VERSION "HNNBNNNYNNNNNNNNNNNNNNNNNNNNNNNNNNNNNNNNNN/4/%%%/4/'%**4NNN///"

NS_ :

BS_:

BU_: Radar MPC2

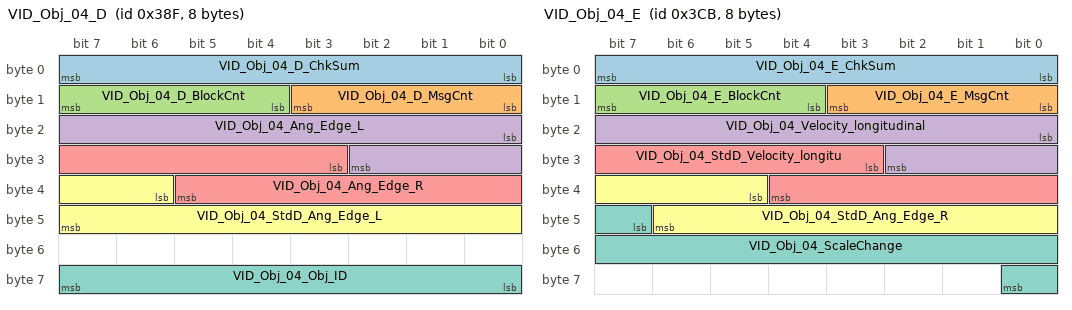
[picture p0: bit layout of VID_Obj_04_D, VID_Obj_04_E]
BO_ 911 VID_Obj_04_D: 8 MPC2
 SG_ VID_Obj_04_D_ChkSum : 0|8@1+ (1,0) [0|255] ""  Radar
 SG_ VID_Obj_04_D_MsgCnt : 8|4@1+ (1,0) [0|15] ""  Radar
 SG_ VID_Obj_04_D_BlockCnt : 12|4@1+ (1,0) [0|15] ""  Radar
 SG_ VID_Obj_04_Ang_Edge_L : 16|11@1+ (0.00048828125,-0.5) [-0.5|0.49951171875] "Unit_Radia"  Radar
 SG_ VID_Obj_04_Ang_Edge_R : 27|11@1+ (0.00048828125,-0.5) [-0.5|0.49951171875] "Unit_Radia"  Radar
 SG_ VID_Obj_04_StdD_Ang_Edge_L : 38|10@1+ (0.00048828125,-0.25) [-0.25|0.24951171875] "Unit_Radia"  Radar
 SG_ VID_Obj_04_Obj_ID : 56|8@1+ (1,0) [1|254] ""  Radar

BO_ 971 VID_Obj_04_E: 8 MPC2
 SG_ VID_Obj_04_E_ChkSum : 0|8@1+ (1,0) [0|255] ""  Radar
 SG_ VID_Obj_04_E_MsgCnt : 8|4@1+ (1,0) [0|15] ""  Radar
 SG_ VID_Obj_04_E_BlockCnt : 12|4@1+ (1,0) [0|15] ""  Radar
 SG_ VID_Obj_04_Velocity_longitudinal : 16|11@1+ (0.01388889,-12) [-12|12.00000192] "Unit_MeterPerSecon"  Radar
 SG_ VID_Obj_04_StdD_Velocity_longitu : 27|10@1+ (0.00694444,0) [0|6.0069406] "Unit_MeterPerSecon"  Radar
 SG_ VID_Obj_04_StdD_Ang_Edge_R : 37|10@1+ (0.00048828125,-0.25) [-0.25|0.24951171875] "Unit_Radia"  Radar
 SG_ VID_Obj_04_ScaleChange : 47|10@1+ (0.001,0.5) [0.5|1.5] ""  Radar

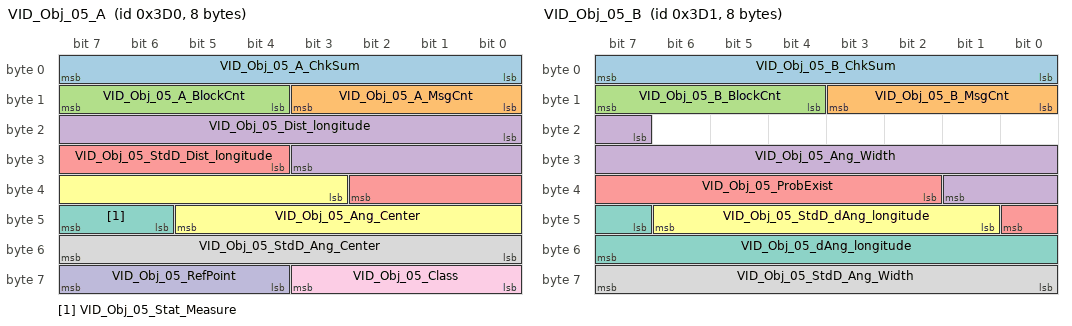
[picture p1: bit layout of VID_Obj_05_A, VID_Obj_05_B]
BO_ 976 VID_Obj_05_A: 8 MPC2
 SG_ VID_Obj_05_A_ChkSum : 0|8@1+ (1,0) [0|255] ""  Radar
 SG_ VID_Obj_05_A_MsgCnt : 8|4@1+ (1,0) [0|15] ""  Radar
 SG_ VID_Obj_05_A_BlockCnt : 12|4@1+ (1,0) [0|15] ""  Radar
 SG_ VID_Obj_05_Dist_longitude : 16|12@1+ (0.0625,0) [0|255.875] "Unit_Meter"  Radar
 SG_ VID_Obj_05_StdD_Dist_longitude : 28|7@1+ (0.25,0) [0|31.5] "Unit_Meter"  Radar
 SG_ VID_Obj_05_Ang_Center : 35|11@1+ (0.00048828125,-0.5) [-0.5|0.4990234375] "Unit_Radia"  Radar
 SG_ VID_Obj_05_Stat_Measure : 46|2@1+ (1,0) [0|3] ""  Radar
 SG_ VID_Obj_05_StdD_Ang_Center : 48|8@1+ (0.0009765625,0) [0|0.248046875] "Unit_Radia"  Radar
 SG_ VID_Obj_05_Class : 56|4@1+ (1,0) [0|15] ""  Radar
 SG_ VID_Obj_05_RefPoint : 60|4@1+ (1,0) [0|15] ""  Radar

BO_ 977 VID_Obj_05_B: 8 MPC2
 SG_ VID_Obj_05_B_ChkSum : 0|8@1+ (1,0) [0|255] ""  Radar
 SG_ VID_Obj_05_B_MsgCnt : 8|4@1+ (1,0) [0|15] ""  Radar
 SG_ VID_Obj_05_B_BlockCnt : 12|4@1+ (1,0) [0|15] ""  Radar
 SG_ VID_Obj_05_Ang_Width : 23|11@1+ (0.00048828125,0) [0|0.9990234375] "Unit_Radia"  Radar
 SG_ VID_Obj_05_ProbExist : 34|7@1+ (0.0078125,0.015625) [0.015625|1] ""  Radar
 SG_ VID_Obj_05_StdD_dAng_longitude : 41|6@1+ (0.01,0) [0|0.62] "Unit_RadiaPerSecon"  Radar
 SG_ VID_Obj_05_dAng_longitude : 47|9@1+ (0.005,-1.25) [-1.25|1.3] "Unit_RadiaPerSecon"  Radar
 SG_ VID_Obj_05_StdD_Ang_Width : 56|8@1+ (0.0009765625,0) [0|0.248046875] "Unit_Radia"  Radar

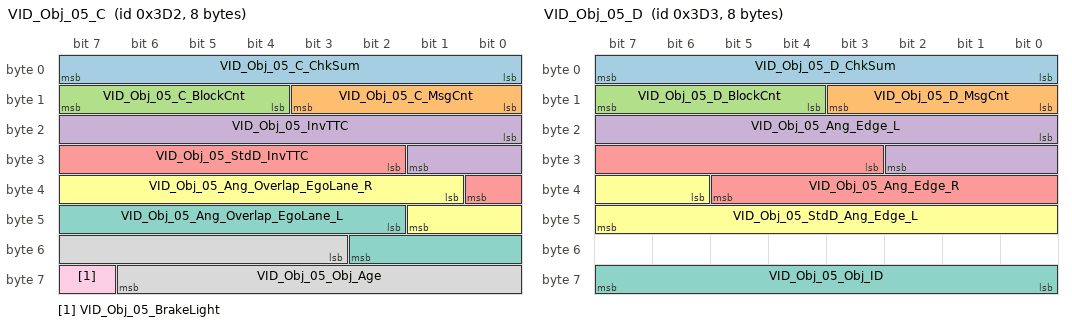
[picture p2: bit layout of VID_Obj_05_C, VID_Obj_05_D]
BO_ 978 VID_Obj_05_C: 8 MPC2
 SG_ VID_Obj_05_C_ChkSum : 0|8@1+ (1,0) [0|255] ""  Radar
 SG_ VID_Obj_05_C_MsgCnt : 8|4@1+ (1,0) [0|15] ""  Radar
 SG_ VID_Obj_05_C_BlockCnt : 12|4@1+ (1,0) [0|15] ""  Radar
 SG_ VID_Obj_05_InvTTC : 16|10@1+ (0.015625,-8) [-8|7.96875] "Unit_Hertz"  Radar
 SG_ VID_Obj_05_StdD_InvTTC : 26|7@1+ (0.0625,0) [0|7.875] "Unit_Hertz"  Radar
 SG_ VID_Obj_05_Ang_Overlap_EgoLane_R : 33|9@1+ (0.0009765625,-0.25) [-0.25|0.248046875] "Unit_Radia"  Radar
 SG_ VID_Obj_05_Ang_Overlap_EgoLane_L : 42|9@1+ (0.0009765625,-0.25) [-0.25|0.248046875] "Unit_Radia"  Radar
 SG_ VID_Obj_05_Obj_Age : 51|12@1+ (1,0) [0|4094] ""  Radar
 SG_ VID_Obj_05_BrakeLight : 63|1@1+ (1,0) [0|1] ""  Radar

BO_ 979 VID_Obj_05_D: 8 MPC2
 SG_ VID_Obj_05_D_ChkSum : 0|8@1+ (1,0) [0|255] ""  Radar
 SG_ VID_Obj_05_D_MsgCnt : 8|4@1+ (1,0) [0|15] ""  Radar
 SG_ VID_Obj_05_D_BlockCnt : 12|4@1+ (1,0) [0|15] ""  Radar
 SG_ VID_Obj_05_Ang_Edge_L : 16|11@1+ (0.00048828125,-0.5) [-0.5|0.49951171875] "Unit_Radia"  Radar
 SG_ VID_Obj_05_Ang_Edge_R : 27|11@1+ (0.00048828125,-0.5) [-0.5|0.49951171875] "Unit_Radia"  Radar
 SG_ VID_Obj_05_StdD_Ang_Edge_L : 38|10@1+ (0.00048828125,-0.25) [-0.25|0.24951171875] "Unit_Radia"  Radar
 SG_ VID_Obj_05_Obj_ID : 56|8@1+ (1,0) [1|254] ""  Radar

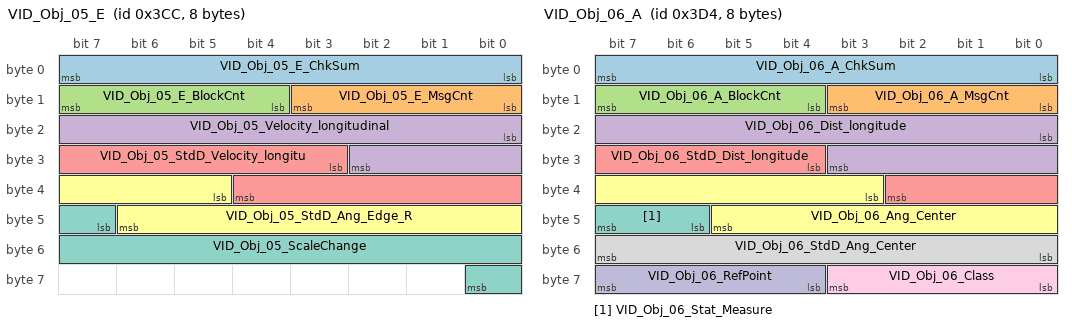
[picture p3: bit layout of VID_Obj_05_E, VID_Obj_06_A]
BO_ 972 VID_Obj_05_E: 8 MPC2
 SG_ VID_Obj_05_E_ChkSum : 0|8@1+ (1,0) [0|255] ""  Radar
 SG_ VID_Obj_05_E_MsgCnt : 8|4@1+ (1,0) [0|15] ""  Radar
 SG_ VID_Obj_05_E_BlockCnt : 12|4@1+ (1,0) [0|15] ""  Radar
 SG_ VID_Obj_05_Velocity_longitudinal : 16|11@1+ (0.01388889,-12) [-12|12.00000192] "Unit_MeterPerSecon"  Radar
 SG_ VID_Obj_05_StdD_Velocity_longitu : 27|10@1+ (0.00694444,0) [0|6.0069406] "Unit_MeterPerSecon"  Radar
 SG_ VID_Obj_05_StdD_Ang_Edge_R : 37|10@1+ (0.00048828125,-0.25) [-0.25|0.24951171875] "Unit_Radia"  Radar
 SG_ VID_Obj_05_ScaleChange : 47|10@1+ (0.001,0.5) [0.5|1.5] ""  Radar

BO_ 980 VID_Obj_06_A: 8 MPC2
 SG_ VID_Obj_06_A_ChkSum : 0|8@1+ (1,0) [0|255] ""  Radar
 SG_ VID_Obj_06_A_MsgCnt : 8|4@1+ (1,0) [0|15] ""  Radar
 SG_ VID_Obj_06_A_BlockCnt : 12|4@1+ (1,0) [0|15] ""  Radar
 SG_ VID_Obj_06_Dist_longitude : 16|12@1+ (0.0625,0) [0|255.875] "Unit_Meter"  Radar
 SG_ VID_Obj_06_StdD_Dist_longitude : 28|7@1+ (0.25,0) [0|31.5] "Unit_Meter"  Radar
 SG_ VID_Obj_06_Ang_Center : 35|11@1+ (0.00048828125,-0.5) [-0.5|0.4990234375] "Unit_Radia"  Radar
 SG_ VID_Obj_06_Stat_Measure : 46|2@1+ (1,0) [0|3] ""  Radar
 SG_ VID_Obj_06_StdD_Ang_Center : 48|8@1+ (0.0009765625,0) [0|0.248046875] "Unit_Radia"  Radar
 SG_ VID_Obj_06_Class : 56|4@1+ (1,0) [0|15] ""  Radar
 SG_ VID_Obj_06_RefPoint : 60|4@1+ (1,0) [0|15] ""  Radar

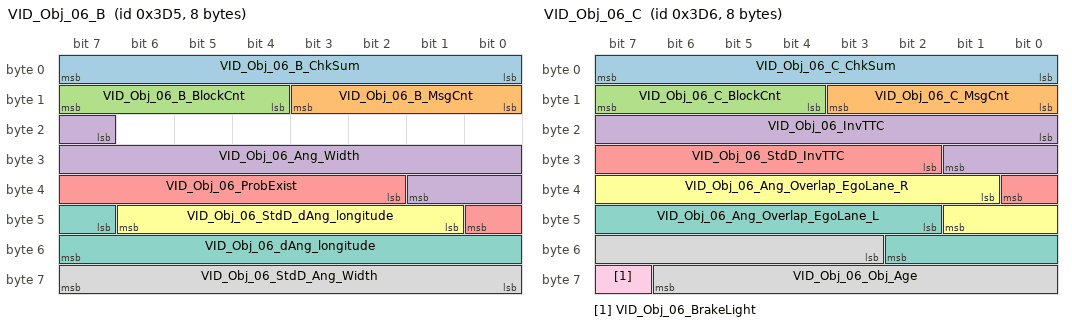
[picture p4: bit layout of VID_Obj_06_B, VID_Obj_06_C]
BO_ 981 VID_Obj_06_B: 8 MPC2
 SG_ VID_Obj_06_B_ChkSum : 0|8@1+ (1,0) [0|255] ""  Radar
 SG_ VID_Obj_06_B_MsgCnt : 8|4@1+ (1,0) [0|15] ""  Radar
 SG_ VID_Obj_06_B_BlockCnt : 12|4@1+ (1,0) [0|15] ""  Radar
 SG_ VID_Obj_06_Ang_Width : 23|11@1+ (0.00048828125,0) [0|0.9990234375] "Unit_Radia"  Radar
 SG_ VID_Obj_06_ProbExist : 34|7@1+ (0.0078125,0.015625) [0.015625|1] ""  Radar
 SG_ VID_Obj_06_StdD_dAng_longitude : 41|6@1+ (0.01,0) [0|0.62] "Unit_RadiaPerSecon"  Radar
 SG_ VID_Obj_06_dAng_longitude : 47|9@1+ (0.005,-1.25) [-1.25|1.3] "Unit_RadiaPerSecon"  Radar
 SG_ VID_Obj_06_StdD_Ang_Width : 56|8@1+ (0.0009765625,0) [0|0.248046875] "Unit_Radia"  Radar

BO_ 982 VID_Obj_06_C: 8 MPC2
 SG_ VID_Obj_06_C_ChkSum : 0|8@1+ (1,0) [0|255] ""  Radar
 SG_ VID_Obj_06_C_MsgCnt : 8|4@1+ (1,0) [0|15] ""  Radar
 SG_ VID_Obj_06_C_BlockCnt : 12|4@1+ (1,0) [0|15] ""  Radar
 SG_ VID_Obj_06_InvTTC : 16|10@1+ (0.015625,-8) [-8|7.96875] "Unit_Hertz"  Radar
 SG_ VID_Obj_06_StdD_InvTTC : 26|7@1+ (0.0625,0) [0|7.875] "Unit_Hertz"  Radar
 SG_ VID_Obj_06_Ang_Overlap_EgoLane_R : 33|9@1+ (0.0009765625,-0.25) [-0.25|0.248046875] "Unit_Radia"  Radar
 SG_ VID_Obj_06_Ang_Overlap_EgoLane_L : 42|9@1+ (0.0009765625,-0.25) [-0.25|0.248046875] "Unit_Radia"  Radar
 SG_ VID_Obj_06_Obj_Age : 51|12@1+ (1,0) [0|4094] ""  Radar
 SG_ VID_Obj_06_BrakeLight : 63|1@1+ (1,0) [0|1] ""  Radar

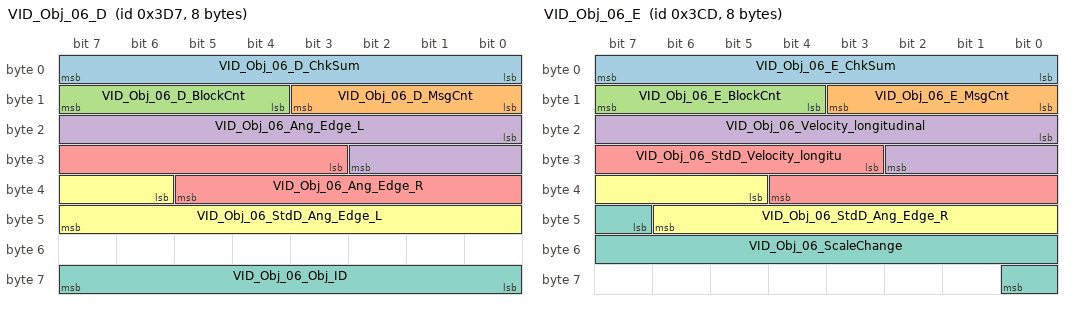
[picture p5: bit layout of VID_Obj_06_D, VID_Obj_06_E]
BO_ 983 VID_Obj_06_D: 8 MPC2
 SG_ VID_Obj_06_D_ChkSum : 0|8@1+ (1,0) [0|255] ""  Radar
 SG_ VID_Obj_06_D_MsgCnt : 8|4@1+ (1,0) [0|15] ""  Radar
 SG_ VID_Obj_06_D_BlockCnt : 12|4@1+ (1,0) [0|15] ""  Radar
 SG_ VID_Obj_06_Ang_Edge_L : 16|11@1+ (0.00048828125,-0.5) [-0.5|0.49951171875] "Unit_Radia"  Radar
 SG_ VID_Obj_06_Ang_Edge_R : 27|11@1+ (0.00048828125,-0.5) [-0.5|0.49951171875] "Unit_Radia"  Radar
 SG_ VID_Obj_06_StdD_Ang_Edge_L : 38|10@1+ (0.00048828125,-0.25) [-0.25|0.24951171875] "Unit_Radia"  Radar
 SG_ VID_Obj_06_Obj_ID : 56|8@1+ (1,0) [1|254] ""  Radar

BO_ 973 VID_Obj_06_E: 8 MPC2
 SG_ VID_Obj_06_E_ChkSum : 0|8@1+ (1,0) [0|255] ""  Radar
 SG_ VID_Obj_06_E_MsgCnt : 8|4@1+ (1,0) [0|15] ""  Radar
 SG_ VID_Obj_06_E_BlockCnt : 12|4@1+ (1,0) [0|15] ""  Radar
 SG_ VID_Obj_06_Velocity_longitudinal : 16|11@1+ (0.01388889,-12) [-12|12.00000192] "Unit_MeterPerSecon"  Radar
 SG_ VID_Obj_06_StdD_Velocity_longitu : 27|10@1+ (0.00694444,0) [0|6.0069406] "Unit_MeterPerSecon"  Radar
 SG_ VID_Obj_06_StdD_Ang_Edge_R : 37|10@1+ (0.00048828125,-0.25) [-0.25|0.24951171875] "Unit_Radia"  Radar
 SG_ VID_Obj_06_ScaleChange : 47|10@1+ (0.001,0.5) [0.5|1.5] ""  Radar

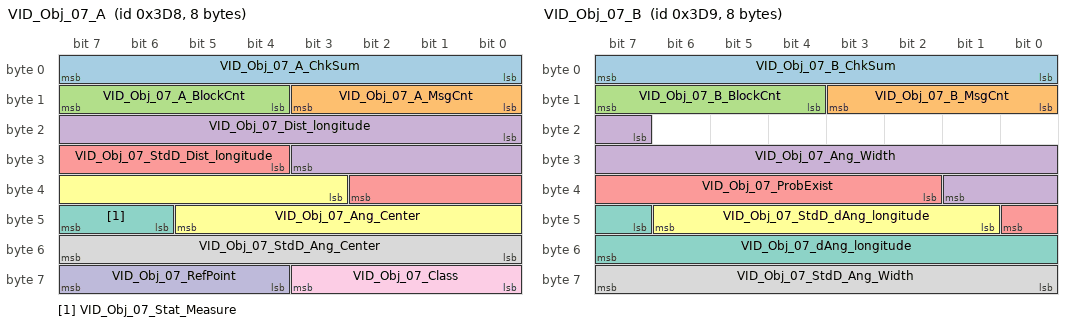
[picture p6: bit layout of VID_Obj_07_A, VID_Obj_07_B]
BO_ 984 VID_Obj_07_A: 8 MPC2
 SG_ VID_Obj_07_A_ChkSum : 0|8@1+ (1,0) [0|255] ""  Radar
 SG_ VID_Obj_07_A_MsgCnt : 8|4@1+ (1,0) [0|15] ""  Radar
 SG_ VID_Obj_07_A_BlockCnt : 12|4@1+ (1,0) [0|15] ""  Radar
 SG_ VID_Obj_07_Dist_longitude : 16|12@1+ (0.0625,0) [0|255.875] "Unit_Meter"  Radar
 SG_ VID_Obj_07_StdD_Dist_longitude : 28|7@1+ (0.25,0) [0|31.5] "Unit_Meter"  Radar
 SG_ VID_Obj_07_Ang_Center : 35|11@1+ (0.00048828125,-0.5) [-0.5|0.4990234375] "Unit_Radia"  Radar
 SG_ VID_Obj_07_Stat_Measure : 46|2@1+ (1,0) [0|3] ""  Radar
 SG_ VID_Obj_07_StdD_Ang_Center : 48|8@1+ (0.0009765625,0) [0|0.248046875] "Unit_Radia"  Radar
 SG_ VID_Obj_07_Class : 56|4@1+ (1,0) [0|15] ""  Radar
 SG_ VID_Obj_07_RefPoint : 60|4@1+ (1,0) [0|15] ""  Radar

BO_ 985 VID_Obj_07_B: 8 MPC2
 SG_ VID_Obj_07_B_ChkSum : 0|8@1+ (1,0) [0|255] ""  Radar
 SG_ VID_Obj_07_B_MsgCnt : 8|4@1+ (1,0) [0|15] ""  Radar
 SG_ VID_Obj_07_B_BlockCnt : 12|4@1+ (1,0) [0|15] ""  Radar
 SG_ VID_Obj_07_Ang_Width : 23|11@1+ (0.00048828125,0) [0|0.9990234375] "Unit_Radia"  Radar
 SG_ VID_Obj_07_ProbExist : 34|7@1+ (0.0078125,0.015625) [0.015625|1] ""  Radar
 SG_ VID_Obj_07_StdD_dAng_longitude : 41|6@1+ (0.01,0) [0|0.62] "Unit_RadiaPerSecon"  Radar
 SG_ VID_Obj_07_dAng_longitude : 47|9@1+ (0.005,-1.25) [-1.25|1.3] "Unit_RadiaPerSecon"  Radar
 SG_ VID_Obj_07_StdD_Ang_Width : 56|8@1+ (0.0009765625,0) [0|0.248046875] "Unit_Radia"  Radar

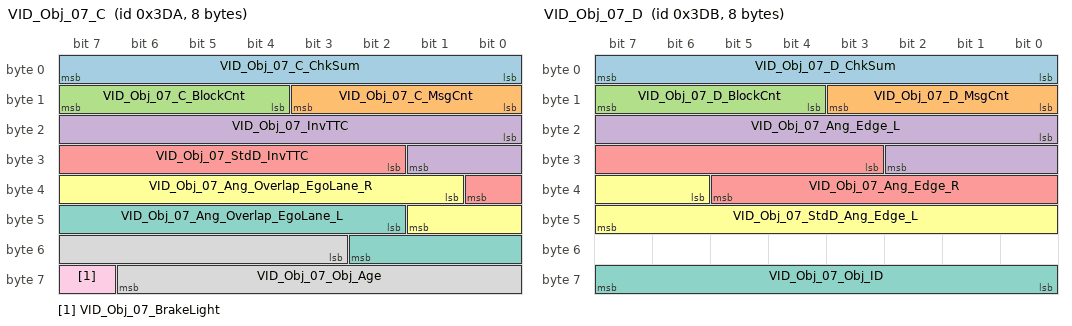
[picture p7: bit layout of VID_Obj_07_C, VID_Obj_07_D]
BO_ 986 VID_Obj_07_C: 8 MPC2
 SG_ VID_Obj_07_C_ChkSum : 0|8@1+ (1,0) [0|255] ""  Radar
 SG_ VID_Obj_07_C_MsgCnt : 8|4@1+ (1,0) [0|15] ""  Radar
 SG_ VID_Obj_07_C_BlockCnt : 12|4@1+ (1,0) [0|15] ""  Radar
 SG_ VID_Obj_07_InvTTC : 16|10@1+ (0.015625,-8) [-8|7.96875] "Unit_Hertz"  Radar
 SG_ VID_Obj_07_StdD_InvTTC : 26|7@1+ (0.0625,0) [0|7.875] "Unit_Hertz"  Radar
 SG_ VID_Obj_07_Ang_Overlap_EgoLane_R : 33|9@1+ (0.0009765625,-0.25) [-0.25|0.248046875] "Unit_Radia"  Radar
 SG_ VID_Obj_07_Ang_Overlap_EgoLane_L : 42|9@1+ (0.0009765625,-0.25) [-0.25|0.248046875] "Unit_Radia"  Radar
 SG_ VID_Obj_07_Obj_Age : 51|12@1+ (1,0) [0|4094] ""  Radar
 SG_ VID_Obj_07_BrakeLight : 63|1@1+ (1,0) [0|1] ""  Radar

BO_ 987 VID_Obj_07_D: 8 MPC2
 SG_ VID_Obj_07_D_ChkSum : 0|8@1+ (1,0) [0|255] ""  Radar
 SG_ VID_Obj_07_D_MsgCnt : 8|4@1+ (1,0) [0|15] ""  Radar
 SG_ VID_Obj_07_D_BlockCnt : 12|4@1+ (1,0) [0|15] ""  Radar
 SG_ VID_Obj_07_Ang_Edge_L : 16|11@1+ (0.00048828125,-0.5) [-0.5|0.49951171875] "Unit_Radia"  Radar
 SG_ VID_Obj_07_Ang_Edge_R : 27|11@1+ (0.00048828125,-0.5) [-0.5|0.49951171875] "Unit_Radia"  Radar
 SG_ VID_Obj_07_StdD_Ang_Edge_L : 38|10@1+ (0.00048828125,-0.25) [-0.25|0.24951171875] "Unit_Radia"  Radar
 SG_ VID_Obj_07_Obj_ID : 56|8@1+ (1,0) [1|254] ""  Radar

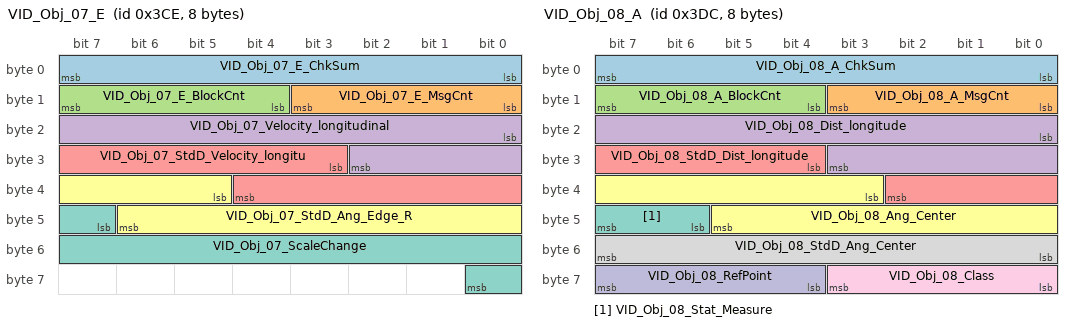
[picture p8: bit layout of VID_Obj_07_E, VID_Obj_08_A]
BO_ 974 VID_Obj_07_E: 8 MPC2
 SG_ VID_Obj_07_E_ChkSum : 0|8@1+ (1,0) [0|255] ""  Radar
 SG_ VID_Obj_07_E_MsgCnt : 8|4@1+ (1,0) [0|15] ""  Radar
 SG_ VID_Obj_07_E_BlockCnt : 12|4@1+ (1,0) [0|15] ""  Radar
 SG_ VID_Obj_07_Velocity_longitudinal : 16|11@1+ (0.01388889,-12) [-12|12.00000192] "Unit_MeterPerSecon"  Radar
 SG_ VID_Obj_07_StdD_Velocity_longitu : 27|10@1+ (0.00694444,0) [0|6.0069406] "Unit_MeterPerSecon"  Radar
 SG_ VID_Obj_07_StdD_Ang_Edge_R : 37|10@1+ (0.00048828125,-0.25) [-0.25|0.24951171875] "Unit_Radia"  Radar
 SG_ VID_Obj_07_ScaleChange : 47|10@1+ (0.001,0.5) [0.5|1.5] ""  Radar

BO_ 988 VID_Obj_08_A: 8 MPC2
 SG_ VID_Obj_08_A_ChkSum : 0|8@1+ (1,0) [0|255] ""  Radar
 SG_ VID_Obj_08_A_MsgCnt : 8|4@1+ (1,0) [0|15] ""  Radar
 SG_ VID_Obj_08_A_BlockCnt : 12|4@1+ (1,0) [0|15] ""  Radar
 SG_ VID_Obj_08_Dist_longitude : 16|12@1+ (0.0625,0) [0|255.875] "Unit_Meter"  Radar
 SG_ VID_Obj_08_StdD_Dist_longitude : 28|7@1+ (0.25,0) [0|31.5] "Unit_Meter"  Radar
 SG_ VID_Obj_08_Ang_Center : 35|11@1+ (0.00048828125,-0.5) [-0.5|0.4990234375] "Unit_Radia"  Radar
 SG_ VID_Obj_08_Stat_Measure : 46|2@1+ (1,0) [0|3] ""  Radar
 SG_ VID_Obj_08_StdD_Ang_Center : 48|8@1+ (0.0009765625,0) [0|0.248046875] "Unit_Radia"  Radar
 SG_ VID_Obj_08_Class : 56|4@1+ (1,0) [0|15] ""  Radar
 SG_ VID_Obj_08_RefPoint : 60|4@1+ (1,0) [0|15] ""  Radar

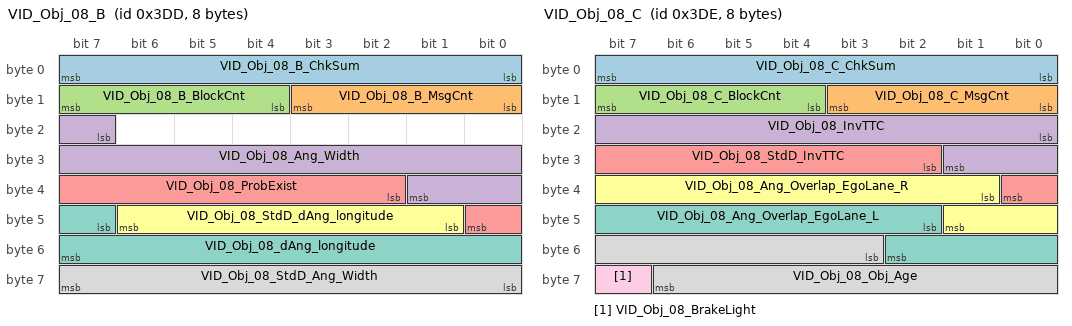
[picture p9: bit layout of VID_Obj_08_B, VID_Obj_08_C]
BO_ 989 VID_Obj_08_B: 8 MPC2
 SG_ VID_Obj_08_B_ChkSum : 0|8@1+ (1,0) [0|255] ""  Radar
 SG_ VID_Obj_08_B_MsgCnt : 8|4@1+ (1,0) [0|15] ""  Radar
 SG_ VID_Obj_08_B_BlockCnt : 12|4@1+ (1,0) [0|15] ""  Radar
 SG_ VID_Obj_08_Ang_Width : 23|11@1+ (0.00048828125,0) [0|0.9990234375] "Unit_Radia"  Radar
 SG_ VID_Obj_08_ProbExist : 34|7@1+ (0.0078125,0.015625) [0.015625|1] ""  Radar
 SG_ VID_Obj_08_StdD_dAng_longitude : 41|6@1+ (0.01,0) [0|0.62] "Unit_RadiaPerSecon"  Radar
 SG_ VID_Obj_08_dAng_longitude : 47|9@1+ (0.005,-1.25) [-1.25|1.3] "Unit_RadiaPerSecon"  Radar
 SG_ VID_Obj_08_StdD_Ang_Width : 56|8@1+ (0.0009765625,0) [0|0.248046875] "Unit_Radia"  Radar

BO_ 990 VID_Obj_08_C: 8 MPC2
 SG_ VID_Obj_08_C_ChkSum : 0|8@1+ (1,0) [0|255] ""  Radar
 SG_ VID_Obj_08_C_MsgCnt : 8|4@1+ (1,0) [0|15] ""  Radar
 SG_ VID_Obj_08_C_BlockCnt : 12|4@1+ (1,0) [0|15] ""  Radar
 SG_ VID_Obj_08_InvTTC : 16|10@1+ (0.015625,-8) [-8|7.96875] "Unit_Hertz"  Radar
 SG_ VID_Obj_08_StdD_InvTTC : 26|7@1+ (0.0625,0) [0|7.875] "Unit_Hertz"  Radar
 SG_ VID_Obj_08_Ang_Overlap_EgoLane_R : 33|9@1+ (0.0009765625,-0.25) [-0.25|0.248046875] "Unit_Radia"  Radar
 SG_ VID_Obj_08_Ang_Overlap_EgoLane_L : 42|9@1+ (0.0009765625,-0.25) [-0.25|0.248046875] "Unit_Radia"  Radar
 SG_ VID_Obj_08_Obj_Age : 51|12@1+ (1,0) [0|4094] ""  Radar
 SG_ VID_Obj_08_BrakeLight : 63|1@1+ (1,0) [0|1] ""  Radar

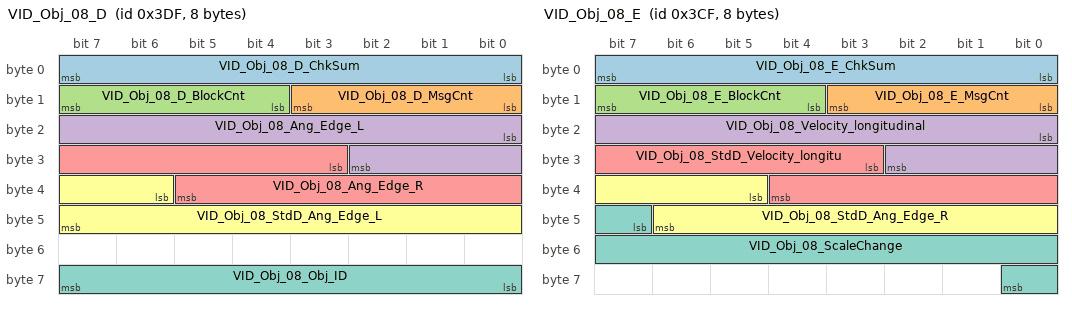
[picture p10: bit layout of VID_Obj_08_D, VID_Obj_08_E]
BO_ 991 VID_Obj_08_D: 8 MPC2
 SG_ VID_Obj_08_D_ChkSum : 0|8@1+ (1,0) [0|255] ""  Radar
 SG_ VID_Obj_08_D_MsgCnt : 8|4@1+ (1,0) [0|15] ""  Radar
 SG_ VID_Obj_08_D_BlockCnt : 12|4@1+ (1,0) [0|15] ""  Radar
 SG_ VID_Obj_08_Ang_Edge_L : 16|11@1+ (0.00048828125,-0.5) [-0.5|0.49951171875] "Unit_Radia"  Radar
 SG_ VID_Obj_08_Ang_Edge_R : 27|11@1+ (0.00048828125,-0.5) [-0.5|0.49951171875] "Unit_Radia"  Radar
 SG_ VID_Obj_08_StdD_Ang_Edge_L : 38|10@1+ (0.00048828125,-0.25) [-0.25|0.24951171875] "Unit_Radia"  Radar
 SG_ VID_Obj_08_Obj_ID : 56|8@1+ (1,0) [1|254] ""  Radar

BO_ 975 VID_Obj_08_E: 8 MPC2
 SG_ VID_Obj_08_E_ChkSum : 0|8@1+ (1,0) [0|255] ""  Radar
 SG_ VID_Obj_08_E_MsgCnt : 8|4@1+ (1,0) [0|15] ""  Radar
 SG_ VID_Obj_08_E_BlockCnt : 12|4@1+ (1,0) [0|15] ""  Radar
 SG_ VID_Obj_08_Velocity_longitudinal : 16|11@1+ (0.01388889,-12) [-12|12.00000192] "Unit_MeterPerSecon"  Radar
 SG_ VID_Obj_08_StdD_Velocity_longitu : 27|10@1+ (0.00694444,0) [0|6.0069406] "Unit_MeterPerSecon"  Radar
 SG_ VID_Obj_08_StdD_Ang_Edge_R : 37|10@1+ (0.00048828125,-0.25) [-0.25|0.24951171875] "Unit_Radia"  Radar
 SG_ VID_Obj_08_ScaleChange : 47|10@1+ (0.001,0.5) [0.5|1.5] ""  Radar

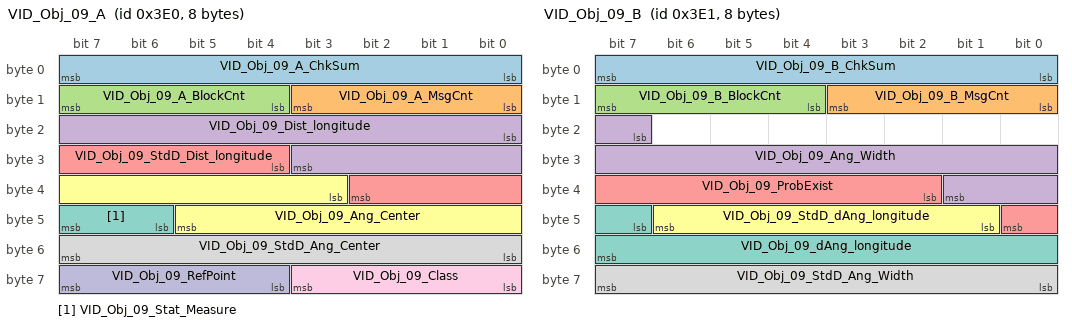
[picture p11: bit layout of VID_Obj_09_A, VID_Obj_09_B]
BO_ 992 VID_Obj_09_A: 8 MPC2
 SG_ VID_Obj_09_A_ChkSum : 0|8@1+ (1,0) [0|255] ""  Radar
 SG_ VID_Obj_09_A_MsgCnt : 8|4@1+ (1,0) [0|15] ""  Radar
 SG_ VID_Obj_09_A_BlockCnt : 12|4@1+ (1,0) [0|15] ""  Radar
 SG_ VID_Obj_09_Dist_longitude : 16|12@1+ (0.0625,0) [0|255.875] "Unit_Meter"  Radar
 SG_ VID_Obj_09_StdD_Dist_longitude : 28|7@1+ (0.25,0) [0|31.5] "Unit_Meter"  Radar
 SG_ VID_Obj_09_Ang_Center : 35|11@1+ (0.00048828125,-0.5) [-0.5|0.4990234375] "Unit_Radia"  Radar
 SG_ VID_Obj_09_Stat_Measure : 46|2@1+ (1,0) [0|3] ""  Radar
 SG_ VID_Obj_09_StdD_Ang_Center : 48|8@1+ (0.0009765625,0) [0|0.248046875] "Unit_Radia"  Radar
 SG_ VID_Obj_09_Class : 56|4@1+ (1,0) [0|15] ""  Radar
 SG_ VID_Obj_09_RefPoint : 60|4@1+ (1,0) [0|15] ""  Radar

BO_ 993 VID_Obj_09_B: 8 MPC2
 SG_ VID_Obj_09_B_ChkSum : 0|8@1+ (1,0) [0|255] ""  Radar
 SG_ VID_Obj_09_B_MsgCnt : 8|4@1+ (1,0) [0|15] ""  Radar
 SG_ VID_Obj_09_B_BlockCnt : 12|4@1+ (1,0) [0|15] ""  Radar
 SG_ VID_Obj_09_Ang_Width : 23|11@1+ (0.00048828125,0) [0|0.9990234375] "Unit_Radia"  Radar
 SG_ VID_Obj_09_ProbExist : 34|7@1+ (0.0078125,0.015625) [0.015625|1] ""  Radar
 SG_ VID_Obj_09_StdD_dAng_longitude : 41|6@1+ (0.01,0) [0|0.62] "Unit_RadiaPerSecon"  Radar
 SG_ VID_Obj_09_dAng_longitude : 47|9@1+ (0.005,-1.25) [-1.25|1.3] "Unit_RadiaPerSecon"  Radar
 SG_ VID_Obj_09_StdD_Ang_Width : 56|8@1+ (0.0009765625,0) [0|0.248046875] "Unit_Radia"  Radar

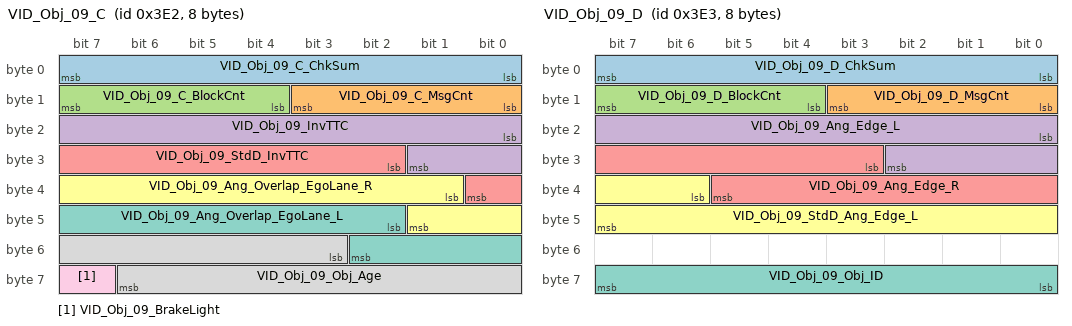
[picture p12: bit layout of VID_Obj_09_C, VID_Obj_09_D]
BO_ 994 VID_Obj_09_C: 8 MPC2
 SG_ VID_Obj_09_C_ChkSum : 0|8@1+ (1,0) [0|255] ""  Radar
 SG_ VID_Obj_09_C_MsgCnt : 8|4@1+ (1,0) [0|15] ""  Radar
 SG_ VID_Obj_09_C_BlockCnt : 12|4@1+ (1,0) [0|15] ""  Radar
 SG_ VID_Obj_09_InvTTC : 16|10@1+ (0.015625,-8) [-8|7.96875] "Unit_Hertz"  Radar
 SG_ VID_Obj_09_StdD_InvTTC : 26|7@1+ (0.0625,0) [0|7.875] "Unit_Hertz"  Radar
 SG_ VID_Obj_09_Ang_Overlap_EgoLane_R : 33|9@1+ (0.0009765625,-0.25) [-0.25|0.248046875] "Unit_Radia"  Radar
 SG_ VID_Obj_09_Ang_Overlap_EgoLane_L : 42|9@1+ (0.0009765625,-0.25) [-0.25|0.248046875] "Unit_Radia"  Radar
 SG_ VID_Obj_09_Obj_Age : 51|12@1+ (1,0) [0|4094] ""  Radar
 SG_ VID_Obj_09_BrakeLight : 63|1@1+ (1,0) [0|1] ""  Radar

BO_ 995 VID_Obj_09_D: 8 MPC2
 SG_ VID_Obj_09_D_ChkSum : 0|8@1+ (1,0) [0|255] ""  Radar
 SG_ VID_Obj_09_D_MsgCnt : 8|4@1+ (1,0) [0|15] ""  Radar
 SG_ VID_Obj_09_D_BlockCnt : 12|4@1+ (1,0) [0|15] ""  Radar
 SG_ VID_Obj_09_Ang_Edge_L : 16|11@1+ (0.00048828125,-0.5) [-0.5|0.49951171875] "Unit_Radia"  Radar
 SG_ VID_Obj_09_Ang_Edge_R : 27|11@1+ (0.00048828125,-0.5) [-0.5|0.49951171875] "Unit_Radia"  Radar
 SG_ VID_Obj_09_StdD_Ang_Edge_L : 38|10@1+ (0.00048828125,-0.25) [-0.25|0.24951171875] "Unit_Radia"  Radar
 SG_ VID_Obj_09_Obj_ID : 56|8@1+ (1,0) [1|254] ""  Radar

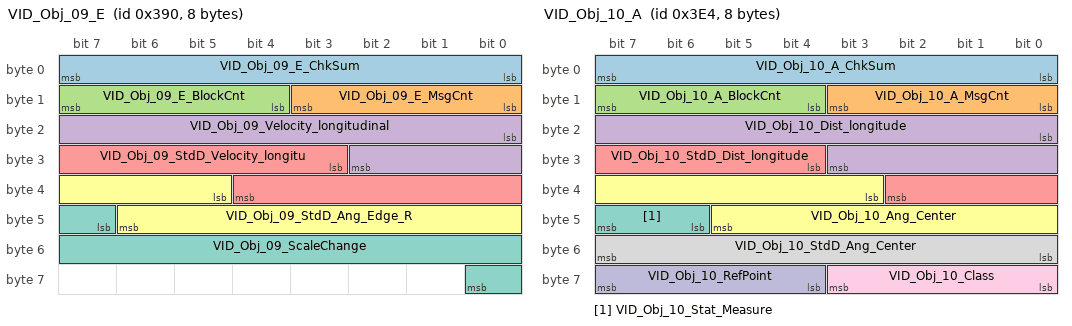
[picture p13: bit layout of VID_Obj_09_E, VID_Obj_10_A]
BO_ 912 VID_Obj_09_E: 8 MPC2
 SG_ VID_Obj_09_E_ChkSum : 0|8@1+ (1,0) [0|255] ""  Radar
 SG_ VID_Obj_09_E_MsgCnt : 8|4@1+ (1,0) [0|15] ""  Radar
 SG_ VID_Obj_09_E_BlockCnt : 12|4@1+ (1,0) [0|15] ""  Radar
 SG_ VID_Obj_09_Velocity_longitudinal : 16|11@1+ (0.01388889,-12) [-12|12.00000192] "Unit_MeterPerSecon"  Radar
 SG_ VID_Obj_09_StdD_Velocity_longitu : 27|10@1+ (0.00694444,0) [0|6.0069406] "Unit_MeterPerSecon"  Radar
 SG_ VID_Obj_09_StdD_Ang_Edge_R : 37|10@1+ (0.00048828125,-0.25) [-0.25|0.24951171875] "Unit_Radia"  Radar
 SG_ VID_Obj_09_ScaleChange : 47|10@1+ (0.001,0.5) [0.5|1.5] ""  Radar

BO_ 996 VID_Obj_10_A: 8 MPC2
 SG_ VID_Obj_10_A_ChkSum : 0|8@1+ (1,0) [0|255] ""  Radar
 SG_ VID_Obj_10_A_MsgCnt : 8|4@1+ (1,0) [0|15] ""  Radar
 SG_ VID_Obj_10_A_BlockCnt : 12|4@1+ (1,0) [0|15] ""  Radar
 SG_ VID_Obj_10_Dist_longitude : 16|12@1+ (0.0625,0) [0|255.875] "Unit_Meter"  Radar
 SG_ VID_Obj_10_StdD_Dist_longitude : 28|7@1+ (0.25,0) [0|31.5] "Unit_Meter"  Radar
 SG_ VID_Obj_10_Ang_Center : 35|11@1+ (0.00048828125,-0.5) [-0.5|0.4990234375] "Unit_Radia"  Radar
 SG_ VID_Obj_10_Stat_Measure : 46|2@1+ (1,0) [0|3] ""  Radar
 SG_ VID_Obj_10_StdD_Ang_Center : 48|8@1+ (0.0009765625,0) [0|0.248046875] "Unit_Radia"  Radar
 SG_ VID_Obj_10_Class : 56|4@1+ (1,0) [0|15] ""  Radar
 SG_ VID_Obj_10_RefPoint : 60|4@1+ (1,0) [0|15] ""  Radar

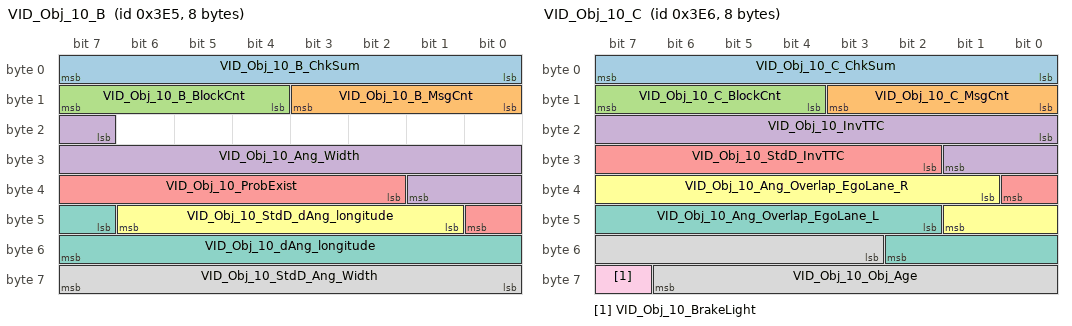
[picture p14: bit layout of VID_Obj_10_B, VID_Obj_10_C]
BO_ 997 VID_Obj_10_B: 8 MPC2
 SG_ VID_Obj_10_B_ChkSum : 0|8@1+ (1,0) [0|255] ""  Radar
 SG_ VID_Obj_10_B_MsgCnt : 8|4@1+ (1,0) [0|15] ""  Radar
 SG_ VID_Obj_10_B_BlockCnt : 12|4@1+ (1,0) [0|15] ""  Radar
 SG_ VID_Obj_10_Ang_Width : 23|11@1+ (0.00048828125,0) [0|0.9990234375] "Unit_Radia"  Radar
 SG_ VID_Obj_10_ProbExist : 34|7@1+ (0.0078125,0.015625) [0.015625|1] ""  Radar
 SG_ VID_Obj_10_StdD_dAng_longitude : 41|6@1+ (0.01,0) [0|0.62] "Unit_RadiaPerSecon"  Radar
 SG_ VID_Obj_10_dAng_longitude : 47|9@1+ (0.005,-1.25) [-1.25|1.3] "Unit_RadiaPerSecon"  Radar
 SG_ VID_Obj_10_StdD_Ang_Width : 56|8@1+ (0.0009765625,0) [0|0.248046875] "Unit_Radia"  Radar

BO_ 998 VID_Obj_10_C: 8 MPC2
 SG_ VID_Obj_10_C_ChkSum : 0|8@1+ (1,0) [0|255] ""  Radar
 SG_ VID_Obj_10_C_MsgCnt : 8|4@1+ (1,0) [0|15] ""  Radar
 SG_ VID_Obj_10_C_BlockCnt : 12|4@1+ (1,0) [0|15] ""  Radar
 SG_ VID_Obj_10_InvTTC : 16|10@1+ (0.015625,-8) [-8|7.96875] "Unit_Hertz"  Radar
 SG_ VID_Obj_10_StdD_InvTTC : 26|7@1+ (0.0625,0) [0|7.875] "Unit_Hertz"  Radar
 SG_ VID_Obj_10_Ang_Overlap_EgoLane_R : 33|9@1+ (0.0009765625,-0.25) [-0.25|0.248046875] "Unit_Radia"  Radar
 SG_ VID_Obj_10_Ang_Overlap_EgoLane_L : 42|9@1+ (0.0009765625,-0.25) [-0.25|0.248046875] "Unit_Radia"  Radar
 SG_ VID_Obj_10_Obj_Age : 51|12@1+ (1,0) [0|4094] ""  Radar
 SG_ VID_Obj_10_BrakeLight : 63|1@1+ (1,0) [0|1] ""  Radar

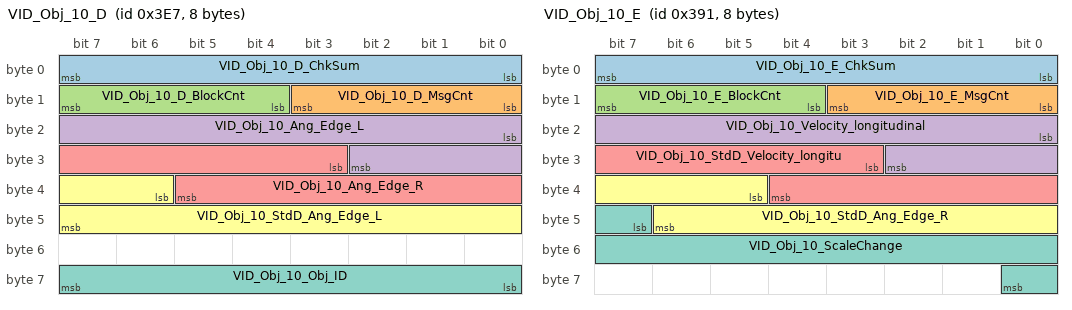
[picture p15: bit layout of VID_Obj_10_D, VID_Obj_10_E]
BO_ 999 VID_Obj_10_D: 8 MPC2
 SG_ VID_Obj_10_D_ChkSum : 0|8@1+ (1,0) [0|255] ""  Radar
 SG_ VID_Obj_10_D_MsgCnt : 8|4@1+ (1,0) [0|15] ""  Radar
 SG_ VID_Obj_10_D_BlockCnt : 12|4@1+ (1,0) [0|15] ""  Radar
 SG_ VID_Obj_10_Ang_Edge_L : 16|11@1+ (0.00048828125,-0.5) [-0.5|0.49951171875] "Unit_Radia"  Radar
 SG_ VID_Obj_10_Ang_Edge_R : 27|11@1+ (0.00048828125,-0.5) [-0.5|0.49951171875] "Unit_Radia"  Radar
 SG_ VID_Obj_10_StdD_Ang_Edge_L : 38|10@1+ (0.00048828125,-0.25) [-0.25|0.24951171875] "Unit_Radia"  Radar
 SG_ VID_Obj_10_Obj_ID : 56|8@1+ (1,0) [1|254] ""  Radar

BO_ 913 VID_Obj_10_E: 8 MPC2
 SG_ VID_Obj_10_E_ChkSum : 0|8@1+ (1,0) [0|255] ""  Radar
 SG_ VID_Obj_10_E_MsgCnt : 8|4@1+ (1,0) [0|15] ""  Radar
 SG_ VID_Obj_10_E_BlockCnt : 12|4@1+ (1,0) [0|15] ""  Radar
 SG_ VID_Obj_10_Velocity_longitudinal : 16|11@1+ (0.01388889,-12) [-12|12.00000192] "Unit_MeterPerSecon"  Radar
 SG_ VID_Obj_10_StdD_Velocity_longitu : 27|10@1+ (0.00694444,0) [0|6.0069406] "Unit_MeterPerSecon"  Radar
 SG_ VID_Obj_10_StdD_Ang_Edge_R : 37|10@1+ (0.00048828125,-0.25) [-0.25|0.24951171875] "Unit_Radia"  Radar
 SG_ VID_Obj_10_ScaleChange : 47|10@1+ (0.001,0.5) [0.5|1.5] ""  Radar

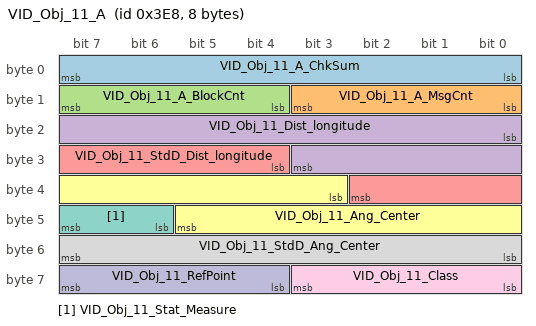
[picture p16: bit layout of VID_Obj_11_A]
BO_ 1000 VID_Obj_11_A: 8 MPC2
 SG_ VID_Obj_11_A_ChkSum : 0|8@1+ (1,0) [0|255] ""  Radar
 SG_ VID_Obj_11_A_MsgCnt : 8|4@1+ (1,0) [0|15] ""  Radar
 SG_ VID_Obj_11_A_BlockCnt : 12|4@1+ (1,0) [0|15] ""  Radar
 SG_ VID_Obj_11_Dist_longitude : 16|12@1+ (0.0625,0) [0|255.875] "Unit_Meter"  Radar
 SG_ VID_Obj_11_StdD_Dist_longitude : 28|7@1+ (0.25,0) [0|31.5] "Unit_Meter"  Radar
 SG_ VID_Obj_11_Ang_Center : 35|11@1+ (0.00048828125,-0.5) [-0.5|0.4990234375] "Unit_Radia"  Radar
 SG_ VID_Obj_11_Stat_Measure : 46|2@1+ (1,0) [0|3] ""  Radar
 SG_ VID_Obj_11_StdD_Ang_Center : 48|8@1+ (0.0009765625,0) [0|0.248046875] "Unit_Radia"  Radar
 SG_ VID_Obj_11_Class : 56|4@1+ (1,0) [0|15] ""  Radar
 SG_ VID_Obj_11_RefPoint : 60|4@1+ (1,0) [0|15] ""  Radar

CM_ SG_ 911 VID_Obj_04_D_ChkSum "CRC8 Checksum";
CM_ SG_ 911 VID_Obj_04_D_MsgCnt "Message counter (rolling counter)";
CM_ SG_ 911 VID_Obj_04_D_BlockCnt "Control signal to synchronize segmented blocks of object data";
CM_ SG_ 911 VID_Obj_04_Ang_Edge_L "Angle of the left edge of the object
Conversion factor 2^-11";
CM_ SG_ 911 VID_Obj_04_Ang_Edge_R "Angle of the right edge of the object
Conversion factor 2^-11";
CM_ SG_ 911 VID_Obj_04_StdD_Ang_Edge_L "Standard deviation for the Angle of the left edge of the object";
CM_ SG_ 911 VID_Obj_04_Obj_ID "ID of the object";
CM_ SG_ 971 VID_Obj_04_E_ChkSum "CRC8 Checksum";
CM_ SG_ 971 VID_Obj_04_E_MsgCnt "Message counter (rolling counter)";
CM_ SG_ 971 VID_Obj_04_E_BlockCnt "Control signal to synchronize segmented blocks of object data";
CM_ SG_ 971 VID_Obj_04_Velocity_longitudinal "Longitudinal velocity of the detected object (Vehicle coordinate system)";
CM_ SG_ 971 VID_Obj_04_StdD_Velocity_longitu "Standard deviation of the Longitudinal velocity of the detected object (Vehicle coordinate system)";
CM_ SG_ 971 VID_Obj_04_StdD_Ang_Edge_R "Standard deviation for the Angle of the right edge of the object";
CM_ SG_ 971 VID_Obj_04_ScaleChange "In order to fuse a video object with a radar object at higher distance (>60m), a higher resolution for the  relative velocity is needed in that range. This signal indicates the required change of the scale.";
CM_ SG_ 976 VID_Obj_05_A_ChkSum "CRC8 Checksum";
CM_ SG_ 976 VID_Obj_05_A_MsgCnt "Message counter (rolling counter)";
CM_ SG_ 976 VID_Obj_05_A_BlockCnt "Control signal to synchronize segmented blocks of object data";
CM_ SG_ 976 VID_Obj_05_Dist_longitude "Longitudinal distance relative to vehicle coordinate system";
CM_ SG_ 976 VID_Obj_05_StdD_Dist_longitude "Standard deviation for VID_Obj_05_Dist_longitude";
CM_ SG_ 976 VID_Obj_05_Ang_Center "Center of the recorded side of the 3D-object box (positive angle left of x-axis).
(Mono-Video: Rear view for vehicles). In combination with Obj_Angle_low the center
base point of the objectis described.
Coordinate system: transformed";
CM_ SG_ 976 VID_Obj_05_Stat_Measure "Object measured tracked

0 Object not measured but predicted based on 3D-model
1 Object was measured in current sample cycle
2 Object not measured but re-matched based on feature tracking";
CM_ SG_ 976 VID_Obj_05_StdD_Ang_Center "Standard deviation for VID_Obj_05_Ang_Center";
CM_ SG_ 976 VID_Obj_05_Class "Object class";
CM_ SG_ 976 VID_Obj_05_RefPoint "Index of the reference point for the 3D-object box
Info: The wording front/rear right/left relates to the indicated object orientation.
If this data is not available then a orienntation can be chosen.";
CM_ SG_ 977 VID_Obj_05_B_ChkSum "CRC8 Checksum";
CM_ SG_ 977 VID_Obj_05_B_MsgCnt "Message counter (rolling counter)";
CM_ SG_ 977 VID_Obj_05_B_BlockCnt "Control signal to synchronize segmented blocks of object data";
CM_ SG_ 977 VID_Obj_05_Ang_Width "Width of the recorded side of the 3D-object box (positive angle left of x-axis)
Monovideo: Rear view for vehicles
Coordinate system: Transformed coordinate system with camera being origin
! Ego-movement has to be compensated !";
CM_ SG_ 977 VID_Obj_05_ProbExist "Probability for the existence of an object for the given time and position (in 3sigma-area)";
CM_ SG_ 977 VID_Obj_05_StdD_dAng_longitude "Standard deviation for VID_Obj_05_dAng_longitude";
CM_ SG_ 977 VID_Obj_05_dAng_longitude "Lateral velocity of the object (related to the reference point), calculated as change of angle in the frame";
CM_ SG_ 977 VID_Obj_05_StdD_Ang_Width "Standard deviation for VID_Obj_05_Ang_Width";
CM_ SG_ 978 VID_Obj_05_C_ChkSum "CRC8 Checksum";
CM_ SG_ 978 VID_Obj_05_C_MsgCnt "Message counter (rolling counter)";
CM_ SG_ 978 VID_Obj_05_C_BlockCnt "Control signal to synchronize segmented blocks of object data";
CM_ SG_ 978 VID_Obj_05_InvTTC "Inverted value of the time-to-collision with the vertical plane of the camera ";
CM_ SG_ 978 VID_Obj_05_StdD_InvTTC "Standard deviation for VID_Obj_05_InvTTC";
CM_ SG_ 978 VID_Obj_05_Ang_Overlap_EgoLane_R "Object Line Assignment (angle based indicator for the overlap of a an object with the ego lane from the right corner)";
CM_ SG_ 978 VID_Obj_05_Ang_Overlap_EgoLane_L "Object Line Assignment (angle based indicator for the overlap of a an object with the ego lane from the left corner)";
CM_ SG_ 978 VID_Obj_05_Obj_Age "Cycle counter for the existence of the object (object sampled)";
CM_ SG_ 978 VID_Obj_05_BrakeLight "Brake light recognized on the object";
CM_ SG_ 979 VID_Obj_05_D_ChkSum "CRC8 Checksum";
CM_ SG_ 979 VID_Obj_05_D_MsgCnt "Message counter (rolling counter)";
CM_ SG_ 979 VID_Obj_05_D_BlockCnt "Control signal to synchronize segmented blocks of object data";
CM_ SG_ 979 VID_Obj_05_Ang_Edge_L "Angle of the left edge of the object
Conversion factor 2^-11";
CM_ SG_ 979 VID_Obj_05_Ang_Edge_R "Angle of the right edge of the object
Conversion factor 2^-11";
CM_ SG_ 979 VID_Obj_05_StdD_Ang_Edge_L "Standard deviation for the Angle of the left edge of the object";
CM_ SG_ 979 VID_Obj_05_Obj_ID "ID of the object";
CM_ SG_ 972 VID_Obj_05_E_ChkSum "CRC8 Checksum";
CM_ SG_ 972 VID_Obj_05_E_MsgCnt "Message counter (rolling counter)";
CM_ SG_ 972 VID_Obj_05_E_BlockCnt "Control signal to synchronize segmented blocks of object data";
CM_ SG_ 972 VID_Obj_05_Velocity_longitudinal "Longitudinal velocity of the detected object (Vehicle coordinate system)";
CM_ SG_ 972 VID_Obj_05_StdD_Velocity_longitu "Standard deviation of the Longitudinal velocity of the detected object (Vehicle coordinate system)";
CM_ SG_ 972 VID_Obj_05_StdD_Ang_Edge_R "Standard deviation for the Angle of the right edge of the object";
CM_ SG_ 972 VID_Obj_05_ScaleChange "In order to fuse a video object with a radar object at higher distance (>60m), a higher resolution for the  relative velocity is needed in that range. This signal indicates the required change of the scale.";
CM_ SG_ 980 VID_Obj_06_A_ChkSum "CRC8 Checksum";
CM_ SG_ 980 VID_Obj_06_A_MsgCnt "Message counter (rolling counter)";
CM_ SG_ 980 VID_Obj_06_A_BlockCnt "Control signal to synchronize segmented blocks of object data";
CM_ SG_ 980 VID_Obj_06_Dist_longitude "Longitudinal distance relative to vehicle coordinate system";
CM_ SG_ 980 VID_Obj_06_StdD_Dist_longitude "Standard deviation for VID_Obj_06_Dist_longitude";
CM_ SG_ 980 VID_Obj_06_Ang_Center "Center of the recorded side of the 3D-object box (positive angle left of x-axis).
(Mono-Video: Rear view for vehicles). In combination with Obj_Angle_low the center
base point of the objectis described.
Coordinate system: transformed";
CM_ SG_ 980 VID_Obj_06_Stat_Measure "Object measured tracked

0 Object not measured but predicted based on 3D-model
1 Object was measured in current sample cycle
2 Object not measured but re-matched based on feature tracking";
CM_ SG_ 980 VID_Obj_06_StdD_Ang_Center "Standard deviation for VID_Obj_06_Ang_Center";
CM_ SG_ 980 VID_Obj_06_Class "Object class";
CM_ SG_ 980 VID_Obj_06_RefPoint "Index of the reference point for the 3D-object box
Info: The wording front/rear right/left relates to the indicated object orientation.
If this data is not available then a orienntation can be chosen.";
CM_ SG_ 981 VID_Obj_06_B_ChkSum "CRC8 Checksum";
CM_ SG_ 981 VID_Obj_06_B_MsgCnt "Message counter (rolling counter)";
CM_ SG_ 981 VID_Obj_06_B_BlockCnt "Control signal to synchronize segmented blocks of object data";
CM_ SG_ 981 VID_Obj_06_Ang_Width "Width of the recorded side of the 3D-object box (positive angle left of x-axis)
Monovideo: Rear view for vehicles
Coordinate system: Transformed coordinate system with camera being origin
! Ego-movement has to be compensated !";
CM_ SG_ 981 VID_Obj_06_ProbExist "Probability for the existence of an object for the given time and position (in 3sigma-area)";
CM_ SG_ 981 VID_Obj_06_StdD_dAng_longitude "Standard deviation for VID_Obj_06_dAng_longitude";
CM_ SG_ 981 VID_Obj_06_dAng_longitude "Lateral velocity of the object (related to the reference point), calculated as change of angle in the frame";
CM_ SG_ 981 VID_Obj_06_StdD_Ang_Width "Standard deviation for VID_Obj_06_Ang_Width";
CM_ SG_ 982 VID_Obj_06_C_ChkSum "CRC8 Checksum";
CM_ SG_ 982 VID_Obj_06_C_MsgCnt "Message counter (rolling counter)";
CM_ SG_ 982 VID_Obj_06_C_BlockCnt "Control signal to synchronize segmented blocks of object data";
CM_ SG_ 982 VID_Obj_06_InvTTC "Inverted value of the time-to-collision with the vertical plane of the camera ";
CM_ SG_ 982 VID_Obj_06_StdD_InvTTC "Standard deviation for VID_Obj_06_InvTTC";
CM_ SG_ 982 VID_Obj_06_Ang_Overlap_EgoLane_R "Object Line Assignment (angle based indicator for the overlap of a an object with the ego lane from the right corner)";
CM_ SG_ 982 VID_Obj_06_Ang_Overlap_EgoLane_L "Object Line Assignment (angle based indicator for the overlap of a an object with the ego lane from the left corner)";
CM_ SG_ 982 VID_Obj_06_Obj_Age "Cycle counter for the existence of the object (object sampled)";
CM_ SG_ 982 VID_Obj_06_BrakeLight "Brake light recognized on the object";
CM_ SG_ 983 VID_Obj_06_D_ChkSum "CRC8 Checksum";
CM_ SG_ 983 VID_Obj_06_D_MsgCnt "Message counter (rolling counter)";
CM_ SG_ 983 VID_Obj_06_D_BlockCnt "Control signal to synchronize segmented blocks of object data";
CM_ SG_ 983 VID_Obj_06_Ang_Edge_L "Angle of the left edge of the object
Conversion factor 2^-11";
CM_ SG_ 983 VID_Obj_06_Ang_Edge_R "Angle of the right edge of the object
Conversion factor 2^-11";
CM_ SG_ 983 VID_Obj_06_StdD_Ang_Edge_L "Standard deviation for the Angle of the left edge of the object";
CM_ SG_ 983 VID_Obj_06_Obj_ID "ID of the object";
CM_ SG_ 973 VID_Obj_06_E_ChkSum "CRC8 Checksum";
CM_ SG_ 973 VID_Obj_06_E_MsgCnt "Message counter (rolling counter)";
CM_ SG_ 973 VID_Obj_06_E_BlockCnt "Control signal to synchronize segmented blocks of object data";
CM_ SG_ 973 VID_Obj_06_Velocity_longitudinal "Longitudinal velocity of the detected object (Vehicle coordinate system)";
CM_ SG_ 973 VID_Obj_06_StdD_Velocity_longitu "Standard deviation of the Longitudinal velocity of the detected object (Vehicle coordinate system)";
CM_ SG_ 973 VID_Obj_06_StdD_Ang_Edge_R "Standard deviation for the Angle of the right edge of the object";
CM_ SG_ 973 VID_Obj_06_ScaleChange "In order to fuse a video object with a radar object at higher distance (>60m), a higher resolution for the  relative velocity is needed in that range. This signal indicates the required change of the scale.";
CM_ SG_ 984 VID_Obj_07_A_ChkSum "CRC8 Checksum";
CM_ SG_ 984 VID_Obj_07_A_MsgCnt "Message counter (rolling counter)";
CM_ SG_ 984 VID_Obj_07_A_BlockCnt "Control signal to synchronize segmented blocks of object data";
CM_ SG_ 984 VID_Obj_07_Dist_longitude "Longitudinal distance relative to vehicle coordinate system";
CM_ SG_ 984 VID_Obj_07_StdD_Dist_longitude "Standard deviation for VID_Obj_07_Dist_longitude";
CM_ SG_ 984 VID_Obj_07_Ang_Center "Center of the recorded side of the 3D-object box (positive angle left of x-axis).
(Mono-Video: Rear view for vehicles). In combination with Obj_Angle_low the center
base point of the objectis described.
Coordinate system: transformed";
CM_ SG_ 984 VID_Obj_07_Stat_Measure "Object measured tracked

0 Object not measured but predicted based on 3D-model
1 Object was measured in current sample cycle
2 Object not measured but re-matched based on feature tracking";
CM_ SG_ 984 VID_Obj_07_StdD_Ang_Center "Standard deviation for VID_Obj_07_Ang_Center";
CM_ SG_ 984 VID_Obj_07_Class "Object class";
CM_ SG_ 984 VID_Obj_07_RefPoint "Index of the reference point for the 3D-object box
Info: The wording front/rear right/left relates to the indicated object orientation.
If this data is not available then a orienntation can be chosen.";
CM_ SG_ 985 VID_Obj_07_B_ChkSum "CRC8 Checksum";
CM_ SG_ 985 VID_Obj_07_B_MsgCnt "Message counter (rolling counter)";
CM_ SG_ 985 VID_Obj_07_B_BlockCnt "Control signal to synchronize segmented blocks of object data";
CM_ SG_ 985 VID_Obj_07_Ang_Width "Width of the recorded side of the 3D-object box (positive angle left of x-axis)
Monovideo: Rear view for vehicles
Coordinate system: Transformed coordinate system with camera being origin
! Ego-movement has to be compensated !";
CM_ SG_ 985 VID_Obj_07_ProbExist "Probability for the existence of an object for the given time and position (in 3sigma-area)";
CM_ SG_ 985 VID_Obj_07_StdD_dAng_longitude "Standard deviation for VID_Obj_07_dAng_longitude";
CM_ SG_ 985 VID_Obj_07_dAng_longitude "Lateral velocity of the object (related to the reference point), calculated as change of angle in the frame";
CM_ SG_ 985 VID_Obj_07_StdD_Ang_Width "Standard deviation for VID_Obj_07_Ang_Width";
CM_ SG_ 986 VID_Obj_07_C_ChkSum "CRC8 Checksum";
CM_ SG_ 986 VID_Obj_07_C_MsgCnt "Message counter (rolling counter)";
CM_ SG_ 986 VID_Obj_07_C_BlockCnt "Control signal to synchronize segmented blocks of object data";
CM_ SG_ 986 VID_Obj_07_InvTTC "Inverted value of the time-to-collision with the vertical plane of the camera ";
CM_ SG_ 986 VID_Obj_07_StdD_InvTTC "Standard deviation for VID_Obj_07_InvTTC";
CM_ SG_ 986 VID_Obj_07_Ang_Overlap_EgoLane_R "Object Line Assignment (angle based indicator for the overlap of a an object with the ego lane from the right corner)";
CM_ SG_ 986 VID_Obj_07_Ang_Overlap_EgoLane_L "Object Line Assignment (angle based indicator for the overlap of a an object with the ego lane from the left corner)";
CM_ SG_ 986 VID_Obj_07_Obj_Age "Cycle counter for the existence of the object (object sampled)";
CM_ SG_ 986 VID_Obj_07_BrakeLight "Brake light recognized on the object";
CM_ SG_ 987 VID_Obj_07_D_ChkSum "CRC8 Checksum";
CM_ SG_ 987 VID_Obj_07_D_MsgCnt "Message counter (rolling counter)";
CM_ SG_ 987 VID_Obj_07_D_BlockCnt "Control signal to synchronize segmented blocks of object data";
CM_ SG_ 987 VID_Obj_07_Ang_Edge_L "Angle of the left edge of the object
Conversion factor 2^-11";
CM_ SG_ 987 VID_Obj_07_Ang_Edge_R "Angle of the right edge of the object
Conversion factor 2^-11";
CM_ SG_ 987 VID_Obj_07_StdD_Ang_Edge_L "Standard deviation for the Angle of the left edge of the object";
CM_ SG_ 987 VID_Obj_07_Obj_ID "ID of the object";
CM_ SG_ 974 VID_Obj_07_E_ChkSum "CRC8 Checksum";
CM_ SG_ 974 VID_Obj_07_E_MsgCnt "Message counter (rolling counter)";
CM_ SG_ 974 VID_Obj_07_E_BlockCnt "Control signal to synchronize segmented blocks of object data";
CM_ SG_ 974 VID_Obj_07_Velocity_longitudinal "Longitudinal velocity of the detected object (Vehicle coordinate system)";
CM_ SG_ 974 VID_Obj_07_StdD_Velocity_longitu "Standard deviation of the Longitudinal velocity of the detected object (Vehicle coordinate system)";
CM_ SG_ 974 VID_Obj_07_StdD_Ang_Edge_R "Standard deviation for the Angle of the right edge of the object";
CM_ SG_ 974 VID_Obj_07_ScaleChange "In order to fuse a video object with a radar object at higher distance (>60m), a higher resolution for the  relative velocity is needed in that range. This signal indicates the required change of the scale.";
CM_ SG_ 988 VID_Obj_08_A_ChkSum "CRC8 Checksum";
CM_ SG_ 988 VID_Obj_08_A_MsgCnt "Message counter (rolling counter)";
CM_ SG_ 988 VID_Obj_08_A_BlockCnt "Control signal to synchronize segmented blocks of object data";
CM_ SG_ 988 VID_Obj_08_Dist_longitude "Longitudinal distance relative to vehicle coordinate system";
CM_ SG_ 988 VID_Obj_08_StdD_Dist_longitude "Standard deviation for VID_Obj_08_Dist_longitude";
CM_ SG_ 988 VID_Obj_08_Ang_Center "Center of the recorded side of the 3D-object box (positive angle left of x-axis).
(Mono-Video: Rear view for vehicles). In combination with Obj_Angle_low the center
base point of the objectis described.
Coordinate system: transformed";
CM_ SG_ 988 VID_Obj_08_Stat_Measure "Object measured tracked

0 Object not measured but predicted based on 3D-model
1 Object was measured in current sample cycle
2 Object not measured but re-matched based on feature tracking";
CM_ SG_ 988 VID_Obj_08_StdD_Ang_Center "Standard deviation for VID_Obj_08_Ang_Center";
CM_ SG_ 988 VID_Obj_08_Class "Object class";
CM_ SG_ 988 VID_Obj_08_RefPoint "Index of the reference point for the 3D-object box
Info: The wording front/rear right/left relates to the indicated object orientation.
If this data is not available then a orienntation can be chosen.";
CM_ SG_ 989 VID_Obj_08_B_ChkSum "CRC8 Checksum";
CM_ SG_ 989 VID_Obj_08_B_MsgCnt "Message counter (rolling counter)";
CM_ SG_ 989 VID_Obj_08_B_BlockCnt "Control signal to synchronize segmented blocks of object data";
CM_ SG_ 989 VID_Obj_08_Ang_Width "Width of the recorded side of the 3D-object box (positive angle left of x-axis)
Monovideo: Rear view for vehicles
Coordinate system: Transformed coordinate system with camera being origin
! Ego-movement has to be compensated !";
CM_ SG_ 989 VID_Obj_08_ProbExist "Probability for the existence of an object for the given time and position (in 3sigma-area)";
CM_ SG_ 989 VID_Obj_08_StdD_dAng_longitude "Standard deviation for VID_Obj_08_dAng_longitude";
CM_ SG_ 989 VID_Obj_08_dAng_longitude "Lateral velocity of the object (related to the reference point), calculated as change of angle in the frame";
CM_ SG_ 989 VID_Obj_08_StdD_Ang_Width "Standard deviation for VID_Obj_08_Ang_Width";
CM_ SG_ 990 VID_Obj_08_C_ChkSum "CRC8 Checksum";
CM_ SG_ 990 VID_Obj_08_C_MsgCnt "Message counter (rolling counter)";
CM_ SG_ 990 VID_Obj_08_C_BlockCnt "Control signal to synchronize segmented blocks of object data";
CM_ SG_ 990 VID_Obj_08_InvTTC "Inverted value of the time-to-collision with the vertical plane of the camera ";
CM_ SG_ 990 VID_Obj_08_StdD_InvTTC "Standard deviation for VID_Obj_08_InvTTC";
CM_ SG_ 990 VID_Obj_08_Ang_Overlap_EgoLane_R "Object Line Assignment (angle based indicator for the overlap of a an object with the ego lane from the right corner)";
CM_ SG_ 990 VID_Obj_08_Ang_Overlap_EgoLane_L "Object Line Assignment (angle based indicator for the overlap of a an object with the ego lane from the left corner)";
CM_ SG_ 990 VID_Obj_08_Obj_Age "Cycle counter for the existence of the object (object sampled)";
CM_ SG_ 990 VID_Obj_08_BrakeLight "Brake light recognized on the object";
CM_ SG_ 991 VID_Obj_08_D_ChkSum "CRC8 Checksum";
CM_ SG_ 991 VID_Obj_08_D_MsgCnt "Message counter (rolling counter)";
CM_ SG_ 991 VID_Obj_08_D_BlockCnt "Control signal to synchronize segmented blocks of object data";
CM_ SG_ 991 VID_Obj_08_Ang_Edge_L "Angle of the left edge of the object
Conversion factor 2^-11";
CM_ SG_ 991 VID_Obj_08_Ang_Edge_R "Angle of the right edge of the object
Conversion factor 2^-11";
CM_ SG_ 991 VID_Obj_08_StdD_Ang_Edge_L "Standard deviation for the Angle of the left edge of the object";
CM_ SG_ 991 VID_Obj_08_Obj_ID "ID of the object";
CM_ SG_ 975 VID_Obj_08_E_ChkSum "CRC8 Checksum";
CM_ SG_ 975 VID_Obj_08_E_MsgCnt "Message counter (rolling counter)";
CM_ SG_ 975 VID_Obj_08_E_BlockCnt "Control signal to synchronize segmented blocks of object data";
CM_ SG_ 975 VID_Obj_08_Velocity_longitudinal "Longitudinal velocity of the detected object (Vehicle coordinate system)";
CM_ SG_ 975 VID_Obj_08_StdD_Velocity_longitu "Standard deviation of the Longitudinal velocity of the detected object (Vehicle coordinate system)";
CM_ SG_ 975 VID_Obj_08_StdD_Ang_Edge_R "Standard deviation for the Angle of the right edge of the object";
CM_ SG_ 975 VID_Obj_08_ScaleChange "In order to fuse a video object with a radar object at higher distance (>60m), a higher resolution for the  relative velocity is needed in that range. This signal indicates the required change of the scale.";
CM_ SG_ 992 VID_Obj_09_A_ChkSum "CRC8 Checksum";
CM_ SG_ 992 VID_Obj_09_A_MsgCnt "Message counter (rolling counter)";
CM_ SG_ 992 VID_Obj_09_A_BlockCnt "Control signal to synchronize segmented blocks of object data";
CM_ SG_ 992 VID_Obj_09_Dist_longitude "Longitudinal distance relative to vehicle coordinate system";
CM_ SG_ 992 VID_Obj_09_StdD_Dist_longitude "Standard deviation for VID_Obj_09_Dist_longitude";
CM_ SG_ 992 VID_Obj_09_Ang_Center "Center of the recorded side of the 3D-object box (positive angle left of x-axis).
(Mono-Video: Rear view for vehicles). In combination with Obj_Angle_low the center
base point of the objectis described.
Coordinate system: transformed";
CM_ SG_ 992 VID_Obj_09_Stat_Measure "Object measured tracked

0 Object not measured but predicted based on 3D-model
1 Object was measured in current sample cycle
2 Object not measured but re-matched based on feature tracking";
CM_ SG_ 992 VID_Obj_09_StdD_Ang_Center "Standard deviation for VID_Obj_09_Ang_Center";
CM_ SG_ 992 VID_Obj_09_Class "Object class";
CM_ SG_ 992 VID_Obj_09_RefPoint "Index of the reference point for the 3D-object box
Info: The wording front/rear right/left relates to the indicated object orientation.
If this data is not available then a orienntation can be chosen.";
CM_ SG_ 993 VID_Obj_09_B_ChkSum "CRC8 Checksum";
CM_ SG_ 993 VID_Obj_09_B_MsgCnt "Message counter (rolling counter)";
CM_ SG_ 993 VID_Obj_09_B_BlockCnt "Control signal to synchronize segmented blocks of object data";
CM_ SG_ 993 VID_Obj_09_Ang_Width "Width of the recorded side of the 3D-object box (positive angle left of x-axis)
Monovideo: Rear view for vehicles
Coordinate system: Transformed coordinate system with camera being origin
! Ego-movement has to be compensated !";
CM_ SG_ 993 VID_Obj_09_ProbExist "Probability for the existence of an object for the given time and position (in 3sigma-area)";
CM_ SG_ 993 VID_Obj_09_StdD_dAng_longitude "Standard deviation for VID_Obj_09_dAng_longitude";
CM_ SG_ 993 VID_Obj_09_dAng_longitude "Lateral velocity of the object (related to the reference point), calculated as change of angle in the frame";
CM_ SG_ 993 VID_Obj_09_StdD_Ang_Width "Standard deviation for VID_Obj_09_Ang_Width";
CM_ SG_ 994 VID_Obj_09_C_ChkSum "CRC8 Checksum";
CM_ SG_ 994 VID_Obj_09_C_MsgCnt "Message counter (rolling counter)";
CM_ SG_ 994 VID_Obj_09_C_BlockCnt "Control signal to synchronize segmented blocks of object data";
CM_ SG_ 994 VID_Obj_09_InvTTC "Inverted value of the time-to-collision with the vertical plane of the camera ";
CM_ SG_ 994 VID_Obj_09_StdD_InvTTC "Standard deviation for VID_Obj_09_InvTTC";
CM_ SG_ 994 VID_Obj_09_Ang_Overlap_EgoLane_R "Object Line Assignment (angle based indicator for the overlap of a an object with the ego lane from the right corner)";
CM_ SG_ 994 VID_Obj_09_Ang_Overlap_EgoLane_L "Object Line Assignment (angle based indicator for the overlap of a an object with the ego lane from the right corner)";
CM_ SG_ 994 VID_Obj_09_Obj_Age "Cycle counter for the existence of the object (object sampled)";
CM_ SG_ 994 VID_Obj_09_BrakeLight "Brake light recognized on the object";
CM_ SG_ 995 VID_Obj_09_D_ChkSum "CRC8 Checksum";
CM_ SG_ 995 VID_Obj_09_D_MsgCnt "Message counter (rolling counter)";
CM_ SG_ 995 VID_Obj_09_D_BlockCnt "Control signal to synchronize segmented blocks of object data";
CM_ SG_ 995 VID_Obj_09_Ang_Edge_L "Angle of the left edge of the object
Conversion factor 2^-11";
CM_ SG_ 995 VID_Obj_09_Ang_Edge_R "Angle of the right edge of the object
Conversion factor 2^-11";
CM_ SG_ 995 VID_Obj_09_StdD_Ang_Edge_L "Standard deviation for the Angle of the left edge of the object";
CM_ SG_ 995 VID_Obj_09_Obj_ID "ID of the object";
CM_ SG_ 912 VID_Obj_09_E_ChkSum "CRC8 Checksum";
CM_ SG_ 912 VID_Obj_09_E_MsgCnt "Message counter (rolling counter)";
CM_ SG_ 912 VID_Obj_09_E_BlockCnt "Control signal to synchronize segmented blocks of object data";
CM_ SG_ 912 VID_Obj_09_Velocity_longitudinal "Longitudinal velocity of the detected object (Vehicle coordinate system)";
CM_ SG_ 912 VID_Obj_09_StdD_Velocity_longitu "Standard deviation of the Longitudinal velocity of the detected object (Vehicle coordinate system)";
CM_ SG_ 912 VID_Obj_09_StdD_Ang_Edge_R "Standard deviation for the Angle of the right edge of the object";
CM_ SG_ 912 VID_Obj_09_ScaleChange "In order to fuse a video object with a radar object at higher distance (>60m), a higher resolution for the  relative velocity is needed in that range. This signal indicates the required change of the scale.";
CM_ SG_ 996 VID_Obj_10_A_ChkSum "CRC8 Checksum";
CM_ SG_ 996 VID_Obj_10_A_MsgCnt "Message counter (rolling counter)";
CM_ SG_ 996 VID_Obj_10_A_BlockCnt "Control signal to synchronize segmented blocks of object data";
CM_ SG_ 996 VID_Obj_10_Dist_longitude "Longitudinal distance relative to vehicle coordinate system";
CM_ SG_ 996 VID_Obj_10_StdD_Dist_longitude "Standard deviation for VID_Obj_10_Dist_longitude";
CM_ SG_ 996 VID_Obj_10_Ang_Center "Center of the recorded side of the 3D-object box (positive angle left of x-axis).
(Mono-Video: Rear view for vehicles). In combination with Obj_Angle_low the center
base point of the objectis described.
Coordinate system: transformed";
CM_ SG_ 996 VID_Obj_10_Stat_Measure "Object measured tracked

0 Object not measured but predicted based on 3D-model
1 Object was measured in current sample cycle
2 Object not measured but re-matched based on feature tracking";
CM_ SG_ 996 VID_Obj_10_StdD_Ang_Center "Standard deviation for VID_Obj_10_Ang_Center";
CM_ SG_ 996 VID_Obj_10_Class "Object class";
CM_ SG_ 996 VID_Obj_10_RefPoint "Index of the reference point for the 3D-object box
Info: The wording front/rear right/left relates to the indicated object orientation.
If this data is not available then a orienntation can be chosen.";
CM_ SG_ 997 VID_Obj_10_B_ChkSum "CRC8 Checksum";
CM_ SG_ 997 VID_Obj_10_B_MsgCnt "Message counter (rolling counter)";
CM_ SG_ 997 VID_Obj_10_B_BlockCnt "Control signal to synchronize segmented blocks of object data";
CM_ SG_ 997 VID_Obj_10_Ang_Width "Width of the recorded side of the 3D-object box (positive angle left of x-axis)
Monovideo: Rear view for vehicles
Coordinate system: Transformed coordinate system with camera being origin
! Ego-movement has to be compensated !";
CM_ SG_ 997 VID_Obj_10_ProbExist "Probability for the existence of an object for the given time and position (in 3sigma-area)";
CM_ SG_ 997 VID_Obj_10_StdD_dAng_longitude "Standard deviation for VID_Obj_10_dAng_longitude";
CM_ SG_ 997 VID_Obj_10_dAng_longitude "Lateral velocity of the object (related to the reference point), calculated as change of angle in the frame";
CM_ SG_ 997 VID_Obj_10_StdD_Ang_Width "Standard deviation for VID_Obj_10_Ang_Width";
CM_ SG_ 998 VID_Obj_10_C_ChkSum "CRC8 Checksum";
CM_ SG_ 998 VID_Obj_10_C_MsgCnt "Message counter (rolling counter)";
CM_ SG_ 998 VID_Obj_10_C_BlockCnt "Control signal to synchronize segmented blocks of object data";
CM_ SG_ 998 VID_Obj_10_InvTTC "Inverted value of the time-to-collision with the vertical plane of the camera ";
CM_ SG_ 998 VID_Obj_10_StdD_InvTTC "Standard deviation for VID_Obj_10_InvTTC";
CM_ SG_ 998 VID_Obj_10_Ang_Overlap_EgoLane_R "Object Line Assignment (angle based indicator for the overlap of a an object with the ego lane from the right corner)";
CM_ SG_ 998 VID_Obj_10_Ang_Overlap_EgoLane_L "Object Line Assignment (angle based indicator for the overlap of a an object with the ego lane from the left corner)";
CM_ SG_ 998 VID_Obj_10_Obj_Age "Cycle counter for the existence of the object (object sampled)";
CM_ SG_ 998 VID_Obj_10_BrakeLight "Brake light recognized on the object";
CM_ SG_ 999 VID_Obj_10_D_ChkSum "CRC8 Checksum";
CM_ SG_ 999 VID_Obj_10_D_MsgCnt "Message counter (rolling counter)";
CM_ SG_ 999 VID_Obj_10_D_BlockCnt "Control signal to synchronize segmented blocks of object data";
CM_ SG_ 999 VID_Obj_10_Ang_Edge_L "Angle of the left edge of the object
Conversion factor 2^-11";
CM_ SG_ 999 VID_Obj_10_Ang_Edge_R "Angle of the right edge of the object
Conversion factor 2^-11";
CM_ SG_ 999 VID_Obj_10_StdD_Ang_Edge_L "Standard deviation for the Angle of the left edge of the object";
CM_ SG_ 999 VID_Obj_10_Obj_ID "ID of the object";
CM_ SG_ 913 VID_Obj_10_E_ChkSum "CRC8 Checksum";
CM_ SG_ 913 VID_Obj_10_E_MsgCnt "Message counter (rolling counter)";
CM_ SG_ 913 VID_Obj_10_E_BlockCnt "Control signal to synchronize segmented blocks of object data";
CM_ SG_ 913 VID_Obj_10_Velocity_longitudinal "Longitudinal velocity of the detected object (Vehicle coordinate system)";
CM_ SG_ 913 VID_Obj_10_StdD_Velocity_longitu "Standard deviation of the Longitudinal velocity of the detected object (Vehicle coordinate system)";
CM_ SG_ 913 VID_Obj_10_StdD_Ang_Edge_R "Standard deviation for the Angle of the right edge of the object";
CM_ SG_ 913 VID_Obj_10_ScaleChange "In order to fuse a video object with a radar object at higher distance (>60m), a higher resolution for the  relative velocity is needed in that range. This signal indicates the required change of the scale.";
CM_ SG_ 1000 VID_Obj_11_A_ChkSum "CRC8 Checksum";
CM_ SG_ 1000 VID_Obj_11_A_MsgCnt "Message counter (rolling counter)";
CM_ SG_ 1000 VID_Obj_11_A_BlockCnt "Control signal to synchronize segmented blocks of object data";
CM_ SG_ 1000 VID_Obj_11_Dist_longitude "Longitudinal distance relative to vehicle coordinate system";
CM_ SG_ 1000 VID_Obj_11_StdD_Dist_longitude "Standard deviation for VID_Obj_11_Dist_longitude";
CM_ SG_ 1000 VID_Obj_11_Ang_Center "Center of the recorded side of the 3D-object box (positive angle left of x-axis).
(Mono-Video: Rear view for vehicles). In combination with Obj_Angle_low the center
base point of the objectis described.
Coordinate system: transformed";
CM_ SG_ 1000 VID_Obj_11_Stat_Measure "Object measured tracked

0 Object not measured but predicted based on 3D-model
1 Object was measured in current sample cycle
2 Object not measured but re-matched based on feature tracking";
CM_ SG_ 1000 VID_Obj_11_StdD_Ang_Center "Standard deviation for VID_Obj_11_Ang_Center";
CM_ SG_ 1000 VID_Obj_11_Class "Object class";
CM_ SG_ 1000 VID_Obj_11_RefPoint "Index of the reference point for the 3D-object box
Info: The wording front/rear right/left relates to the indicated object orientation.
If this data is not available then a orienntation can be chosen.";
BA_DEF_ BO_  "PF_Msg_ID" HEX 0 4095;
BA_DEF_ BO_  "PF_Msg_Name" STRING ;
BA_DEF_ SG_  "PF_Sig_Name" STRING ;
BA_DEF_ BO_  "DiagRequest" ENUM  "No","Yes";
BA_DEF_ BO_  "DiagResponse" ENUM  "No","Yes";
BA_DEF_ BO_  "DiagState" ENUM  "No","Yes";
BA_DEF_ BO_  "GenMsgCycleTime" INT 0 65535;
BA_DEF_ BO_  "GenMsgDelayTime" INT 0 100000;
BA_DEF_ BO_  "GenMsgILSupport" ENUM  "No","Yes";
BA_DEF_ BO_  "GenMsgPDUConstants" STRING ;
BA_DEF_ BO_  "GenMsgSendType" ENUM  "Cyclic","not_used","not_used","not_used","not_used","not_used","not_used","IfActive","NoMsgSendType","EventBased";
BA_DEF_ BO_  "GenMsgStartDelayTime" INT 0 100000;
BA_DEF_ BO_  "NmMessage" ENUM  "No","Yes";
BA_DEF_ BO_  "NmhMessage" ENUM  "No","Yes";
BA_DEF_ BO_  "MsgType" ENUM  "Application","NM ","NMH","TP2.0","ISO-TP ","BAP","EID";
BA_DEF_ SG_  "GenSigActiveRepetitions" INT -2147483648 2147483647;
BA_DEF_ SG_  "GenSigSendType" ENUM  "Cyclic","OnWrite","OnWriteWithRepetition","OnChange","OnChangeWithRepetition","IfActive","IfActiveWithRepetition","NoSigSendType","OnChangeAndIfActive","OnChangeAndIfActiveWithRepetition","EventBased";
BA_DEF_ SG_  "GenSigStartValue" INT -2147483648 2147483647;
BA_DEF_ SG_  "NWMWakeupAllowed" ENUM  "No","Yes";
BA_DEF_ SG_  "GenSigFuncType" ENUM  "NoFunction","MsgCounter","CRC-8","XOR","XOR-2","DatedBit","SW-Kl15","CHK","Constant","Protocol","CRC-8-SAE_J1850";
BA_DEF_ SG_  "GenSigSwitchedByIgnition" ENUM  "No","Yes";
BA_DEF_ SG_  "Fehlerwert" HEX 0 2147483647;
BA_DEF_ SG_  "GenSigMissingSourceValue" HEX 0 2147483647;
BA_DEF_ SG_  "SystemSignalLongSymbol" STRING ;
BA_DEF_REL_ BU_SG_REL_  "GenSigTimeoutTime" INT 0 65535;
BA_DEF_DEF_  "PF_Msg_ID" 0;
BA_DEF_DEF_  "PF_Msg_Name" "";
BA_DEF_DEF_  "PF_Sig_Name" ".";
BA_DEF_DEF_  "DiagRequest" "No";
BA_DEF_DEF_  "DiagResponse" "No";
BA_DEF_DEF_  "DiagState" "No";
BA_DEF_DEF_  "GenMsgCycleTime" 0;
BA_DEF_DEF_  "GenMsgDelayTime" 0;
BA_DEF_DEF_  "GenMsgILSupport" "No";
BA_DEF_DEF_  "GenMsgPDUConstants" "";
BA_DEF_DEF_  "GenMsgSendType" "NoMsgSendType";
BA_DEF_DEF_  "GenMsgStartDelayTime" 0;
BA_DEF_DEF_  "NmMessage" "No";
BA_DEF_DEF_  "NmhMessage" "No";
BA_DEF_DEF_  "MsgType" "Application";
BA_DEF_DEF_  "GenSigActiveRepetitions" 0;
BA_DEF_DEF_  "GenSigSendType" "NoSigSendType";
BA_DEF_DEF_  "GenSigStartValue" 0;
BA_DEF_DEF_  "NWMWakeupAllowed" "No";
BA_DEF_DEF_  "GenSigFuncType" "NoFunction";
BA_DEF_DEF_  "GenSigSwitchedByIgnition" "Yes";
BA_DEF_DEF_  "Fehlerwert" 0;
BA_DEF_DEF_  "GenSigMissingSourceValue" 0;
BA_DEF_DEF_REL_ "GenSigTimeoutTime" 0;
BA_DEF_DEF_  "SystemSignalLongSymbol" "";
BA_ "PF_Msg_ID" BO_ 911 655;
BA_ "PF_Msg_Name" BO_ 911 "BV_Obj_04_D";
BA_ "GenMsgCycleTime" BO_ 911 100;
BA_ "GenMsgDelayTime" BO_ 911 30;
BA_ "GenMsgILSupport" BO_ 911 1;
BA_ "GenMsgPDUConstants" BO_ 911 "0x62,0xa0,0x0a,0x7c,0x55,0x1f,0x49,0xf6,0x15,0x43,0x33,0x2e,0x78,0xc0,0x53,0x74";
BA_ "GenMsgSendType" BO_ 911 0;
BA_ "PF_Msg_ID" BO_ 971 715;
BA_ "PF_Msg_Name" BO_ 971 "BV_Obj_04_E";
BA_ "GenMsgCycleTime" BO_ 971 100;
BA_ "GenMsgDelayTime" BO_ 971 30;
BA_ "GenMsgILSupport" BO_ 971 1;
BA_ "GenMsgPDUConstants" BO_ 971 "0x62,0xa0,0x0a,0x7c,0x55,0x1f,0x49,0xf6,0x15,0x43,0x33,0x2e,0x78,0xc0,0x53,0x74";
BA_ "GenMsgSendType" BO_ 971 0;
BA_ "PF_Msg_ID" BO_ 976 720;
BA_ "PF_Msg_Name" BO_ 976 "BV_Obj_05_A";
BA_ "GenMsgCycleTime" BO_ 976 100;
BA_ "GenMsgDelayTime" BO_ 976 30;
BA_ "GenMsgILSupport" BO_ 976 1;
BA_ "GenMsgPDUConstants" BO_ 976 "0x62,0xa0,0x0a,0x7c,0x55,0x1f,0x49,0xf6,0x15,0x43,0x33,0x2e,0x78,0xc0,0x53,0x74";
BA_ "GenMsgSendType" BO_ 976 0;
BA_ "PF_Msg_ID" BO_ 977 721;
BA_ "PF_Msg_Name" BO_ 977 "BV_Obj_05_B";
BA_ "GenMsgCycleTime" BO_ 977 100;
BA_ "GenMsgDelayTime" BO_ 977 30;
BA_ "GenMsgILSupport" BO_ 977 1;
BA_ "GenMsgPDUConstants" BO_ 977 "0x62,0xa0,0x0a,0x7c,0x55,0x1f,0x49,0xf6,0x15,0x43,0x33,0x2e,0x78,0xc0,0x53,0x74";
BA_ "GenMsgSendType" BO_ 977 0;
BA_ "PF_Msg_ID" BO_ 978 722;
BA_ "PF_Msg_Name" BO_ 978 "BV_Obj_05_C";
BA_ "GenMsgCycleTime" BO_ 978 100;
BA_ "GenMsgDelayTime" BO_ 978 30;
BA_ "GenMsgILSupport" BO_ 978 1;
BA_ "GenMsgPDUConstants" BO_ 978 "0x62,0xa0,0x0a,0x7c,0x55,0x1f,0x49,0xf6,0x15,0x43,0x33,0x2e,0x78,0xc0,0x53,0x74";
BA_ "GenMsgSendType" BO_ 978 0;
BA_ "PF_Msg_ID" BO_ 979 723;
BA_ "PF_Msg_Name" BO_ 979 "BV_Obj_05_D";
BA_ "GenMsgCycleTime" BO_ 979 100;
BA_ "GenMsgDelayTime" BO_ 979 30;
BA_ "GenMsgILSupport" BO_ 979 1;
BA_ "GenMsgPDUConstants" BO_ 979 "0x62,0xa0,0x0a,0x7c,0x55,0x1f,0x49,0xf6,0x15,0x43,0x33,0x2e,0x78,0xc0,0x53,0x74";
BA_ "GenMsgSendType" BO_ 979 0;
BA_ "PF_Msg_ID" BO_ 972 716;
BA_ "PF_Msg_Name" BO_ 972 "BV_Obj_05_E";
BA_ "GenMsgCycleTime" BO_ 972 100;
BA_ "GenMsgDelayTime" BO_ 972 30;
BA_ "GenMsgILSupport" BO_ 972 1;
BA_ "GenMsgPDUConstants" BO_ 972 "0x62,0xa0,0x0a,0x7c,0x55,0x1f,0x49,0xf6,0x15,0x43,0x33,0x2e,0x78,0xc0,0x53,0x74";
BA_ "GenMsgSendType" BO_ 972 0;
BA_ "PF_Msg_ID" BO_ 980 724;
BA_ "PF_Msg_Name" BO_ 980 "BV_Obj_06_A";
BA_ "GenMsgCycleTime" BO_ 980 100;
BA_ "GenMsgDelayTime" BO_ 980 30;
BA_ "GenMsgILSupport" BO_ 980 1;
BA_ "GenMsgPDUConstants" BO_ 980 "0x62,0xa0,0x0a,0x7c,0x55,0x1f,0x49,0xf6,0x15,0x43,0x33,0x2e,0x78,0xc0,0x53,0x74";
BA_ "GenMsgSendType" BO_ 980 0;
BA_ "PF_Msg_ID" BO_ 981 725;
BA_ "PF_Msg_Name" BO_ 981 "BV_Obj_06_B";
BA_ "GenMsgCycleTime" BO_ 981 100;
BA_ "GenMsgDelayTime" BO_ 981 30;
BA_ "GenMsgILSupport" BO_ 981 1;
BA_ "GenMsgPDUConstants" BO_ 981 "0x62,0xa0,0x0a,0x7c,0x55,0x1f,0x49,0xf6,0x15,0x43,0x33,0x2e,0x78,0xc0,0x53,0x74";
BA_ "GenMsgSendType" BO_ 981 0;
BA_ "PF_Msg_ID" BO_ 982 726;
BA_ "PF_Msg_Name" BO_ 982 "BV_Obj_06_C";
BA_ "GenMsgCycleTime" BO_ 982 100;
BA_ "GenMsgDelayTime" BO_ 982 30;
BA_ "GenMsgILSupport" BO_ 982 1;
BA_ "GenMsgPDUConstants" BO_ 982 "0x62,0xa0,0x0a,0x7c,0x55,0x1f,0x49,0xf6,0x15,0x43,0x33,0x2e,0x78,0xc0,0x53,0x74";
BA_ "GenMsgSendType" BO_ 982 0;
BA_ "PF_Msg_ID" BO_ 983 727;
BA_ "PF_Msg_Name" BO_ 983 "BV_Obj_06_D";
BA_ "GenMsgCycleTime" BO_ 983 100;
BA_ "GenMsgDelayTime" BO_ 983 30;
BA_ "GenMsgILSupport" BO_ 983 1;
BA_ "GenMsgPDUConstants" BO_ 983 "0x62,0xa0,0x0a,0x7c,0x55,0x1f,0x49,0xf6,0x15,0x43,0x33,0x2e,0x78,0xc0,0x53,0x74";
BA_ "GenMsgSendType" BO_ 983 0;
BA_ "PF_Msg_ID" BO_ 973 717;
BA_ "PF_Msg_Name" BO_ 973 "BV_Obj_06_E";
BA_ "GenMsgCycleTime" BO_ 973 100;
BA_ "GenMsgDelayTime" BO_ 973 30;
BA_ "GenMsgILSupport" BO_ 973 1;
BA_ "GenMsgPDUConstants" BO_ 973 "0x62,0xa0,0x0a,0x7c,0x55,0x1f,0x49,0xf6,0x15,0x43,0x33,0x2e,0x78,0xc0,0x53,0x74";
BA_ "GenMsgSendType" BO_ 973 0;
BA_ "PF_Msg_ID" BO_ 984 728;
BA_ "PF_Msg_Name" BO_ 984 "BV_Obj_07_A";
BA_ "GenMsgCycleTime" BO_ 984 100;
BA_ "GenMsgDelayTime" BO_ 984 30;
BA_ "GenMsgILSupport" BO_ 984 1;
BA_ "GenMsgPDUConstants" BO_ 984 "0x62,0xa0,0x0a,0x7c,0x55,0x1f,0x49,0xf6,0x15,0x43,0x33,0x2e,0x78,0xc0,0x53,0x74";
BA_ "GenMsgSendType" BO_ 984 0;
BA_ "PF_Msg_ID" BO_ 985 729;
BA_ "PF_Msg_Name" BO_ 985 "BV_Obj_07_B";
BA_ "GenMsgCycleTime" BO_ 985 100;
BA_ "GenMsgDelayTime" BO_ 985 30;
BA_ "GenMsgILSupport" BO_ 985 1;
BA_ "GenMsgPDUConstants" BO_ 985 "0x62,0xa0,0x0a,0x7c,0x55,0x1f,0x49,0xf6,0x15,0x43,0x33,0x2e,0x78,0xc0,0x53,0x74";
BA_ "GenMsgSendType" BO_ 985 0;
BA_ "PF_Msg_ID" BO_ 986 730;
BA_ "PF_Msg_Name" BO_ 986 "BV_Obj_07_C";
BA_ "GenMsgCycleTime" BO_ 986 100;
BA_ "GenMsgDelayTime" BO_ 986 30;
BA_ "GenMsgILSupport" BO_ 986 1;
BA_ "GenMsgPDUConstants" BO_ 986 "0x62,0xa0,0x0a,0x7c,0x55,0x1f,0x49,0xf6,0x15,0x43,0x33,0x2e,0x78,0xc0,0x53,0x74";
BA_ "GenMsgSendType" BO_ 986 0;
BA_ "PF_Msg_ID" BO_ 987 731;
BA_ "PF_Msg_Name" BO_ 987 "BV_Obj_07_D";
BA_ "GenMsgCycleTime" BO_ 987 100;
BA_ "GenMsgDelayTime" BO_ 987 30;
BA_ "GenMsgILSupport" BO_ 987 1;
BA_ "GenMsgPDUConstants" BO_ 987 "0x62,0xa0,0x0a,0x7c,0x55,0x1f,0x49,0xf6,0x15,0x43,0x33,0x2e,0x78,0xc0,0x53,0x74";
BA_ "GenMsgSendType" BO_ 987 0;
BA_ "PF_Msg_ID" BO_ 974 718;
BA_ "PF_Msg_Name" BO_ 974 "BV_Obj_07_E";
BA_ "GenMsgCycleTime" BO_ 974 100;
BA_ "GenMsgDelayTime" BO_ 974 30;
BA_ "GenMsgILSupport" BO_ 974 1;
BA_ "GenMsgPDUConstants" BO_ 974 "0x62,0xa0,0x0a,0x7c,0x55,0x1f,0x49,0xf6,0x15,0x43,0x33,0x2e,0x78,0xc0,0x53,0x74";
BA_ "GenMsgSendType" BO_ 974 0;
BA_ "PF_Msg_ID" BO_ 988 732;
BA_ "PF_Msg_Name" BO_ 988 "BV_Obj_08_A";
BA_ "GenMsgCycleTime" BO_ 988 100;
BA_ "GenMsgDelayTime" BO_ 988 30;
BA_ "GenMsgILSupport" BO_ 988 1;
BA_ "GenMsgPDUConstants" BO_ 988 "0x62,0xa0,0x0a,0x7c,0x55,0x1f,0x49,0xf6,0x15,0x43,0x33,0x2e,0x78,0xc0,0x53,0x74";
BA_ "GenMsgSendType" BO_ 988 0;
BA_ "PF_Msg_ID" BO_ 989 733;
BA_ "PF_Msg_Name" BO_ 989 "BV_Obj_08_B";
BA_ "GenMsgCycleTime" BO_ 989 100;
BA_ "GenMsgDelayTime" BO_ 989 30;
BA_ "GenMsgILSupport" BO_ 989 1;
BA_ "GenMsgPDUConstants" BO_ 989 "0x62,0xa0,0x0a,0x7c,0x55,0x1f,0x49,0xf6,0x15,0x43,0x33,0x2e,0x78,0xc0,0x53,0x74";
BA_ "GenMsgSendType" BO_ 989 0;
BA_ "PF_Msg_ID" BO_ 990 734;
BA_ "PF_Msg_Name" BO_ 990 "BV_Obj_08_C";
BA_ "GenMsgCycleTime" BO_ 990 100;
BA_ "GenMsgDelayTime" BO_ 990 30;
BA_ "GenMsgILSupport" BO_ 990 1;
BA_ "GenMsgPDUConstants" BO_ 990 "0x62,0xa0,0x0a,0x7c,0x55,0x1f,0x49,0xf6,0x15,0x43,0x33,0x2e,0x78,0xc0,0x53,0x74";
BA_ "GenMsgSendType" BO_ 990 0;
BA_ "PF_Msg_ID" BO_ 991 735;
BA_ "PF_Msg_Name" BO_ 991 "BV_Obj_08_D";
BA_ "GenMsgCycleTime" BO_ 991 100;
BA_ "GenMsgDelayTime" BO_ 991 30;
BA_ "GenMsgILSupport" BO_ 991 1;
BA_ "GenMsgPDUConstants" BO_ 991 "0x62,0xa0,0x0a,0x7c,0x55,0x1f,0x49,0xf6,0x15,0x43,0x33,0x2e,0x78,0xc0,0x53,0x74";
BA_ "GenMsgSendType" BO_ 991 0;
BA_ "PF_Msg_ID" BO_ 975 719;
BA_ "PF_Msg_Name" BO_ 975 "BV_Obj_08_E";
BA_ "GenMsgCycleTime" BO_ 975 100;
BA_ "GenMsgDelayTime" BO_ 975 30;
BA_ "GenMsgILSupport" BO_ 975 1;
BA_ "GenMsgPDUConstants" BO_ 975 "0x62,0xa0,0x0a,0x7c,0x55,0x1f,0x49,0xf6,0x15,0x43,0x33,0x2e,0x78,0xc0,0x53,0x74";
BA_ "GenMsgSendType" BO_ 975 0;
BA_ "PF_Msg_ID" BO_ 992 736;
BA_ "PF_Msg_Name" BO_ 992 "BV_Obj_09_A";
BA_ "GenMsgCycleTime" BO_ 992 100;
BA_ "GenMsgDelayTime" BO_ 992 30;
BA_ "GenMsgILSupport" BO_ 992 1;
BA_ "GenMsgPDUConstants" BO_ 992 "0x62,0xa0,0x0a,0x7c,0x55,0x1f,0x49,0xf6,0x15,0x43,0x33,0x2e,0x78,0xc0,0x53,0x74";
BA_ "GenMsgSendType" BO_ 992 0;
BA_ "PF_Msg_ID" BO_ 993 737;
BA_ "PF_Msg_Name" BO_ 993 "BV_Obj_09_B";
BA_ "GenMsgCycleTime" BO_ 993 100;
BA_ "GenMsgDelayTime" BO_ 993 30;
BA_ "GenMsgILSupport" BO_ 993 1;
BA_ "GenMsgPDUConstants" BO_ 993 "0x62,0xa0,0x0a,0x7c,0x55,0x1f,0x49,0xf6,0x15,0x43,0x33,0x2e,0x78,0xc0,0x53,0x74";
BA_ "GenMsgSendType" BO_ 993 0;
BA_ "PF_Msg_ID" BO_ 994 738;
BA_ "PF_Msg_Name" BO_ 994 "BV_Obj_09_C";
BA_ "GenMsgCycleTime" BO_ 994 100;
BA_ "GenMsgDelayTime" BO_ 994 30;
BA_ "GenMsgILSupport" BO_ 994 1;
BA_ "GenMsgPDUConstants" BO_ 994 "0x62,0xa0,0x0a,0x7c,0x55,0x1f,0x49,0xf6,0x15,0x43,0x33,0x2e,0x78,0xc0,0x53,0x74";
BA_ "GenMsgSendType" BO_ 994 0;
BA_ "PF_Msg_ID" BO_ 995 739;
BA_ "PF_Msg_Name" BO_ 995 "BV_Obj_09_D";
BA_ "GenMsgCycleTime" BO_ 995 100;
BA_ "GenMsgDelayTime" BO_ 995 30;
BA_ "GenMsgILSupport" BO_ 995 1;
BA_ "GenMsgPDUConstants" BO_ 995 "0x62,0xa0,0x0a,0x7c,0x55,0x1f,0x49,0xf6,0x15,0x43,0x33,0x2e,0x78,0xc0,0x53,0x74";
BA_ "GenMsgSendType" BO_ 995 0;
BA_ "PF_Msg_ID" BO_ 912 656;
BA_ "PF_Msg_Name" BO_ 912 "BV_Obj_09_E";
BA_ "GenMsgCycleTime" BO_ 912 100;
BA_ "GenMsgDelayTime" BO_ 912 30;
BA_ "GenMsgILSupport" BO_ 912 1;
BA_ "GenMsgPDUConstants" BO_ 912 "0x62,0xa0,0x0a,0x7c,0x55,0x1f,0x49,0xf6,0x15,0x43,0x33,0x2e,0x78,0xc0,0x53,0x74";
BA_ "GenMsgSendType" BO_ 912 0;
BA_ "PF_Msg_ID" BO_ 996 740;
BA_ "PF_Msg_Name" BO_ 996 "BV_Obj_10_A";
BA_ "GenMsgCycleTime" BO_ 996 100;
BA_ "GenMsgDelayTime" BO_ 996 30;
BA_ "GenMsgILSupport" BO_ 996 1;
BA_ "GenMsgPDUConstants" BO_ 996 "0x62,0xa0,0x0a,0x7c,0x55,0x1f,0x49,0xf6,0x15,0x43,0x33,0x2e,0x78,0xc0,0x53,0x74";
BA_ "GenMsgSendType" BO_ 996 0;
BA_ "PF_Msg_ID" BO_ 997 741;
BA_ "PF_Msg_Name" BO_ 997 "BV_Obj_10_B";
BA_ "GenMsgCycleTime" BO_ 997 100;
BA_ "GenMsgDelayTime" BO_ 997 30;
BA_ "GenMsgILSupport" BO_ 997 1;
BA_ "GenMsgPDUConstants" BO_ 997 "0x62,0xa0,0x0a,0x7c,0x55,0x1f,0x49,0xf6,0x15,0x43,0x33,0x2e,0x78,0xc0,0x53,0x74";
BA_ "GenMsgSendType" BO_ 997 0;
BA_ "PF_Msg_ID" BO_ 998 742;
BA_ "PF_Msg_Name" BO_ 998 "BV_Obj_10_C";
BA_ "GenMsgCycleTime" BO_ 998 100;
BA_ "GenMsgDelayTime" BO_ 998 30;
BA_ "GenMsgILSupport" BO_ 998 1;
BA_ "GenMsgPDUConstants" BO_ 998 "0x62,0xa0,0x0a,0x7c,0x55,0x1f,0x49,0xf6,0x15,0x43,0x33,0x2e,0x78,0xc0,0x53,0x74";
BA_ "GenMsgSendType" BO_ 998 0;
BA_ "PF_Msg_ID" BO_ 999 743;
BA_ "PF_Msg_Name" BO_ 999 "BV_Obj_10_D";
BA_ "GenMsgCycleTime" BO_ 999 100;
BA_ "GenMsgDelayTime" BO_ 999 30;
BA_ "GenMsgILSupport" BO_ 999 1;
BA_ "GenMsgPDUConstants" BO_ 999 "0x62,0xa0,0x0a,0x7c,0x55,0x1f,0x49,0xf6,0x15,0x43,0x33,0x2e,0x78,0xc0,0x53,0x74";
BA_ "GenMsgSendType" BO_ 999 0;
BA_ "PF_Msg_ID" BO_ 913 657;
BA_ "PF_Msg_Name" BO_ 913 "BV_Obj_10_E";
BA_ "GenMsgCycleTime" BO_ 913 100;
BA_ "GenMsgDelayTime" BO_ 913 30;
BA_ "GenMsgILSupport" BO_ 913 1;
BA_ "GenMsgPDUConstants" BO_ 913 "0x62,0xa0,0x0a,0x7c,0x55,0x1f,0x49,0xf6,0x15,0x43,0x33,0x2e,0x78,0xc0,0x53,0x74";
BA_ "GenMsgSendType" BO_ 913 0;
BA_ "PF_Msg_ID" BO_ 1000 744;
BA_ "PF_Msg_Name" BO_ 1000 "BV_Obj_11_A";
BA_ "GenMsgCycleTime" BO_ 1000 100;
BA_ "GenMsgDelayTime" BO_ 1000 30;
BA_ "GenMsgILSupport" BO_ 1000 1;
BA_ "GenMsgPDUConstants" BO_ 1000 "0x62,0xa0,0x0a,0x7c,0x55,0x1f,0x49,0xf6,0x15,0x43,0x33,0x2e,0x78,0xc0,0x53,0x74";
BA_ "GenMsgSendType" BO_ 1000 0;
BA_ "PF_Sig_Name" SG_ 911 VID_Obj_04_D_ChkSum "BV_Obj_04_D_CRC";
BA_ "GenSigSendType" SG_ 911 VID_Obj_04_D_ChkSum 0;
BA_ "GenSigFuncType" SG_ 911 VID_Obj_04_D_ChkSum 2;
BA_ "PF_Sig_Name" SG_ 911 VID_Obj_04_D_MsgCnt "BV_Obj_04_D_BZ";
BA_ "GenSigSendType" SG_ 911 VID_Obj_04_D_MsgCnt 0;
BA_ "GenSigFuncType" SG_ 911 VID_Obj_04_D_MsgCnt 1;
BA_ "PF_Sig_Name" SG_ 911 VID_Obj_04_D_BlockCnt "BV1_Obj_04_D_BlockZaehler";
BA_ "GenSigSendType" SG_ 911 VID_Obj_04_D_BlockCnt 3;
BA_ "PF_Sig_Name" SG_ 911 VID_Obj_04_Ang_Edge_L "BV_Objekt_04_phi_left";
BA_ "GenSigSendType" SG_ 911 VID_Obj_04_Ang_Edge_L 0;
BA_ "GenSigStartValue" SG_ 911 VID_Obj_04_Ang_Edge_L 1024;
BA_ "PF_Sig_Name" SG_ 911 VID_Obj_04_Ang_Edge_R "BV_Objekt_04_phi_right";
BA_ "GenSigSendType" SG_ 911 VID_Obj_04_Ang_Edge_R 0;
BA_ "GenSigStartValue" SG_ 911 VID_Obj_04_Ang_Edge_R 1024;
BA_ "PF_Sig_Name" SG_ 911 VID_Obj_04_StdD_Ang_Edge_L "BV_Objekt_04_sdv_phi_left";
BA_ "GenSigSendType" SG_ 911 VID_Obj_04_StdD_Ang_Edge_L 0;
BA_ "GenSigStartValue" SG_ 911 VID_Obj_04_StdD_Ang_Edge_L 512;
BA_ "PF_Sig_Name" SG_ 911 VID_Obj_04_Obj_ID "BV1_Obj_04_ID";
BA_ "GenSigSendType" SG_ 911 VID_Obj_04_Obj_ID 0;
BA_ "GenSigStartValue" SG_ 911 VID_Obj_04_Obj_ID 255;
BA_ "PF_Sig_Name" SG_ 971 VID_Obj_04_E_ChkSum "BV_Obj_04_E_CRC";
BA_ "GenSigSendType" SG_ 971 VID_Obj_04_E_ChkSum 0;
BA_ "GenSigFuncType" SG_ 971 VID_Obj_04_E_ChkSum 2;
BA_ "PF_Sig_Name" SG_ 971 VID_Obj_04_E_MsgCnt "BV_Obj_04_E_BZ";
BA_ "GenSigSendType" SG_ 971 VID_Obj_04_E_MsgCnt 0;
BA_ "GenSigFuncType" SG_ 971 VID_Obj_04_E_MsgCnt 1;
BA_ "PF_Sig_Name" SG_ 971 VID_Obj_04_E_BlockCnt "BV1_Obj_04_E_BlockZaehler";
BA_ "GenSigSendType" SG_ 971 VID_Obj_04_E_BlockCnt 3;
BA_ "PF_Sig_Name" SG_ 971 VID_Obj_04_Velocity_longitudinal "BV1_Obj_04_RadialGeschw";
BA_ "GenSigSendType" SG_ 971 VID_Obj_04_Velocity_longitudinal 0;
BA_ "GenSigStartValue" SG_ 971 VID_Obj_04_Velocity_longitudinal 2046;
BA_ "PF_Sig_Name" SG_ 971 VID_Obj_04_StdD_Velocity_longitu "BV1_Obj_04_RadialGeschw_StdA";
BA_ "GenSigSendType" SG_ 971 VID_Obj_04_StdD_Velocity_longitu 0;
BA_ "GenSigStartValue" SG_ 971 VID_Obj_04_StdD_Velocity_longitu 1022;
BA_ "SystemSignalLongSymbol" SG_ 971 VID_Obj_04_StdD_Velocity_longitu "VID_Obj_04_StdD_Velocity_longitudinal";
BA_ "PF_Sig_Name" SG_ 971 VID_Obj_04_StdD_Ang_Edge_R "BV_Objekt_04_sdv_phi_right";
BA_ "GenSigSendType" SG_ 971 VID_Obj_04_StdD_Ang_Edge_R 0;
BA_ "GenSigStartValue" SG_ 971 VID_Obj_04_StdD_Ang_Edge_R 512;
BA_ "PF_Sig_Name" SG_ 971 VID_Obj_04_ScaleChange "BV_Obj_04_ScaleChange";
BA_ "GenSigSendType" SG_ 971 VID_Obj_04_ScaleChange 0;
BA_ "PF_Sig_Name" SG_ 976 VID_Obj_05_A_ChkSum "BV_Obj_05_A_CRC";
BA_ "GenSigSendType" SG_ 976 VID_Obj_05_A_ChkSum 0;
BA_ "GenSigFuncType" SG_ 976 VID_Obj_05_A_ChkSum 2;
BA_ "PF_Sig_Name" SG_ 976 VID_Obj_05_A_MsgCnt "BV_Obj_05_A_BZ";
BA_ "GenSigSendType" SG_ 976 VID_Obj_05_A_MsgCnt 0;
BA_ "GenSigFuncType" SG_ 976 VID_Obj_05_A_MsgCnt 1;
BA_ "PF_Sig_Name" SG_ 976 VID_Obj_05_A_BlockCnt "BV1_Obj_05_A_BlockZaehler";
BA_ "GenSigSendType" SG_ 976 VID_Obj_05_A_BlockCnt 3;
BA_ "PF_Sig_Name" SG_ 976 VID_Obj_05_Dist_longitude "BV1_Obj_05_Dist_longitude";
BA_ "GenSigSendType" SG_ 976 VID_Obj_05_Dist_longitude 0;
BA_ "GenSigStartValue" SG_ 976 VID_Obj_05_Dist_longitude 4095;
BA_ "PF_Sig_Name" SG_ 976 VID_Obj_05_StdD_Dist_longitude "BV1_Obj_05_Dist_longitudeStdA";
BA_ "GenSigSendType" SG_ 976 VID_Obj_05_StdD_Dist_longitude 0;
BA_ "GenSigStartValue" SG_ 976 VID_Obj_05_StdD_Dist_longitude 127;
BA_ "PF_Sig_Name" SG_ 976 VID_Obj_05_Ang_Center "BV1_Obj_05_WnklMitte";
BA_ "GenSigSendType" SG_ 976 VID_Obj_05_Ang_Center 0;
BA_ "GenSigStartValue" SG_ 976 VID_Obj_05_Ang_Center 2047;
BA_ "PF_Sig_Name" SG_ 976 VID_Obj_05_Stat_Measure "BV1_Obj_05_Gemessen";
BA_ "GenSigSendType" SG_ 976 VID_Obj_05_Stat_Measure 0;
BA_ "PF_Sig_Name" SG_ 976 VID_Obj_05_StdD_Ang_Center "BV1_Obj_05_WnklMitteStdA";
BA_ "GenSigSendType" SG_ 976 VID_Obj_05_StdD_Ang_Center 0;
BA_ "GenSigStartValue" SG_ 976 VID_Obj_05_StdD_Ang_Center 255;
BA_ "PF_Sig_Name" SG_ 976 VID_Obj_05_Class "BV1_Obj_05_Klasse";
BA_ "GenSigSendType" SG_ 976 VID_Obj_05_Class 0;
BA_ "GenSigStartValue" SG_ 976 VID_Obj_05_Class 15;
BA_ "PF_Sig_Name" SG_ 976 VID_Obj_05_RefPoint "BV1_Obj_05_Bezugspunkt";
BA_ "GenSigSendType" SG_ 976 VID_Obj_05_RefPoint 0;
BA_ "GenSigStartValue" SG_ 976 VID_Obj_05_RefPoint 15;
BA_ "PF_Sig_Name" SG_ 977 VID_Obj_05_B_ChkSum "BV_Obj_05_B_CRC";
BA_ "GenSigSendType" SG_ 977 VID_Obj_05_B_ChkSum 0;
BA_ "GenSigFuncType" SG_ 977 VID_Obj_05_B_ChkSum 2;
BA_ "PF_Sig_Name" SG_ 977 VID_Obj_05_B_MsgCnt "BV_Obj_05_B_BZ";
BA_ "GenSigSendType" SG_ 977 VID_Obj_05_B_MsgCnt 0;
BA_ "GenSigFuncType" SG_ 977 VID_Obj_05_B_MsgCnt 1;
BA_ "PF_Sig_Name" SG_ 977 VID_Obj_05_B_BlockCnt "BV1_Obj_05_B_BlockZaehler";
BA_ "GenSigSendType" SG_ 977 VID_Obj_05_B_BlockCnt 3;
BA_ "PF_Sig_Name" SG_ 977 VID_Obj_05_Ang_Width "BV1_Obj_05_WnklBreite";
BA_ "GenSigSendType" SG_ 977 VID_Obj_05_Ang_Width 0;
BA_ "GenSigStartValue" SG_ 977 VID_Obj_05_Ang_Width 2047;
BA_ "PF_Sig_Name" SG_ 977 VID_Obj_05_ProbExist "BV1_Obj_05_ExistenzMass";
BA_ "GenSigSendType" SG_ 977 VID_Obj_05_ProbExist 0;
BA_ "GenSigStartValue" SG_ 977 VID_Obj_05_ProbExist 127;
BA_ "PF_Sig_Name" SG_ 977 VID_Obj_05_StdD_dAng_longitude "BV1_Obj_05_WnklGeschwStdA";
BA_ "GenSigSendType" SG_ 977 VID_Obj_05_StdD_dAng_longitude 0;
BA_ "GenSigStartValue" SG_ 977 VID_Obj_05_StdD_dAng_longitude 63;
BA_ "PF_Sig_Name" SG_ 977 VID_Obj_05_dAng_longitude "BV1_Obj_05_WnklGeschw";
BA_ "GenSigSendType" SG_ 977 VID_Obj_05_dAng_longitude 0;
BA_ "GenSigStartValue" SG_ 977 VID_Obj_05_dAng_longitude 511;
BA_ "PF_Sig_Name" SG_ 977 VID_Obj_05_StdD_Ang_Width "BV1_Obj_05_WnklBreiteStdA";
BA_ "GenSigSendType" SG_ 977 VID_Obj_05_StdD_Ang_Width 0;
BA_ "GenSigStartValue" SG_ 977 VID_Obj_05_StdD_Ang_Width 255;
BA_ "PF_Sig_Name" SG_ 978 VID_Obj_05_C_ChkSum "BV_Obj_05_C_CRC";
BA_ "GenSigSendType" SG_ 978 VID_Obj_05_C_ChkSum 0;
BA_ "GenSigFuncType" SG_ 978 VID_Obj_05_C_ChkSum 2;
BA_ "PF_Sig_Name" SG_ 978 VID_Obj_05_C_MsgCnt "BV_Obj_05_C_BZ";
BA_ "GenSigSendType" SG_ 978 VID_Obj_05_C_MsgCnt 0;
BA_ "GenSigFuncType" SG_ 978 VID_Obj_05_C_MsgCnt 1;
BA_ "PF_Sig_Name" SG_ 978 VID_Obj_05_C_BlockCnt "BV1_Obj_05_C_BlockZaehler";
BA_ "GenSigSendType" SG_ 978 VID_Obj_05_C_BlockCnt 3;
BA_ "PF_Sig_Name" SG_ 978 VID_Obj_05_InvTTC "BV1_Obj_05_InvTTCBildeb";
BA_ "GenSigSendType" SG_ 978 VID_Obj_05_InvTTC 0;
BA_ "GenSigStartValue" SG_ 978 VID_Obj_05_InvTTC 1023;
BA_ "PF_Sig_Name" SG_ 978 VID_Obj_05_StdD_InvTTC "BV1_Obj_05_InvTTCBildebStdA";
BA_ "GenSigSendType" SG_ 978 VID_Obj_05_StdD_InvTTC 0;
BA_ "GenSigStartValue" SG_ 978 VID_Obj_05_StdD_InvTTC 127;
BA_ "PF_Sig_Name" SG_ 978 VID_Obj_05_Ang_Overlap_EgoLane_R "BV1_Obj_05_UeberdWnklEgoSpurR";
BA_ "GenSigSendType" SG_ 978 VID_Obj_05_Ang_Overlap_EgoLane_R 0;
BA_ "GenSigStartValue" SG_ 978 VID_Obj_05_Ang_Overlap_EgoLane_R 511;
BA_ "PF_Sig_Name" SG_ 978 VID_Obj_05_Ang_Overlap_EgoLane_L "BV1_Obj_05_UeberdWnklEgoSpurL";
BA_ "GenSigSendType" SG_ 978 VID_Obj_05_Ang_Overlap_EgoLane_L 0;
BA_ "GenSigStartValue" SG_ 978 VID_Obj_05_Ang_Overlap_EgoLane_L 511;
BA_ "PF_Sig_Name" SG_ 978 VID_Obj_05_Obj_Age "BV1_Obj_05_Alter";
BA_ "GenSigSendType" SG_ 978 VID_Obj_05_Obj_Age 0;
BA_ "GenSigStartValue" SG_ 978 VID_Obj_05_Obj_Age 4095;
BA_ "PF_Sig_Name" SG_ 978 VID_Obj_05_BrakeLight "BV1_Obj_05_BremsLicht";
BA_ "GenSigSendType" SG_ 978 VID_Obj_05_BrakeLight 0;
BA_ "PF_Sig_Name" SG_ 979 VID_Obj_05_D_ChkSum "BV_Obj_05_D_CRC";
BA_ "GenSigSendType" SG_ 979 VID_Obj_05_D_ChkSum 0;
BA_ "GenSigFuncType" SG_ 979 VID_Obj_05_D_ChkSum 2;
BA_ "PF_Sig_Name" SG_ 979 VID_Obj_05_D_MsgCnt "BV_Obj_05_D_BZ";
BA_ "GenSigSendType" SG_ 979 VID_Obj_05_D_MsgCnt 0;
BA_ "GenSigFuncType" SG_ 979 VID_Obj_05_D_MsgCnt 1;
BA_ "PF_Sig_Name" SG_ 979 VID_Obj_05_D_BlockCnt "BV1_Obj_05_D_BlockZaehler";
BA_ "GenSigSendType" SG_ 979 VID_Obj_05_D_BlockCnt 3;
BA_ "PF_Sig_Name" SG_ 979 VID_Obj_05_Ang_Edge_L "BV_Objekt_05_phi_left";
BA_ "GenSigSendType" SG_ 979 VID_Obj_05_Ang_Edge_L 0;
BA_ "GenSigStartValue" SG_ 979 VID_Obj_05_Ang_Edge_L 1024;
BA_ "PF_Sig_Name" SG_ 979 VID_Obj_05_Ang_Edge_R "BV_Objekt_05_phi_right";
BA_ "GenSigSendType" SG_ 979 VID_Obj_05_Ang_Edge_R 0;
BA_ "GenSigStartValue" SG_ 979 VID_Obj_05_Ang_Edge_R 1024;
BA_ "PF_Sig_Name" SG_ 979 VID_Obj_05_StdD_Ang_Edge_L "BV_Objekt_05_sdv_phi_left";
BA_ "GenSigSendType" SG_ 979 VID_Obj_05_StdD_Ang_Edge_L 0;
BA_ "GenSigStartValue" SG_ 979 VID_Obj_05_StdD_Ang_Edge_L 512;
BA_ "PF_Sig_Name" SG_ 979 VID_Obj_05_Obj_ID "BV1_Obj_05_ID";
BA_ "GenSigSendType" SG_ 979 VID_Obj_05_Obj_ID 0;
BA_ "GenSigStartValue" SG_ 979 VID_Obj_05_Obj_ID 255;
BA_ "PF_Sig_Name" SG_ 972 VID_Obj_05_E_ChkSum "BV_Obj_05_E_CRC";
BA_ "GenSigSendType" SG_ 972 VID_Obj_05_E_ChkSum 0;
BA_ "GenSigFuncType" SG_ 972 VID_Obj_05_E_ChkSum 2;
BA_ "PF_Sig_Name" SG_ 972 VID_Obj_05_E_MsgCnt "BV_Obj_05_E_BZ";
BA_ "GenSigSendType" SG_ 972 VID_Obj_05_E_MsgCnt 0;
BA_ "GenSigFuncType" SG_ 972 VID_Obj_05_E_MsgCnt 1;
BA_ "PF_Sig_Name" SG_ 972 VID_Obj_05_E_BlockCnt "BV1_Obj_05_E_BlockZaehler";
BA_ "GenSigSendType" SG_ 972 VID_Obj_05_E_BlockCnt 3;
BA_ "PF_Sig_Name" SG_ 972 VID_Obj_05_Velocity_longitudinal "BV1_Obj_05_RadialGeschw";
BA_ "GenSigSendType" SG_ 972 VID_Obj_05_Velocity_longitudinal 0;
BA_ "GenSigStartValue" SG_ 972 VID_Obj_05_Velocity_longitudinal 2046;
BA_ "PF_Sig_Name" SG_ 972 VID_Obj_05_StdD_Velocity_longitu "BV1_Obj_05_RadialGeschw_StdA";
BA_ "GenSigSendType" SG_ 972 VID_Obj_05_StdD_Velocity_longitu 0;
BA_ "GenSigStartValue" SG_ 972 VID_Obj_05_StdD_Velocity_longitu 1022;
BA_ "SystemSignalLongSymbol" SG_ 972 VID_Obj_05_StdD_Velocity_longitu "VID_Obj_05_StdD_Velocity_longitudinal";
BA_ "PF_Sig_Name" SG_ 972 VID_Obj_05_StdD_Ang_Edge_R "BV_Objekt_05_sdv_phi_right";
BA_ "GenSigSendType" SG_ 972 VID_Obj_05_StdD_Ang_Edge_R 0;
BA_ "GenSigStartValue" SG_ 972 VID_Obj_05_StdD_Ang_Edge_R 512;
BA_ "PF_Sig_Name" SG_ 972 VID_Obj_05_ScaleChange "BV_Obj_05_ScaleChange";
BA_ "GenSigSendType" SG_ 972 VID_Obj_05_ScaleChange 0;
BA_ "PF_Sig_Name" SG_ 980 VID_Obj_06_A_ChkSum "BV_Obj_06_A_CRC";
BA_ "GenSigSendType" SG_ 980 VID_Obj_06_A_ChkSum 0;
BA_ "GenSigFuncType" SG_ 980 VID_Obj_06_A_ChkSum 2;
BA_ "PF_Sig_Name" SG_ 980 VID_Obj_06_A_MsgCnt "BV_Obj_06_A_BZ";
BA_ "GenSigSendType" SG_ 980 VID_Obj_06_A_MsgCnt 0;
BA_ "GenSigFuncType" SG_ 980 VID_Obj_06_A_MsgCnt 1;
BA_ "PF_Sig_Name" SG_ 980 VID_Obj_06_A_BlockCnt "BV1_Obj_06_A_BlockZaehler";
BA_ "GenSigSendType" SG_ 980 VID_Obj_06_A_BlockCnt 3;
BA_ "PF_Sig_Name" SG_ 980 VID_Obj_06_Dist_longitude "BV1_Obj_06_Dist_longitude";
BA_ "GenSigSendType" SG_ 980 VID_Obj_06_Dist_longitude 0;
BA_ "GenSigStartValue" SG_ 980 VID_Obj_06_Dist_longitude 4095;
BA_ "PF_Sig_Name" SG_ 980 VID_Obj_06_StdD_Dist_longitude "BV1_Obj_06_Dist_longitudeStdA";
BA_ "GenSigSendType" SG_ 980 VID_Obj_06_StdD_Dist_longitude 0;
BA_ "GenSigStartValue" SG_ 980 VID_Obj_06_StdD_Dist_longitude 127;
BA_ "PF_Sig_Name" SG_ 980 VID_Obj_06_Ang_Center "BV1_Obj_06_WnklMitte";
BA_ "GenSigSendType" SG_ 980 VID_Obj_06_Ang_Center 0;
BA_ "GenSigStartValue" SG_ 980 VID_Obj_06_Ang_Center 2047;
BA_ "PF_Sig_Name" SG_ 980 VID_Obj_06_Stat_Measure "BV1_Obj_06_Gemessen";
BA_ "GenSigSendType" SG_ 980 VID_Obj_06_Stat_Measure 0;
BA_ "PF_Sig_Name" SG_ 980 VID_Obj_06_StdD_Ang_Center "BV1_Obj_06_WnklMitteStdA";
BA_ "GenSigSendType" SG_ 980 VID_Obj_06_StdD_Ang_Center 0;
BA_ "GenSigStartValue" SG_ 980 VID_Obj_06_StdD_Ang_Center 255;
BA_ "PF_Sig_Name" SG_ 980 VID_Obj_06_Class "BV1_Obj_06_Klasse";
BA_ "GenSigSendType" SG_ 980 VID_Obj_06_Class 0;
BA_ "GenSigStartValue" SG_ 980 VID_Obj_06_Class 15;
BA_ "PF_Sig_Name" SG_ 980 VID_Obj_06_RefPoint "BV1_Obj_06_Bezugspunkt";
BA_ "GenSigSendType" SG_ 980 VID_Obj_06_RefPoint 0;
BA_ "GenSigStartValue" SG_ 980 VID_Obj_06_RefPoint 15;
BA_ "PF_Sig_Name" SG_ 981 VID_Obj_06_B_ChkSum "BV_Obj_06_B_CRC";
BA_ "GenSigSendType" SG_ 981 VID_Obj_06_B_ChkSum 0;
BA_ "GenSigFuncType" SG_ 981 VID_Obj_06_B_ChkSum 2;
BA_ "PF_Sig_Name" SG_ 981 VID_Obj_06_B_MsgCnt "BV_Obj_06_B_BZ";
BA_ "GenSigSendType" SG_ 981 VID_Obj_06_B_MsgCnt 0;
BA_ "GenSigFuncType" SG_ 981 VID_Obj_06_B_MsgCnt 1;
BA_ "PF_Sig_Name" SG_ 981 VID_Obj_06_B_BlockCnt "BV1_Obj_06_B_BlockZaehler";
BA_ "GenSigSendType" SG_ 981 VID_Obj_06_B_BlockCnt 3;
BA_ "PF_Sig_Name" SG_ 981 VID_Obj_06_Ang_Width "BV1_Obj_06_WnklBreite";
BA_ "GenSigSendType" SG_ 981 VID_Obj_06_Ang_Width 0;
BA_ "GenSigStartValue" SG_ 981 VID_Obj_06_Ang_Width 2047;
BA_ "PF_Sig_Name" SG_ 981 VID_Obj_06_ProbExist "BV1_Obj_06_ExistenzMass";
BA_ "GenSigSendType" SG_ 981 VID_Obj_06_ProbExist 0;
BA_ "GenSigStartValue" SG_ 981 VID_Obj_06_ProbExist 127;
BA_ "PF_Sig_Name" SG_ 981 VID_Obj_06_StdD_dAng_longitude "BV1_Obj_06_WnklGeschwStdA";
BA_ "GenSigSendType" SG_ 981 VID_Obj_06_StdD_dAng_longitude 0;
BA_ "GenSigStartValue" SG_ 981 VID_Obj_06_StdD_dAng_longitude 63;
BA_ "PF_Sig_Name" SG_ 981 VID_Obj_06_dAng_longitude "BV1_Obj_06_WnklGeschw";
BA_ "GenSigSendType" SG_ 981 VID_Obj_06_dAng_longitude 0;
BA_ "GenSigStartValue" SG_ 981 VID_Obj_06_dAng_longitude 511;
BA_ "PF_Sig_Name" SG_ 981 VID_Obj_06_StdD_Ang_Width "BV1_Obj_06_WnklBreiteStdA";
BA_ "GenSigSendType" SG_ 981 VID_Obj_06_StdD_Ang_Width 0;
BA_ "GenSigStartValue" SG_ 981 VID_Obj_06_StdD_Ang_Width 255;
BA_ "PF_Sig_Name" SG_ 982 VID_Obj_06_C_ChkSum "BV_Obj_06_C_CRC";
BA_ "GenSigSendType" SG_ 982 VID_Obj_06_C_ChkSum 0;
BA_ "GenSigFuncType" SG_ 982 VID_Obj_06_C_ChkSum 2;
BA_ "PF_Sig_Name" SG_ 982 VID_Obj_06_C_MsgCnt "BV_Obj_06_C_BZ";
BA_ "GenSigSendType" SG_ 982 VID_Obj_06_C_MsgCnt 0;
BA_ "GenSigFuncType" SG_ 982 VID_Obj_06_C_MsgCnt 1;
BA_ "PF_Sig_Name" SG_ 982 VID_Obj_06_C_BlockCnt "BV1_Obj_06_C_BlockZaehler";
BA_ "GenSigSendType" SG_ 982 VID_Obj_06_C_BlockCnt 3;
BA_ "PF_Sig_Name" SG_ 982 VID_Obj_06_InvTTC "BV1_Obj_06_InvTTCBildeb";
BA_ "GenSigSendType" SG_ 982 VID_Obj_06_InvTTC 0;
BA_ "GenSigStartValue" SG_ 982 VID_Obj_06_InvTTC 1023;
BA_ "PF_Sig_Name" SG_ 982 VID_Obj_06_StdD_InvTTC "BV1_Obj_06_InvTTCBildebStdA";
BA_ "GenSigSendType" SG_ 982 VID_Obj_06_StdD_InvTTC 0;
BA_ "GenSigStartValue" SG_ 982 VID_Obj_06_StdD_InvTTC 127;
BA_ "PF_Sig_Name" SG_ 982 VID_Obj_06_Ang_Overlap_EgoLane_R "BV1_Obj_06_UeberdWnklEgoSpurR";
BA_ "GenSigSendType" SG_ 982 VID_Obj_06_Ang_Overlap_EgoLane_R 0;
BA_ "GenSigStartValue" SG_ 982 VID_Obj_06_Ang_Overlap_EgoLane_R 511;
BA_ "PF_Sig_Name" SG_ 982 VID_Obj_06_Ang_Overlap_EgoLane_L "BV1_Obj_06_UeberdWnklEgoSpurL";
BA_ "GenSigSendType" SG_ 982 VID_Obj_06_Ang_Overlap_EgoLane_L 0;
BA_ "GenSigStartValue" SG_ 982 VID_Obj_06_Ang_Overlap_EgoLane_L 511;
BA_ "PF_Sig_Name" SG_ 982 VID_Obj_06_Obj_Age "BV1_Obj_06_Alter";
BA_ "GenSigSendType" SG_ 982 VID_Obj_06_Obj_Age 0;
BA_ "GenSigStartValue" SG_ 982 VID_Obj_06_Obj_Age 4095;
BA_ "PF_Sig_Name" SG_ 982 VID_Obj_06_BrakeLight "BV1_Obj_06_BremsLicht";
BA_ "GenSigSendType" SG_ 982 VID_Obj_06_BrakeLight 0;
BA_ "PF_Sig_Name" SG_ 983 VID_Obj_06_D_ChkSum "BV_Obj_06_D_CRC";
BA_ "GenSigSendType" SG_ 983 VID_Obj_06_D_ChkSum 0;
BA_ "GenSigFuncType" SG_ 983 VID_Obj_06_D_ChkSum 2;
BA_ "PF_Sig_Name" SG_ 983 VID_Obj_06_D_MsgCnt "BV_Obj_06_D_BZ";
BA_ "GenSigSendType" SG_ 983 VID_Obj_06_D_MsgCnt 0;
BA_ "GenSigFuncType" SG_ 983 VID_Obj_06_D_MsgCnt 1;
BA_ "PF_Sig_Name" SG_ 983 VID_Obj_06_D_BlockCnt "BV1_Obj_06_D_BlockZaehler";
BA_ "GenSigSendType" SG_ 983 VID_Obj_06_D_BlockCnt 3;
BA_ "PF_Sig_Name" SG_ 983 VID_Obj_06_Ang_Edge_L "BV_Objekt_06_phi_left";
BA_ "GenSigSendType" SG_ 983 VID_Obj_06_Ang_Edge_L 0;
BA_ "GenSigStartValue" SG_ 983 VID_Obj_06_Ang_Edge_L 1024;
BA_ "PF_Sig_Name" SG_ 983 VID_Obj_06_Ang_Edge_R "BV_Objekt_06_phi_right";
BA_ "GenSigSendType" SG_ 983 VID_Obj_06_Ang_Edge_R 0;
BA_ "GenSigStartValue" SG_ 983 VID_Obj_06_Ang_Edge_R 1024;
BA_ "PF_Sig_Name" SG_ 983 VID_Obj_06_StdD_Ang_Edge_L "BV_Objekt_06_sdv_phi_left";
BA_ "GenSigSendType" SG_ 983 VID_Obj_06_StdD_Ang_Edge_L 0;
BA_ "GenSigStartValue" SG_ 983 VID_Obj_06_StdD_Ang_Edge_L 512;
BA_ "PF_Sig_Name" SG_ 983 VID_Obj_06_Obj_ID "BV1_Obj_06_ID";
BA_ "GenSigSendType" SG_ 983 VID_Obj_06_Obj_ID 0;
BA_ "GenSigStartValue" SG_ 983 VID_Obj_06_Obj_ID 255;
BA_ "PF_Sig_Name" SG_ 973 VID_Obj_06_E_ChkSum "BV_Obj_06_E_CRC";
BA_ "GenSigSendType" SG_ 973 VID_Obj_06_E_ChkSum 0;
BA_ "GenSigFuncType" SG_ 973 VID_Obj_06_E_ChkSum 2;
BA_ "PF_Sig_Name" SG_ 973 VID_Obj_06_E_MsgCnt "BV_Obj_06_E_BZ";
BA_ "GenSigSendType" SG_ 973 VID_Obj_06_E_MsgCnt 0;
BA_ "GenSigFuncType" SG_ 973 VID_Obj_06_E_MsgCnt 1;
BA_ "PF_Sig_Name" SG_ 973 VID_Obj_06_E_BlockCnt "BV1_Obj_06_E_BlockZaehler";
BA_ "GenSigSendType" SG_ 973 VID_Obj_06_E_BlockCnt 3;
BA_ "PF_Sig_Name" SG_ 973 VID_Obj_06_Velocity_longitudinal "BV1_Obj_06_RadialGeschw";
BA_ "GenSigSendType" SG_ 973 VID_Obj_06_Velocity_longitudinal 0;
BA_ "GenSigStartValue" SG_ 973 VID_Obj_06_Velocity_longitudinal 2046;
BA_ "PF_Sig_Name" SG_ 973 VID_Obj_06_StdD_Velocity_longitu "BV1_Obj_06_RadialGeschw_StdA";
BA_ "GenSigSendType" SG_ 973 VID_Obj_06_StdD_Velocity_longitu 0;
BA_ "GenSigStartValue" SG_ 973 VID_Obj_06_StdD_Velocity_longitu 1022;
BA_ "SystemSignalLongSymbol" SG_ 973 VID_Obj_06_StdD_Velocity_longitu "VID_Obj_06_StdD_Velocity_longitudinal";
BA_ "PF_Sig_Name" SG_ 973 VID_Obj_06_StdD_Ang_Edge_R "BV_Objekt_06_sdv_phi_right";
BA_ "GenSigSendType" SG_ 973 VID_Obj_06_StdD_Ang_Edge_R 0;
BA_ "GenSigStartValue" SG_ 973 VID_Obj_06_StdD_Ang_Edge_R 512;
BA_ "PF_Sig_Name" SG_ 973 VID_Obj_06_ScaleChange "BV_Obj_06_ScaleChange";
BA_ "GenSigSendType" SG_ 973 VID_Obj_06_ScaleChange 0;
BA_ "PF_Sig_Name" SG_ 984 VID_Obj_07_A_ChkSum "BV_Obj_07_A_CRC";
BA_ "GenSigSendType" SG_ 984 VID_Obj_07_A_ChkSum 0;
BA_ "GenSigFuncType" SG_ 984 VID_Obj_07_A_ChkSum 2;
BA_ "PF_Sig_Name" SG_ 984 VID_Obj_07_A_MsgCnt "BV_Obj_07_A_BZ";
BA_ "GenSigSendType" SG_ 984 VID_Obj_07_A_MsgCnt 0;
BA_ "GenSigFuncType" SG_ 984 VID_Obj_07_A_MsgCnt 1;
BA_ "PF_Sig_Name" SG_ 984 VID_Obj_07_A_BlockCnt "BV1_Obj_07_A_BlockZaehler";
BA_ "GenSigSendType" SG_ 984 VID_Obj_07_A_BlockCnt 3;
BA_ "PF_Sig_Name" SG_ 984 VID_Obj_07_Dist_longitude "BV1_Obj_07_Dist_longitude";
BA_ "GenSigSendType" SG_ 984 VID_Obj_07_Dist_longitude 0;
BA_ "GenSigStartValue" SG_ 984 VID_Obj_07_Dist_longitude 4095;
BA_ "PF_Sig_Name" SG_ 984 VID_Obj_07_StdD_Dist_longitude "BV1_Obj_07_Dist_longitudeStdA";
BA_ "GenSigSendType" SG_ 984 VID_Obj_07_StdD_Dist_longitude 0;
BA_ "GenSigStartValue" SG_ 984 VID_Obj_07_StdD_Dist_longitude 127;
BA_ "PF_Sig_Name" SG_ 984 VID_Obj_07_Ang_Center "BV1_Obj_07_WnklMitte";
BA_ "GenSigSendType" SG_ 984 VID_Obj_07_Ang_Center 0;
BA_ "GenSigStartValue" SG_ 984 VID_Obj_07_Ang_Center 2047;
BA_ "PF_Sig_Name" SG_ 984 VID_Obj_07_Stat_Measure "BV1_Obj_07_Gemessen";
BA_ "GenSigSendType" SG_ 984 VID_Obj_07_Stat_Measure 0;
BA_ "PF_Sig_Name" SG_ 984 VID_Obj_07_StdD_Ang_Center "BV1_Obj_07_WnklMitteStdA";
BA_ "GenSigSendType" SG_ 984 VID_Obj_07_StdD_Ang_Center 0;
BA_ "GenSigStartValue" SG_ 984 VID_Obj_07_StdD_Ang_Center 255;
BA_ "PF_Sig_Name" SG_ 984 VID_Obj_07_Class "BV1_Obj_07_Klasse";
BA_ "GenSigSendType" SG_ 984 VID_Obj_07_Class 0;
BA_ "GenSigStartValue" SG_ 984 VID_Obj_07_Class 15;
BA_ "PF_Sig_Name" SG_ 984 VID_Obj_07_RefPoint "BV1_Obj_07_Bezugspunkt";
BA_ "GenSigSendType" SG_ 984 VID_Obj_07_RefPoint 0;
BA_ "GenSigStartValue" SG_ 984 VID_Obj_07_RefPoint 15;
BA_ "PF_Sig_Name" SG_ 985 VID_Obj_07_B_ChkSum "BV_Obj_07_B_CRC";
BA_ "GenSigSendType" SG_ 985 VID_Obj_07_B_ChkSum 0;
BA_ "GenSigFuncType" SG_ 985 VID_Obj_07_B_ChkSum 2;
BA_ "PF_Sig_Name" SG_ 985 VID_Obj_07_B_MsgCnt "BV_Obj_07_B_BZ";
BA_ "GenSigSendType" SG_ 985 VID_Obj_07_B_MsgCnt 0;
BA_ "GenSigFuncType" SG_ 985 VID_Obj_07_B_MsgCnt 1;
BA_ "PF_Sig_Name" SG_ 985 VID_Obj_07_B_BlockCnt "BV1_Obj_07_B_BlockZaehler";
BA_ "GenSigSendType" SG_ 985 VID_Obj_07_B_BlockCnt 3;
BA_ "PF_Sig_Name" SG_ 985 VID_Obj_07_Ang_Width "BV1_Obj_07_WnklBreite";
BA_ "GenSigSendType" SG_ 985 VID_Obj_07_Ang_Width 0;
BA_ "GenSigStartValue" SG_ 985 VID_Obj_07_Ang_Width 2047;
BA_ "PF_Sig_Name" SG_ 985 VID_Obj_07_ProbExist "BV1_Obj_07_ExistenzMass";
BA_ "GenSigSendType" SG_ 985 VID_Obj_07_ProbExist 0;
BA_ "GenSigStartValue" SG_ 985 VID_Obj_07_ProbExist 127;
BA_ "PF_Sig_Name" SG_ 985 VID_Obj_07_StdD_dAng_longitude "BV1_Obj_07_WnklGeschwStdA";
BA_ "GenSigSendType" SG_ 985 VID_Obj_07_StdD_dAng_longitude 0;
BA_ "GenSigStartValue" SG_ 985 VID_Obj_07_StdD_dAng_longitude 63;
BA_ "PF_Sig_Name" SG_ 985 VID_Obj_07_dAng_longitude "BV1_Obj_07_WnklGeschw";
BA_ "GenSigSendType" SG_ 985 VID_Obj_07_dAng_longitude 0;
BA_ "GenSigStartValue" SG_ 985 VID_Obj_07_dAng_longitude 511;
BA_ "PF_Sig_Name" SG_ 985 VID_Obj_07_StdD_Ang_Width "BV1_Obj_07_WnklBreiteStdA";
BA_ "GenSigSendType" SG_ 985 VID_Obj_07_StdD_Ang_Width 0;
BA_ "GenSigStartValue" SG_ 985 VID_Obj_07_StdD_Ang_Width 255;
BA_ "PF_Sig_Name" SG_ 986 VID_Obj_07_C_ChkSum "BV_Obj_07_C_CRC";
BA_ "GenSigSendType" SG_ 986 VID_Obj_07_C_ChkSum 0;
BA_ "GenSigFuncType" SG_ 986 VID_Obj_07_C_ChkSum 2;
BA_ "PF_Sig_Name" SG_ 986 VID_Obj_07_C_MsgCnt "BV_Obj_07_C_BZ";
BA_ "GenSigSendType" SG_ 986 VID_Obj_07_C_MsgCnt 0;
BA_ "GenSigFuncType" SG_ 986 VID_Obj_07_C_MsgCnt 1;
BA_ "PF_Sig_Name" SG_ 986 VID_Obj_07_C_BlockCnt "BV1_Obj_07_C_BlockZaehler";
BA_ "GenSigSendType" SG_ 986 VID_Obj_07_C_BlockCnt 3;
BA_ "PF_Sig_Name" SG_ 986 VID_Obj_07_InvTTC "BV1_Obj_07_InvTTCBildeb";
BA_ "GenSigSendType" SG_ 986 VID_Obj_07_InvTTC 0;
BA_ "GenSigStartValue" SG_ 986 VID_Obj_07_InvTTC 1023;
BA_ "PF_Sig_Name" SG_ 986 VID_Obj_07_StdD_InvTTC "BV1_Obj_07_InvTTCBildebStdA";
BA_ "GenSigSendType" SG_ 986 VID_Obj_07_StdD_InvTTC 0;
BA_ "GenSigStartValue" SG_ 986 VID_Obj_07_StdD_InvTTC 127;
BA_ "PF_Sig_Name" SG_ 986 VID_Obj_07_Ang_Overlap_EgoLane_R "BV1_Obj_07_UeberdWnklEgoSpurR";
BA_ "GenSigSendType" SG_ 986 VID_Obj_07_Ang_Overlap_EgoLane_R 0;
BA_ "GenSigStartValue" SG_ 986 VID_Obj_07_Ang_Overlap_EgoLane_R 511;
BA_ "PF_Sig_Name" SG_ 986 VID_Obj_07_Ang_Overlap_EgoLane_L "BV1_Obj_07_UeberdWnklEgoSpurL";
BA_ "GenSigSendType" SG_ 986 VID_Obj_07_Ang_Overlap_EgoLane_L 0;
BA_ "GenSigStartValue" SG_ 986 VID_Obj_07_Ang_Overlap_EgoLane_L 511;
BA_ "PF_Sig_Name" SG_ 986 VID_Obj_07_Obj_Age "BV1_Obj_07_Alter";
BA_ "GenSigSendType" SG_ 986 VID_Obj_07_Obj_Age 0;
BA_ "GenSigStartValue" SG_ 986 VID_Obj_07_Obj_Age 4095;
BA_ "PF_Sig_Name" SG_ 986 VID_Obj_07_BrakeLight "BV1_Obj_07_BremsLicht";
BA_ "GenSigSendType" SG_ 986 VID_Obj_07_BrakeLight 0;
BA_ "PF_Sig_Name" SG_ 987 VID_Obj_07_D_ChkSum "BV_Obj_07_D_CRC";
BA_ "GenSigSendType" SG_ 987 VID_Obj_07_D_ChkSum 0;
BA_ "GenSigFuncType" SG_ 987 VID_Obj_07_D_ChkSum 2;
BA_ "PF_Sig_Name" SG_ 987 VID_Obj_07_D_MsgCnt "BV_Obj_07_D_BZ";
BA_ "GenSigSendType" SG_ 987 VID_Obj_07_D_MsgCnt 0;
BA_ "GenSigFuncType" SG_ 987 VID_Obj_07_D_MsgCnt 1;
BA_ "PF_Sig_Name" SG_ 987 VID_Obj_07_D_BlockCnt "BV1_Obj_07_D_BlockZaehler";
BA_ "GenSigSendType" SG_ 987 VID_Obj_07_D_BlockCnt 3;
BA_ "PF_Sig_Name" SG_ 987 VID_Obj_07_Ang_Edge_L "BV_Objekt_07_phi_left";
BA_ "GenSigSendType" SG_ 987 VID_Obj_07_Ang_Edge_L 0;
BA_ "GenSigStartValue" SG_ 987 VID_Obj_07_Ang_Edge_L 1024;
BA_ "PF_Sig_Name" SG_ 987 VID_Obj_07_Ang_Edge_R "BV_Objekt_07_phi_right";
BA_ "GenSigSendType" SG_ 987 VID_Obj_07_Ang_Edge_R 0;
BA_ "GenSigStartValue" SG_ 987 VID_Obj_07_Ang_Edge_R 1024;
BA_ "PF_Sig_Name" SG_ 987 VID_Obj_07_StdD_Ang_Edge_L "BV_Objekt_07_sdv_phi_left";
BA_ "GenSigSendType" SG_ 987 VID_Obj_07_StdD_Ang_Edge_L 0;
BA_ "GenSigStartValue" SG_ 987 VID_Obj_07_StdD_Ang_Edge_L 512;
BA_ "PF_Sig_Name" SG_ 987 VID_Obj_07_Obj_ID "BV1_Obj_07_ID";
BA_ "GenSigSendType" SG_ 987 VID_Obj_07_Obj_ID 0;
BA_ "GenSigStartValue" SG_ 987 VID_Obj_07_Obj_ID 255;
BA_ "PF_Sig_Name" SG_ 974 VID_Obj_07_E_ChkSum "BV_Obj_07_E_CRC";
BA_ "GenSigSendType" SG_ 974 VID_Obj_07_E_ChkSum 0;
BA_ "GenSigFuncType" SG_ 974 VID_Obj_07_E_ChkSum 2;
BA_ "PF_Sig_Name" SG_ 974 VID_Obj_07_E_MsgCnt "BV_Obj_07_E_BZ";
BA_ "GenSigSendType" SG_ 974 VID_Obj_07_E_MsgCnt 0;
BA_ "GenSigFuncType" SG_ 974 VID_Obj_07_E_MsgCnt 1;
BA_ "PF_Sig_Name" SG_ 974 VID_Obj_07_E_BlockCnt "BV1_Obj_07_E_BlockZaehler";
BA_ "GenSigSendType" SG_ 974 VID_Obj_07_E_BlockCnt 3;
BA_ "PF_Sig_Name" SG_ 974 VID_Obj_07_Velocity_longitudinal "BV1_Obj_07_RadialGeschw";
BA_ "GenSigSendType" SG_ 974 VID_Obj_07_Velocity_longitudinal 0;
BA_ "GenSigStartValue" SG_ 974 VID_Obj_07_Velocity_longitudinal 2046;
BA_ "PF_Sig_Name" SG_ 974 VID_Obj_07_StdD_Velocity_longitu "BV1_Obj_07_RadialGeschw_StdA";
BA_ "GenSigSendType" SG_ 974 VID_Obj_07_StdD_Velocity_longitu 0;
BA_ "GenSigStartValue" SG_ 974 VID_Obj_07_StdD_Velocity_longitu 1022;
BA_ "SystemSignalLongSymbol" SG_ 974 VID_Obj_07_StdD_Velocity_longitu "VID_Obj_07_StdD_Velocity_longitudinal";
BA_ "PF_Sig_Name" SG_ 974 VID_Obj_07_StdD_Ang_Edge_R "BV_Objekt_07_sdv_phi_right";
BA_ "GenSigSendType" SG_ 974 VID_Obj_07_StdD_Ang_Edge_R 0;
BA_ "GenSigStartValue" SG_ 974 VID_Obj_07_StdD_Ang_Edge_R 512;
BA_ "PF_Sig_Name" SG_ 974 VID_Obj_07_ScaleChange "BV_Obj_07_ScaleChange";
BA_ "GenSigSendType" SG_ 974 VID_Obj_07_ScaleChange 0;
BA_ "PF_Sig_Name" SG_ 988 VID_Obj_08_A_ChkSum "BV_Obj_08_A_CRC";
BA_ "GenSigSendType" SG_ 988 VID_Obj_08_A_ChkSum 0;
BA_ "GenSigFuncType" SG_ 988 VID_Obj_08_A_ChkSum 2;
BA_ "PF_Sig_Name" SG_ 988 VID_Obj_08_A_MsgCnt "BV_Obj_08_A_BZ";
BA_ "GenSigSendType" SG_ 988 VID_Obj_08_A_MsgCnt 0;
BA_ "GenSigFuncType" SG_ 988 VID_Obj_08_A_MsgCnt 1;
BA_ "PF_Sig_Name" SG_ 988 VID_Obj_08_A_BlockCnt "BV1_Obj_08_A_BlockZaehler";
BA_ "GenSigSendType" SG_ 988 VID_Obj_08_A_BlockCnt 3;
BA_ "PF_Sig_Name" SG_ 988 VID_Obj_08_Dist_longitude "BV1_Obj_08_Dist_longitude";
BA_ "GenSigSendType" SG_ 988 VID_Obj_08_Dist_longitude 0;
BA_ "GenSigStartValue" SG_ 988 VID_Obj_08_Dist_longitude 4095;
BA_ "PF_Sig_Name" SG_ 988 VID_Obj_08_StdD_Dist_longitude "BV1_Obj_08_Dist_longitudeStdA";
BA_ "GenSigSendType" SG_ 988 VID_Obj_08_StdD_Dist_longitude 0;
BA_ "GenSigStartValue" SG_ 988 VID_Obj_08_StdD_Dist_longitude 127;
BA_ "PF_Sig_Name" SG_ 988 VID_Obj_08_Ang_Center "BV1_Obj_08_WnklMitte";
BA_ "GenSigSendType" SG_ 988 VID_Obj_08_Ang_Center 0;
BA_ "GenSigStartValue" SG_ 988 VID_Obj_08_Ang_Center 2047;
BA_ "PF_Sig_Name" SG_ 988 VID_Obj_08_Stat_Measure "BV1_Obj_08_Gemessen";
BA_ "GenSigSendType" SG_ 988 VID_Obj_08_Stat_Measure 0;
BA_ "PF_Sig_Name" SG_ 988 VID_Obj_08_StdD_Ang_Center "BV1_Obj_08_WnklMitteStdA";
BA_ "GenSigSendType" SG_ 988 VID_Obj_08_StdD_Ang_Center 0;
BA_ "GenSigStartValue" SG_ 988 VID_Obj_08_StdD_Ang_Center 255;
BA_ "PF_Sig_Name" SG_ 988 VID_Obj_08_Class "BV1_Obj_08_Klasse";
BA_ "GenSigSendType" SG_ 988 VID_Obj_08_Class 0;
BA_ "GenSigStartValue" SG_ 988 VID_Obj_08_Class 15;
BA_ "PF_Sig_Name" SG_ 988 VID_Obj_08_RefPoint "BV1_Obj_08_Bezugspunkt";
BA_ "GenSigSendType" SG_ 988 VID_Obj_08_RefPoint 0;
BA_ "GenSigStartValue" SG_ 988 VID_Obj_08_RefPoint 15;
BA_ "PF_Sig_Name" SG_ 989 VID_Obj_08_B_ChkSum "BV_Obj_08_B_CRC";
BA_ "GenSigSendType" SG_ 989 VID_Obj_08_B_ChkSum 0;
BA_ "GenSigFuncType" SG_ 989 VID_Obj_08_B_ChkSum 2;
BA_ "PF_Sig_Name" SG_ 989 VID_Obj_08_B_MsgCnt "BV_Obj_08_B_BZ";
BA_ "GenSigSendType" SG_ 989 VID_Obj_08_B_MsgCnt 0;
BA_ "GenSigFuncType" SG_ 989 VID_Obj_08_B_MsgCnt 1;
BA_ "PF_Sig_Name" SG_ 989 VID_Obj_08_B_BlockCnt "BV1_Obj_08_B_BlockZaehler";
BA_ "GenSigSendType" SG_ 989 VID_Obj_08_B_BlockCnt 3;
BA_ "PF_Sig_Name" SG_ 989 VID_Obj_08_Ang_Width "BV1_Obj_08_WnklBreite";
BA_ "GenSigSendType" SG_ 989 VID_Obj_08_Ang_Width 0;
BA_ "GenSigStartValue" SG_ 989 VID_Obj_08_Ang_Width 2047;
BA_ "PF_Sig_Name" SG_ 989 VID_Obj_08_ProbExist "BV1_Obj_08_ExistenzMass";
BA_ "GenSigSendType" SG_ 989 VID_Obj_08_ProbExist 0;
BA_ "GenSigStartValue" SG_ 989 VID_Obj_08_ProbExist 127;
BA_ "PF_Sig_Name" SG_ 989 VID_Obj_08_StdD_dAng_longitude "BV1_Obj_08_WnklGeschwStdA";
BA_ "GenSigSendType" SG_ 989 VID_Obj_08_StdD_dAng_longitude 0;
BA_ "GenSigStartValue" SG_ 989 VID_Obj_08_StdD_dAng_longitude 63;
BA_ "PF_Sig_Name" SG_ 989 VID_Obj_08_dAng_longitude "BV1_Obj_08_WnklGeschw";
BA_ "GenSigSendType" SG_ 989 VID_Obj_08_dAng_longitude 0;
BA_ "GenSigStartValue" SG_ 989 VID_Obj_08_dAng_longitude 511;
BA_ "PF_Sig_Name" SG_ 989 VID_Obj_08_StdD_Ang_Width "BV1_Obj_08_WnklBreiteStdA";
BA_ "GenSigSendType" SG_ 989 VID_Obj_08_StdD_Ang_Width 0;
BA_ "GenSigStartValue" SG_ 989 VID_Obj_08_StdD_Ang_Width 255;
BA_ "PF_Sig_Name" SG_ 990 VID_Obj_08_C_ChkSum "BV_Obj_08_C_CRC";
BA_ "GenSigSendType" SG_ 990 VID_Obj_08_C_ChkSum 0;
BA_ "GenSigFuncType" SG_ 990 VID_Obj_08_C_ChkSum 2;
BA_ "PF_Sig_Name" SG_ 990 VID_Obj_08_C_MsgCnt "BV_Obj_08_C_BZ";
BA_ "GenSigSendType" SG_ 990 VID_Obj_08_C_MsgCnt 0;
BA_ "GenSigFuncType" SG_ 990 VID_Obj_08_C_MsgCnt 1;
BA_ "PF_Sig_Name" SG_ 990 VID_Obj_08_C_BlockCnt "BV1_Obj_08_C_BlockZaehler";
BA_ "GenSigSendType" SG_ 990 VID_Obj_08_C_BlockCnt 3;
BA_ "PF_Sig_Name" SG_ 990 VID_Obj_08_InvTTC "BV1_Obj_08_InvTTCBildeb";
BA_ "GenSigSendType" SG_ 990 VID_Obj_08_InvTTC 0;
BA_ "GenSigStartValue" SG_ 990 VID_Obj_08_InvTTC 1023;
BA_ "PF_Sig_Name" SG_ 990 VID_Obj_08_StdD_InvTTC "BV1_Obj_08_InvTTCBildebStdA";
BA_ "GenSigSendType" SG_ 990 VID_Obj_08_StdD_InvTTC 0;
BA_ "GenSigStartValue" SG_ 990 VID_Obj_08_StdD_InvTTC 127;
BA_ "PF_Sig_Name" SG_ 990 VID_Obj_08_Ang_Overlap_EgoLane_R "BV1_Obj_08_UeberdWnklEgoSpurR";
BA_ "GenSigSendType" SG_ 990 VID_Obj_08_Ang_Overlap_EgoLane_R 0;
BA_ "GenSigStartValue" SG_ 990 VID_Obj_08_Ang_Overlap_EgoLane_R 511;
BA_ "PF_Sig_Name" SG_ 990 VID_Obj_08_Ang_Overlap_EgoLane_L "BV1_Obj_08_UeberdWnklEgoSpurL";
BA_ "GenSigSendType" SG_ 990 VID_Obj_08_Ang_Overlap_EgoLane_L 0;
BA_ "GenSigStartValue" SG_ 990 VID_Obj_08_Ang_Overlap_EgoLane_L 511;
BA_ "PF_Sig_Name" SG_ 990 VID_Obj_08_Obj_Age "BV1_Obj_08_Alter";
BA_ "GenSigSendType" SG_ 990 VID_Obj_08_Obj_Age 0;
BA_ "GenSigStartValue" SG_ 990 VID_Obj_08_Obj_Age 4095;
BA_ "PF_Sig_Name" SG_ 990 VID_Obj_08_BrakeLight "BV1_Obj_08_BremsLicht";
BA_ "GenSigSendType" SG_ 990 VID_Obj_08_BrakeLight 0;
BA_ "PF_Sig_Name" SG_ 991 VID_Obj_08_D_ChkSum "BV_Obj_08_D_CRC";
BA_ "GenSigSendType" SG_ 991 VID_Obj_08_D_ChkSum 0;
BA_ "GenSigFuncType" SG_ 991 VID_Obj_08_D_ChkSum 2;
BA_ "PF_Sig_Name" SG_ 991 VID_Obj_08_D_MsgCnt "BV_Obj_08_D_BZ";
BA_ "GenSigSendType" SG_ 991 VID_Obj_08_D_MsgCnt 0;
BA_ "GenSigFuncType" SG_ 991 VID_Obj_08_D_MsgCnt 1;
BA_ "PF_Sig_Name" SG_ 991 VID_Obj_08_D_BlockCnt "BV1_Obj_08_D_BlockZaehler";
BA_ "GenSigSendType" SG_ 991 VID_Obj_08_D_BlockCnt 3;
BA_ "PF_Sig_Name" SG_ 991 VID_Obj_08_Ang_Edge_L "BV_Objekt_08_phi_left";
BA_ "GenSigSendType" SG_ 991 VID_Obj_08_Ang_Edge_L 0;
BA_ "GenSigStartValue" SG_ 991 VID_Obj_08_Ang_Edge_L 1024;
BA_ "PF_Sig_Name" SG_ 991 VID_Obj_08_Ang_Edge_R "BV_Objekt_08_phi_right";
BA_ "GenSigSendType" SG_ 991 VID_Obj_08_Ang_Edge_R 0;
BA_ "GenSigStartValue" SG_ 991 VID_Obj_08_Ang_Edge_R 1024;
BA_ "PF_Sig_Name" SG_ 991 VID_Obj_08_StdD_Ang_Edge_L "BV_Objekt_08_sdv_phi_left";
BA_ "GenSigSendType" SG_ 991 VID_Obj_08_StdD_Ang_Edge_L 0;
BA_ "GenSigStartValue" SG_ 991 VID_Obj_08_StdD_Ang_Edge_L 512;
BA_ "PF_Sig_Name" SG_ 991 VID_Obj_08_Obj_ID "BV1_Obj_08_ID";
BA_ "GenSigSendType" SG_ 991 VID_Obj_08_Obj_ID 0;
BA_ "GenSigStartValue" SG_ 991 VID_Obj_08_Obj_ID 255;
BA_ "PF_Sig_Name" SG_ 975 VID_Obj_08_E_ChkSum "BV_Obj_08_E_CRC";
BA_ "GenSigSendType" SG_ 975 VID_Obj_08_E_ChkSum 0;
BA_ "GenSigFuncType" SG_ 975 VID_Obj_08_E_ChkSum 2;
BA_ "PF_Sig_Name" SG_ 975 VID_Obj_08_E_MsgCnt "BV_Obj_08_E_BZ";
BA_ "GenSigSendType" SG_ 975 VID_Obj_08_E_MsgCnt 0;
BA_ "GenSigFuncType" SG_ 975 VID_Obj_08_E_MsgCnt 1;
BA_ "PF_Sig_Name" SG_ 975 VID_Obj_08_E_BlockCnt "BV1_Obj_08_E_BlockZaehler";
BA_ "GenSigSendType" SG_ 975 VID_Obj_08_E_BlockCnt 3;
BA_ "PF_Sig_Name" SG_ 975 VID_Obj_08_Velocity_longitudinal "BV1_Obj_08_RadialGeschw";
BA_ "GenSigSendType" SG_ 975 VID_Obj_08_Velocity_longitudinal 0;
BA_ "GenSigStartValue" SG_ 975 VID_Obj_08_Velocity_longitudinal 2046;
BA_ "PF_Sig_Name" SG_ 975 VID_Obj_08_StdD_Velocity_longitu "BV1_Obj_08_RadialGeschw_StdA";
BA_ "GenSigSendType" SG_ 975 VID_Obj_08_StdD_Velocity_longitu 0;
BA_ "GenSigStartValue" SG_ 975 VID_Obj_08_StdD_Velocity_longitu 1022;
BA_ "SystemSignalLongSymbol" SG_ 975 VID_Obj_08_StdD_Velocity_longitu "VID_Obj_08_StdD_Velocity_longitudinal";
BA_ "PF_Sig_Name" SG_ 975 VID_Obj_08_StdD_Ang_Edge_R "BV_Objekt_08_sdv_phi_right";
BA_ "GenSigSendType" SG_ 975 VID_Obj_08_StdD_Ang_Edge_R 0;
BA_ "GenSigStartValue" SG_ 975 VID_Obj_08_StdD_Ang_Edge_R 512;
BA_ "PF_Sig_Name" SG_ 975 VID_Obj_08_ScaleChange "BV_Obj_08_ScaleChange";
BA_ "GenSigSendType" SG_ 975 VID_Obj_08_ScaleChange 0;
BA_ "PF_Sig_Name" SG_ 992 VID_Obj_09_A_ChkSum "BV_Obj_09_A_CRC";
BA_ "GenSigSendType" SG_ 992 VID_Obj_09_A_ChkSum 0;
BA_ "GenSigFuncType" SG_ 992 VID_Obj_09_A_ChkSum 2;
BA_ "PF_Sig_Name" SG_ 992 VID_Obj_09_A_MsgCnt "BV_Obj_09_A_BZ";
BA_ "GenSigSendType" SG_ 992 VID_Obj_09_A_MsgCnt 0;
BA_ "GenSigFuncType" SG_ 992 VID_Obj_09_A_MsgCnt 1;
BA_ "PF_Sig_Name" SG_ 992 VID_Obj_09_A_BlockCnt "BV1_Obj_09_A_BlockZaehler";
BA_ "GenSigSendType" SG_ 992 VID_Obj_09_A_BlockCnt 3;
BA_ "PF_Sig_Name" SG_ 992 VID_Obj_09_Dist_longitude "BV1_Obj_09_Dist_longitude";
BA_ "GenSigSendType" SG_ 992 VID_Obj_09_Dist_longitude 0;
BA_ "GenSigStartValue" SG_ 992 VID_Obj_09_Dist_longitude 4095;
BA_ "PF_Sig_Name" SG_ 992 VID_Obj_09_StdD_Dist_longitude "BV1_Obj_09_Dist_longitudeStdA";
BA_ "GenSigSendType" SG_ 992 VID_Obj_09_StdD_Dist_longitude 0;
BA_ "GenSigStartValue" SG_ 992 VID_Obj_09_StdD_Dist_longitude 127;
BA_ "PF_Sig_Name" SG_ 992 VID_Obj_09_Ang_Center "BV1_Obj_09_WnklMitte";
BA_ "GenSigSendType" SG_ 992 VID_Obj_09_Ang_Center 0;
BA_ "GenSigStartValue" SG_ 992 VID_Obj_09_Ang_Center 2047;
BA_ "PF_Sig_Name" SG_ 992 VID_Obj_09_Stat_Measure "BV1_Obj_09_Gemessen";
BA_ "GenSigSendType" SG_ 992 VID_Obj_09_Stat_Measure 0;
BA_ "PF_Sig_Name" SG_ 992 VID_Obj_09_StdD_Ang_Center "BV1_Obj_09_WnklMitteStdA";
BA_ "GenSigSendType" SG_ 992 VID_Obj_09_StdD_Ang_Center 0;
BA_ "GenSigStartValue" SG_ 992 VID_Obj_09_StdD_Ang_Center 255;
BA_ "PF_Sig_Name" SG_ 992 VID_Obj_09_Class "BV1_Obj_09_Klasse";
BA_ "GenSigSendType" SG_ 992 VID_Obj_09_Class 0;
BA_ "GenSigStartValue" SG_ 992 VID_Obj_09_Class 15;
BA_ "PF_Sig_Name" SG_ 992 VID_Obj_09_RefPoint "BV1_Obj_09_Bezugspunkt";
BA_ "GenSigSendType" SG_ 992 VID_Obj_09_RefPoint 0;
BA_ "GenSigStartValue" SG_ 992 VID_Obj_09_RefPoint 15;
BA_ "PF_Sig_Name" SG_ 993 VID_Obj_09_B_ChkSum "BV_Obj_09_B_CRC";
BA_ "GenSigSendType" SG_ 993 VID_Obj_09_B_ChkSum 0;
BA_ "GenSigFuncType" SG_ 993 VID_Obj_09_B_ChkSum 2;
BA_ "PF_Sig_Name" SG_ 993 VID_Obj_09_B_MsgCnt "BV_Obj_09_B_BZ";
BA_ "GenSigSendType" SG_ 993 VID_Obj_09_B_MsgCnt 0;
BA_ "GenSigFuncType" SG_ 993 VID_Obj_09_B_MsgCnt 1;
BA_ "PF_Sig_Name" SG_ 993 VID_Obj_09_B_BlockCnt "BV1_Obj_09_B_BlockZaehler";
BA_ "GenSigSendType" SG_ 993 VID_Obj_09_B_BlockCnt 3;
BA_ "PF_Sig_Name" SG_ 993 VID_Obj_09_Ang_Width "BV1_Obj_09_WnklBreite";
BA_ "GenSigSendType" SG_ 993 VID_Obj_09_Ang_Width 0;
BA_ "GenSigStartValue" SG_ 993 VID_Obj_09_Ang_Width 2047;
BA_ "PF_Sig_Name" SG_ 993 VID_Obj_09_ProbExist "BV1_Obj_09_ExistenzMass";
BA_ "GenSigSendType" SG_ 993 VID_Obj_09_ProbExist 0;
BA_ "GenSigStartValue" SG_ 993 VID_Obj_09_ProbExist 127;
BA_ "PF_Sig_Name" SG_ 993 VID_Obj_09_StdD_dAng_longitude "BV1_Obj_09_WnklGeschwStdA";
BA_ "GenSigSendType" SG_ 993 VID_Obj_09_StdD_dAng_longitude 0;
BA_ "GenSigStartValue" SG_ 993 VID_Obj_09_StdD_dAng_longitude 63;
BA_ "PF_Sig_Name" SG_ 993 VID_Obj_09_dAng_longitude "BV1_Obj_09_WnklGeschw";
BA_ "GenSigSendType" SG_ 993 VID_Obj_09_dAng_longitude 0;
BA_ "GenSigStartValue" SG_ 993 VID_Obj_09_dAng_longitude 511;
BA_ "PF_Sig_Name" SG_ 993 VID_Obj_09_StdD_Ang_Width "BV1_Obj_09_WnklBreiteStdA";
BA_ "GenSigSendType" SG_ 993 VID_Obj_09_StdD_Ang_Width 0;
BA_ "GenSigStartValue" SG_ 993 VID_Obj_09_StdD_Ang_Width 255;
BA_ "PF_Sig_Name" SG_ 994 VID_Obj_09_C_ChkSum "BV_Obj_09_C_CRC";
BA_ "GenSigSendType" SG_ 994 VID_Obj_09_C_ChkSum 0;
BA_ "GenSigFuncType" SG_ 994 VID_Obj_09_C_ChkSum 2;
BA_ "PF_Sig_Name" SG_ 994 VID_Obj_09_C_MsgCnt "BV_Obj_09_C_BZ";
BA_ "GenSigSendType" SG_ 994 VID_Obj_09_C_MsgCnt 0;
BA_ "GenSigFuncType" SG_ 994 VID_Obj_09_C_MsgCnt 1;
BA_ "PF_Sig_Name" SG_ 994 VID_Obj_09_C_BlockCnt "BV1_Obj_09_C_BlockZaehler";
BA_ "GenSigSendType" SG_ 994 VID_Obj_09_C_BlockCnt 3;
BA_ "PF_Sig_Name" SG_ 994 VID_Obj_09_InvTTC "BV1_Obj_09_InvTTCBildeb";
BA_ "GenSigSendType" SG_ 994 VID_Obj_09_InvTTC 0;
BA_ "GenSigStartValue" SG_ 994 VID_Obj_09_InvTTC 1023;
BA_ "PF_Sig_Name" SG_ 994 VID_Obj_09_StdD_InvTTC "BV1_Obj_09_InvTTCBildebStdA";
BA_ "GenSigSendType" SG_ 994 VID_Obj_09_StdD_InvTTC 0;
BA_ "GenSigStartValue" SG_ 994 VID_Obj_09_StdD_InvTTC 127;
BA_ "PF_Sig_Name" SG_ 994 VID_Obj_09_Ang_Overlap_EgoLane_R "BV1_Obj_09_UeberdWnklEgoSpurR";
BA_ "GenSigSendType" SG_ 994 VID_Obj_09_Ang_Overlap_EgoLane_R 0;
BA_ "GenSigStartValue" SG_ 994 VID_Obj_09_Ang_Overlap_EgoLane_R 511;
BA_ "PF_Sig_Name" SG_ 994 VID_Obj_09_Ang_Overlap_EgoLane_L "BV1_Obj_09_UeberdWnklEgoSpurL";
BA_ "GenSigSendType" SG_ 994 VID_Obj_09_Ang_Overlap_EgoLane_L 0;
BA_ "GenSigStartValue" SG_ 994 VID_Obj_09_Ang_Overlap_EgoLane_L 511;
BA_ "PF_Sig_Name" SG_ 994 VID_Obj_09_Obj_Age "BV1_Obj_09_Alter";
BA_ "GenSigSendType" SG_ 994 VID_Obj_09_Obj_Age 0;
BA_ "GenSigStartValue" SG_ 994 VID_Obj_09_Obj_Age 4095;
BA_ "PF_Sig_Name" SG_ 994 VID_Obj_09_BrakeLight "BV1_Obj_09_BremsLicht";
BA_ "GenSigSendType" SG_ 994 VID_Obj_09_BrakeLight 0;
BA_ "PF_Sig_Name" SG_ 995 VID_Obj_09_D_ChkSum "BV_Obj_09_D_CRC";
BA_ "GenSigSendType" SG_ 995 VID_Obj_09_D_ChkSum 0;
BA_ "GenSigFuncType" SG_ 995 VID_Obj_09_D_ChkSum 2;
BA_ "PF_Sig_Name" SG_ 995 VID_Obj_09_D_MsgCnt "BV_Obj_09_D_BZ";
BA_ "GenSigSendType" SG_ 995 VID_Obj_09_D_MsgCnt 0;
BA_ "GenSigFuncType" SG_ 995 VID_Obj_09_D_MsgCnt 1;
BA_ "PF_Sig_Name" SG_ 995 VID_Obj_09_D_BlockCnt "BV1_Obj_09_D_BlockZaehler";
BA_ "GenSigSendType" SG_ 995 VID_Obj_09_D_BlockCnt 3;
BA_ "PF_Sig_Name" SG_ 995 VID_Obj_09_Ang_Edge_L "BV_Objekt_09_phi_left";
BA_ "GenSigSendType" SG_ 995 VID_Obj_09_Ang_Edge_L 0;
BA_ "GenSigStartValue" SG_ 995 VID_Obj_09_Ang_Edge_L 1024;
BA_ "PF_Sig_Name" SG_ 995 VID_Obj_09_Ang_Edge_R "BV_Objekt_09_phi_right";
BA_ "GenSigSendType" SG_ 995 VID_Obj_09_Ang_Edge_R 0;
BA_ "GenSigStartValue" SG_ 995 VID_Obj_09_Ang_Edge_R 1024;
BA_ "PF_Sig_Name" SG_ 995 VID_Obj_09_StdD_Ang_Edge_L "BV_Objekt_09_sdv_phi_left";
BA_ "GenSigSendType" SG_ 995 VID_Obj_09_StdD_Ang_Edge_L 0;
BA_ "GenSigStartValue" SG_ 995 VID_Obj_09_StdD_Ang_Edge_L 512;
BA_ "PF_Sig_Name" SG_ 995 VID_Obj_09_Obj_ID "BV1_Obj_09_ID";
BA_ "GenSigSendType" SG_ 995 VID_Obj_09_Obj_ID 0;
BA_ "GenSigStartValue" SG_ 995 VID_Obj_09_Obj_ID 255;
BA_ "PF_Sig_Name" SG_ 912 VID_Obj_09_E_ChkSum "BV_Obj_09_E_CRC";
BA_ "GenSigSendType" SG_ 912 VID_Obj_09_E_ChkSum 0;
BA_ "GenSigFuncType" SG_ 912 VID_Obj_09_E_ChkSum 2;
BA_ "PF_Sig_Name" SG_ 912 VID_Obj_09_E_MsgCnt "BV_Obj_09_E_BZ";
BA_ "GenSigSendType" SG_ 912 VID_Obj_09_E_MsgCnt 0;
BA_ "GenSigFuncType" SG_ 912 VID_Obj_09_E_MsgCnt 1;
BA_ "PF_Sig_Name" SG_ 912 VID_Obj_09_E_BlockCnt "BV1_Obj_09_E_BlockZaehler";
BA_ "GenSigSendType" SG_ 912 VID_Obj_09_E_BlockCnt 3;
BA_ "PF_Sig_Name" SG_ 912 VID_Obj_09_Velocity_longitudinal "BV1_Obj_09_RadialGeschw";
BA_ "GenSigSendType" SG_ 912 VID_Obj_09_Velocity_longitudinal 0;
BA_ "GenSigStartValue" SG_ 912 VID_Obj_09_Velocity_longitudinal 2046;
BA_ "PF_Sig_Name" SG_ 912 VID_Obj_09_StdD_Velocity_longitu "BV1_Obj_09_RadialGeschw_StdA";
BA_ "GenSigSendType" SG_ 912 VID_Obj_09_StdD_Velocity_longitu 0;
BA_ "GenSigStartValue" SG_ 912 VID_Obj_09_StdD_Velocity_longitu 1022;
BA_ "SystemSignalLongSymbol" SG_ 912 VID_Obj_09_StdD_Velocity_longitu "VID_Obj_09_StdD_Velocity_longitudinal";
BA_ "PF_Sig_Name" SG_ 912 VID_Obj_09_StdD_Ang_Edge_R "BV_Objekt_09_sdv_phi_right";
BA_ "GenSigSendType" SG_ 912 VID_Obj_09_StdD_Ang_Edge_R 0;
BA_ "GenSigStartValue" SG_ 912 VID_Obj_09_StdD_Ang_Edge_R 512;
BA_ "PF_Sig_Name" SG_ 912 VID_Obj_09_ScaleChange "BV_Obj_09_ScaleChange";
BA_ "GenSigSendType" SG_ 912 VID_Obj_09_ScaleChange 0;
BA_ "PF_Sig_Name" SG_ 996 VID_Obj_10_A_ChkSum "BV_Obj_10_A_CRC";
BA_ "GenSigSendType" SG_ 996 VID_Obj_10_A_ChkSum 0;
BA_ "GenSigFuncType" SG_ 996 VID_Obj_10_A_ChkSum 2;
BA_ "PF_Sig_Name" SG_ 996 VID_Obj_10_A_MsgCnt "BV_Obj_10_A_BZ";
BA_ "GenSigSendType" SG_ 996 VID_Obj_10_A_MsgCnt 0;
BA_ "GenSigFuncType" SG_ 996 VID_Obj_10_A_MsgCnt 1;
BA_ "PF_Sig_Name" SG_ 996 VID_Obj_10_A_BlockCnt "BV1_Obj_10_A_BlockZaehler";
BA_ "GenSigSendType" SG_ 996 VID_Obj_10_A_BlockCnt 3;
BA_ "PF_Sig_Name" SG_ 996 VID_Obj_10_Dist_longitude "BV1_Obj_10_Dist_longitude";
BA_ "GenSigSendType" SG_ 996 VID_Obj_10_Dist_longitude 0;
BA_ "GenSigStartValue" SG_ 996 VID_Obj_10_Dist_longitude 4095;
BA_ "PF_Sig_Name" SG_ 996 VID_Obj_10_StdD_Dist_longitude "BV1_Obj_10_Dist_longitudeStdA";
BA_ "GenSigSendType" SG_ 996 VID_Obj_10_StdD_Dist_longitude 0;
BA_ "GenSigStartValue" SG_ 996 VID_Obj_10_StdD_Dist_longitude 127;
BA_ "PF_Sig_Name" SG_ 996 VID_Obj_10_Ang_Center "BV1_Obj_10_WnklMitte";
BA_ "GenSigSendType" SG_ 996 VID_Obj_10_Ang_Center 0;
BA_ "GenSigStartValue" SG_ 996 VID_Obj_10_Ang_Center 2047;
BA_ "PF_Sig_Name" SG_ 996 VID_Obj_10_Stat_Measure "BV1_Obj_10_Gemessen";
BA_ "GenSigSendType" SG_ 996 VID_Obj_10_Stat_Measure 0;
BA_ "PF_Sig_Name" SG_ 996 VID_Obj_10_StdD_Ang_Center "BV1_Obj_10_WnklMitteStdA";
BA_ "GenSigSendType" SG_ 996 VID_Obj_10_StdD_Ang_Center 0;
BA_ "GenSigStartValue" SG_ 996 VID_Obj_10_StdD_Ang_Center 255;
BA_ "PF_Sig_Name" SG_ 996 VID_Obj_10_Class "BV1_Obj_10_Klasse";
BA_ "GenSigSendType" SG_ 996 VID_Obj_10_Class 0;
BA_ "GenSigStartValue" SG_ 996 VID_Obj_10_Class 15;
BA_ "PF_Sig_Name" SG_ 996 VID_Obj_10_RefPoint "BV1_Obj_10_Bezugspunkt";
BA_ "GenSigSendType" SG_ 996 VID_Obj_10_RefPoint 0;
BA_ "GenSigStartValue" SG_ 996 VID_Obj_10_RefPoint 15;
BA_ "PF_Sig_Name" SG_ 997 VID_Obj_10_B_ChkSum "BV_Obj_10_B_CRC";
BA_ "GenSigSendType" SG_ 997 VID_Obj_10_B_ChkSum 0;
BA_ "GenSigFuncType" SG_ 997 VID_Obj_10_B_ChkSum 2;
BA_ "PF_Sig_Name" SG_ 997 VID_Obj_10_B_MsgCnt "BV_Obj_10_B_BZ";
BA_ "GenSigSendType" SG_ 997 VID_Obj_10_B_MsgCnt 0;
BA_ "GenSigFuncType" SG_ 997 VID_Obj_10_B_MsgCnt 1;
BA_ "PF_Sig_Name" SG_ 997 VID_Obj_10_B_BlockCnt "BV1_Obj_10_B_BlockZaehler";
BA_ "GenSigSendType" SG_ 997 VID_Obj_10_B_BlockCnt 3;
BA_ "PF_Sig_Name" SG_ 997 VID_Obj_10_Ang_Width "BV1_Obj_10_WnklBreite";
BA_ "GenSigSendType" SG_ 997 VID_Obj_10_Ang_Width 0;
BA_ "GenSigStartValue" SG_ 997 VID_Obj_10_Ang_Width 2047;
BA_ "PF_Sig_Name" SG_ 997 VID_Obj_10_ProbExist "BV1_Obj_10_ExistenzMass";
BA_ "GenSigSendType" SG_ 997 VID_Obj_10_ProbExist 0;
BA_ "GenSigStartValue" SG_ 997 VID_Obj_10_ProbExist 127;
BA_ "PF_Sig_Name" SG_ 997 VID_Obj_10_StdD_dAng_longitude "BV1_Obj_10_WnklGeschwStdA";
BA_ "GenSigSendType" SG_ 997 VID_Obj_10_StdD_dAng_longitude 0;
BA_ "GenSigStartValue" SG_ 997 VID_Obj_10_StdD_dAng_longitude 63;
BA_ "PF_Sig_Name" SG_ 997 VID_Obj_10_dAng_longitude "BV1_Obj_10_WnklGeschw";
BA_ "GenSigSendType" SG_ 997 VID_Obj_10_dAng_longitude 0;
BA_ "GenSigStartValue" SG_ 997 VID_Obj_10_dAng_longitude 511;
BA_ "PF_Sig_Name" SG_ 997 VID_Obj_10_StdD_Ang_Width "BV1_Obj_10_WnklBreiteStdA";
BA_ "GenSigSendType" SG_ 997 VID_Obj_10_StdD_Ang_Width 0;
BA_ "GenSigStartValue" SG_ 997 VID_Obj_10_StdD_Ang_Width 255;
BA_ "PF_Sig_Name" SG_ 998 VID_Obj_10_C_ChkSum "BV_Obj_10_C_CRC";
BA_ "GenSigSendType" SG_ 998 VID_Obj_10_C_ChkSum 0;
BA_ "GenSigFuncType" SG_ 998 VID_Obj_10_C_ChkSum 2;
BA_ "PF_Sig_Name" SG_ 998 VID_Obj_10_C_MsgCnt "BV_Obj_10_C_BZ";
BA_ "GenSigSendType" SG_ 998 VID_Obj_10_C_MsgCnt 0;
BA_ "GenSigFuncType" SG_ 998 VID_Obj_10_C_MsgCnt 1;
BA_ "PF_Sig_Name" SG_ 998 VID_Obj_10_C_BlockCnt "BV1_Obj_10_C_BlockZaehler";
BA_ "GenSigSendType" SG_ 998 VID_Obj_10_C_BlockCnt 3;
BA_ "PF_Sig_Name" SG_ 998 VID_Obj_10_InvTTC "BV1_Obj_10_InvTTCBildeb";
BA_ "GenSigSendType" SG_ 998 VID_Obj_10_InvTTC 0;
BA_ "GenSigStartValue" SG_ 998 VID_Obj_10_InvTTC 1023;
BA_ "PF_Sig_Name" SG_ 998 VID_Obj_10_StdD_InvTTC "BV1_Obj_10_InvTTCBildebStdA";
BA_ "GenSigSendType" SG_ 998 VID_Obj_10_StdD_InvTTC 0;
BA_ "GenSigStartValue" SG_ 998 VID_Obj_10_StdD_InvTTC 127;
BA_ "PF_Sig_Name" SG_ 998 VID_Obj_10_Ang_Overlap_EgoLane_R "BV1_Obj_10_UeberdWnklEgoSpurR";
BA_ "GenSigSendType" SG_ 998 VID_Obj_10_Ang_Overlap_EgoLane_R 0;
BA_ "GenSigStartValue" SG_ 998 VID_Obj_10_Ang_Overlap_EgoLane_R 511;
BA_ "PF_Sig_Name" SG_ 998 VID_Obj_10_Ang_Overlap_EgoLane_L "BV1_Obj_10_UeberdWnklEgoSpurL";
BA_ "GenSigSendType" SG_ 998 VID_Obj_10_Ang_Overlap_EgoLane_L 0;
BA_ "GenSigStartValue" SG_ 998 VID_Obj_10_Ang_Overlap_EgoLane_L 511;
BA_ "PF_Sig_Name" SG_ 998 VID_Obj_10_Obj_Age "BV1_Obj_10_Alter";
BA_ "GenSigSendType" SG_ 998 VID_Obj_10_Obj_Age 0;
BA_ "GenSigStartValue" SG_ 998 VID_Obj_10_Obj_Age 4095;
BA_ "PF_Sig_Name" SG_ 998 VID_Obj_10_BrakeLight "BV1_Obj_10_BremsLicht";
BA_ "GenSigSendType" SG_ 998 VID_Obj_10_BrakeLight 0;
BA_ "PF_Sig_Name" SG_ 999 VID_Obj_10_D_ChkSum "BV_Obj_10_D_CRC";
BA_ "GenSigSendType" SG_ 999 VID_Obj_10_D_ChkSum 0;
BA_ "GenSigFuncType" SG_ 999 VID_Obj_10_D_ChkSum 2;
BA_ "PF_Sig_Name" SG_ 999 VID_Obj_10_D_MsgCnt "BV_Obj_10_D_BZ";
BA_ "GenSigSendType" SG_ 999 VID_Obj_10_D_MsgCnt 0;
BA_ "GenSigFuncType" SG_ 999 VID_Obj_10_D_MsgCnt 1;
BA_ "PF_Sig_Name" SG_ 999 VID_Obj_10_D_BlockCnt "BV1_Obj_10_D_BlockZaehler";
BA_ "GenSigSendType" SG_ 999 VID_Obj_10_D_BlockCnt 3;
BA_ "PF_Sig_Name" SG_ 999 VID_Obj_10_Ang_Edge_L "BV_Objekt_10_phi_left";
BA_ "GenSigSendType" SG_ 999 VID_Obj_10_Ang_Edge_L 0;
BA_ "GenSigStartValue" SG_ 999 VID_Obj_10_Ang_Edge_L 1024;
BA_ "PF_Sig_Name" SG_ 999 VID_Obj_10_Ang_Edge_R "BV_Objekt_10_phi_right";
BA_ "GenSigSendType" SG_ 999 VID_Obj_10_Ang_Edge_R 0;
BA_ "GenSigStartValue" SG_ 999 VID_Obj_10_Ang_Edge_R 1024;
BA_ "PF_Sig_Name" SG_ 999 VID_Obj_10_StdD_Ang_Edge_L "BV_Objekt_10_sdv_phi_left";
BA_ "GenSigSendType" SG_ 999 VID_Obj_10_StdD_Ang_Edge_L 0;
BA_ "GenSigStartValue" SG_ 999 VID_Obj_10_StdD_Ang_Edge_L 512;
BA_ "PF_Sig_Name" SG_ 999 VID_Obj_10_Obj_ID "BV1_Obj_10_ID";
BA_ "GenSigSendType" SG_ 999 VID_Obj_10_Obj_ID 0;
BA_ "GenSigStartValue" SG_ 999 VID_Obj_10_Obj_ID 255;
BA_ "PF_Sig_Name" SG_ 913 VID_Obj_10_E_ChkSum "BV_Obj_10_E_CRC";
BA_ "GenSigSendType" SG_ 913 VID_Obj_10_E_ChkSum 0;
BA_ "GenSigFuncType" SG_ 913 VID_Obj_10_E_ChkSum 2;
BA_ "PF_Sig_Name" SG_ 913 VID_Obj_10_E_MsgCnt "BV_Obj_10_E_BZ";
BA_ "GenSigSendType" SG_ 913 VID_Obj_10_E_MsgCnt 0;
BA_ "GenSigFuncType" SG_ 913 VID_Obj_10_E_MsgCnt 1;
BA_ "PF_Sig_Name" SG_ 913 VID_Obj_10_E_BlockCnt "BV1_Obj_10_E_BlockZaehler";
BA_ "GenSigSendType" SG_ 913 VID_Obj_10_E_BlockCnt 3;
BA_ "PF_Sig_Name" SG_ 913 VID_Obj_10_Velocity_longitudinal "BV1_Obj_10_RadialGeschw";
BA_ "GenSigSendType" SG_ 913 VID_Obj_10_Velocity_longitudinal 0;
BA_ "GenSigStartValue" SG_ 913 VID_Obj_10_Velocity_longitudinal 2046;
BA_ "PF_Sig_Name" SG_ 913 VID_Obj_10_StdD_Velocity_longitu "BV1_Obj_10_RadialGeschw_StdA";
BA_ "GenSigSendType" SG_ 913 VID_Obj_10_StdD_Velocity_longitu 0;
BA_ "GenSigStartValue" SG_ 913 VID_Obj_10_StdD_Velocity_longitu 1022;
BA_ "SystemSignalLongSymbol" SG_ 913 VID_Obj_10_StdD_Velocity_longitu "VID_Obj_10_StdD_Velocity_longitudinal";
BA_ "PF_Sig_Name" SG_ 913 VID_Obj_10_StdD_Ang_Edge_R "BV_Objekt_10_sdv_phi_right";
BA_ "GenSigSendType" SG_ 913 VID_Obj_10_StdD_Ang_Edge_R 0;
BA_ "GenSigStartValue" SG_ 913 VID_Obj_10_StdD_Ang_Edge_R 512;
BA_ "PF_Sig_Name" SG_ 913 VID_Obj_10_ScaleChange "BV_Obj_10_ScaleChange";
BA_ "GenSigSendType" SG_ 913 VID_Obj_10_ScaleChange 0;
BA_ "PF_Sig_Name" SG_ 1000 VID_Obj_11_A_ChkSum "BV_Obj_11_A_CRC";
BA_ "GenSigSendType" SG_ 1000 VID_Obj_11_A_ChkSum 0;
BA_ "GenSigFuncType" SG_ 1000 VID_Obj_11_A_ChkSum 2;
BA_ "PF_Sig_Name" SG_ 1000 VID_Obj_11_A_MsgCnt "BV_Obj_11_A_BZ";
BA_ "GenSigSendType" SG_ 1000 VID_Obj_11_A_MsgCnt 0;
BA_ "GenSigFuncType" SG_ 1000 VID_Obj_11_A_MsgCnt 1;
BA_ "PF_Sig_Name" SG_ 1000 VID_Obj_11_A_BlockCnt "BV1_Obj_11_A_BlockZaehler";
BA_ "GenSigSendType" SG_ 1000 VID_Obj_11_A_BlockCnt 3;
BA_ "PF_Sig_Name" SG_ 1000 VID_Obj_11_Dist_longitude "BV1_Obj_11_Dist_longitude";
BA_ "GenSigSendType" SG_ 1000 VID_Obj_11_Dist_longitude 0;
BA_ "GenSigStartValue" SG_ 1000 VID_Obj_11_Dist_longitude 4095;
BA_ "PF_Sig_Name" SG_ 1000 VID_Obj_11_StdD_Dist_longitude "BV1_Obj_11_Dist_longitudeStdA";
BA_ "GenSigSendType" SG_ 1000 VID_Obj_11_StdD_Dist_longitude 0;
BA_ "GenSigStartValue" SG_ 1000 VID_Obj_11_StdD_Dist_longitude 127;
BA_ "PF_Sig_Name" SG_ 1000 VID_Obj_11_Ang_Center "BV1_Obj_11_WnklMitte";
BA_ "GenSigSendType" SG_ 1000 VID_Obj_11_Ang_Center 0;
BA_ "GenSigStartValue" SG_ 1000 VID_Obj_11_Ang_Center 2047;
BA_ "PF_Sig_Name" SG_ 1000 VID_Obj_11_Stat_Measure "BV1_Obj_11_Gemessen";
BA_ "GenSigSendType" SG_ 1000 VID_Obj_11_Stat_Measure 0;
BA_ "PF_Sig_Name" SG_ 1000 VID_Obj_11_StdD_Ang_Center "BV1_Obj_11_WnklMitteStdA";
BA_ "GenSigSendType" SG_ 1000 VID_Obj_11_StdD_Ang_Center 0;
BA_ "GenSigStartValue" SG_ 1000 VID_Obj_11_StdD_Ang_Center 255;
BA_ "PF_Sig_Name" SG_ 1000 VID_Obj_11_Class "BV1_Obj_11_Klasse";
BA_ "GenSigSendType" SG_ 1000 VID_Obj_11_Class 0;
BA_ "GenSigStartValue" SG_ 1000 VID_Obj_11_Class 15;
BA_ "PF_Sig_Name" SG_ 1000 VID_Obj_11_RefPoint "BV1_Obj_11_Bezugspunkt";
BA_ "GenSigSendType" SG_ 1000 VID_Obj_11_RefPoint 0;
BA_ "GenSigStartValue" SG_ 1000 VID_Obj_11_RefPoint 15;
BA_REL_ "GenSigTimeoutTime" BU_SG_REL_ Radar SG_ 911 VID_Obj_04_D_ChkSum 1000;
BA_REL_ "GenSigTimeoutTime" BU_SG_REL_ Radar SG_ 911 VID_Obj_04_D_MsgCnt 1000;
BA_REL_ "GenSigTimeoutTime" BU_SG_REL_ Radar SG_ 911 VID_Obj_04_D_BlockCnt 1000;
BA_REL_ "GenSigTimeoutTime" BU_SG_REL_ Radar SG_ 911 VID_Obj_04_Ang_Edge_L 1000;
BA_REL_ "GenSigTimeoutTime" BU_SG_REL_ Radar SG_ 911 VID_Obj_04_Ang_Edge_R 1000;
BA_REL_ "GenSigTimeoutTime" BU_SG_REL_ Radar SG_ 911 VID_Obj_04_StdD_Ang_Edge_L 1000;
BA_REL_ "GenSigTimeoutTime" BU_SG_REL_ Radar SG_ 911 VID_Obj_04_Obj_ID 1000;
BA_REL_ "GenSigTimeoutTime" BU_SG_REL_ Radar SG_ 971 VID_Obj_04_E_ChkSum 1000;
BA_REL_ "GenSigTimeoutTime" BU_SG_REL_ Radar SG_ 971 VID_Obj_04_E_MsgCnt 1000;
BA_REL_ "GenSigTimeoutTime" BU_SG_REL_ Radar SG_ 971 VID_Obj_04_E_BlockCnt 1000;
BA_REL_ "GenSigTimeoutTime" BU_SG_REL_ Radar SG_ 971 VID_Obj_04_Velocity_longitudinal 1000;
BA_REL_ "GenSigTimeoutTime" BU_SG_REL_ Radar SG_ 971 VID_Obj_04_StdD_Velocity_longitu 1000;
BA_REL_ "GenSigTimeoutTime" BU_SG_REL_ Radar SG_ 971 VID_Obj_04_StdD_Ang_Edge_R 1000;
BA_REL_ "GenSigTimeoutTime" BU_SG_REL_ Radar SG_ 971 VID_Obj_04_ScaleChange 1000;
BA_REL_ "GenSigTimeoutTime" BU_SG_REL_ Radar SG_ 976 VID_Obj_05_A_ChkSum 1000;
BA_REL_ "GenSigTimeoutTime" BU_SG_REL_ Radar SG_ 976 VID_Obj_05_A_MsgCnt 1000;
BA_REL_ "GenSigTimeoutTime" BU_SG_REL_ Radar SG_ 976 VID_Obj_05_A_BlockCnt 1000;
BA_REL_ "GenSigTimeoutTime" BU_SG_REL_ Radar SG_ 976 VID_Obj_05_Dist_longitude 1000;
BA_REL_ "GenSigTimeoutTime" BU_SG_REL_ Radar SG_ 976 VID_Obj_05_StdD_Dist_longitude 1000;
BA_REL_ "GenSigTimeoutTime" BU_SG_REL_ Radar SG_ 976 VID_Obj_05_Ang_Center 1000;
BA_REL_ "GenSigTimeoutTime" BU_SG_REL_ Radar SG_ 976 VID_Obj_05_Stat_Measure 1000;
BA_REL_ "GenSigTimeoutTime" BU_SG_REL_ Radar SG_ 976 VID_Obj_05_StdD_Ang_Center 1000;
BA_REL_ "GenSigTimeoutTime" BU_SG_REL_ Radar SG_ 976 VID_Obj_05_Class 1000;
BA_REL_ "GenSigTimeoutTime" BU_SG_REL_ Radar SG_ 976 VID_Obj_05_RefPoint 1000;
BA_REL_ "GenSigTimeoutTime" BU_SG_REL_ Radar SG_ 977 VID_Obj_05_B_ChkSum 1000;
BA_REL_ "GenSigTimeoutTime" BU_SG_REL_ Radar SG_ 977 VID_Obj_05_B_MsgCnt 1000;
BA_REL_ "GenSigTimeoutTime" BU_SG_REL_ Radar SG_ 977 VID_Obj_05_B_BlockCnt 1000;
BA_REL_ "GenSigTimeoutTime" BU_SG_REL_ Radar SG_ 977 VID_Obj_05_Ang_Width 1000;
BA_REL_ "GenSigTimeoutTime" BU_SG_REL_ Radar SG_ 977 VID_Obj_05_ProbExist 1000;
BA_REL_ "GenSigTimeoutTime" BU_SG_REL_ Radar SG_ 977 VID_Obj_05_StdD_dAng_longitude 1000;
BA_REL_ "GenSigTimeoutTime" BU_SG_REL_ Radar SG_ 977 VID_Obj_05_dAng_longitude 1000;
BA_REL_ "GenSigTimeoutTime" BU_SG_REL_ Radar SG_ 977 VID_Obj_05_StdD_Ang_Width 1000;
BA_REL_ "GenSigTimeoutTime" BU_SG_REL_ Radar SG_ 978 VID_Obj_05_C_ChkSum 1000;
BA_REL_ "GenSigTimeoutTime" BU_SG_REL_ Radar SG_ 978 VID_Obj_05_C_MsgCnt 1000;
BA_REL_ "GenSigTimeoutTime" BU_SG_REL_ Radar SG_ 978 VID_Obj_05_C_BlockCnt 1000;
BA_REL_ "GenSigTimeoutTime" BU_SG_REL_ Radar SG_ 978 VID_Obj_05_InvTTC 1000;
BA_REL_ "GenSigTimeoutTime" BU_SG_REL_ Radar SG_ 978 VID_Obj_05_StdD_InvTTC 1000;
BA_REL_ "GenSigTimeoutTime" BU_SG_REL_ Radar SG_ 978 VID_Obj_05_Ang_Overlap_EgoLane_R 1000;
BA_REL_ "GenSigTimeoutTime" BU_SG_REL_ Radar SG_ 978 VID_Obj_05_Ang_Overlap_EgoLane_L 1000;
BA_REL_ "GenSigTimeoutTime" BU_SG_REL_ Radar SG_ 978 VID_Obj_05_Obj_Age 1000;
BA_REL_ "GenSigTimeoutTime" BU_SG_REL_ Radar SG_ 978 VID_Obj_05_BrakeLight 1000;
BA_REL_ "GenSigTimeoutTime" BU_SG_REL_ Radar SG_ 979 VID_Obj_05_D_ChkSum 1000;
BA_REL_ "GenSigTimeoutTime" BU_SG_REL_ Radar SG_ 979 VID_Obj_05_D_MsgCnt 1000;
BA_REL_ "GenSigTimeoutTime" BU_SG_REL_ Radar SG_ 979 VID_Obj_05_D_BlockCnt 1000;
BA_REL_ "GenSigTimeoutTime" BU_SG_REL_ Radar SG_ 979 VID_Obj_05_Ang_Edge_L 1000;
BA_REL_ "GenSigTimeoutTime" BU_SG_REL_ Radar SG_ 979 VID_Obj_05_Ang_Edge_R 1000;
BA_REL_ "GenSigTimeoutTime" BU_SG_REL_ Radar SG_ 979 VID_Obj_05_StdD_Ang_Edge_L 1000;
BA_REL_ "GenSigTimeoutTime" BU_SG_REL_ Radar SG_ 979 VID_Obj_05_Obj_ID 1000;
BA_REL_ "GenSigTimeoutTime" BU_SG_REL_ Radar SG_ 972 VID_Obj_05_E_ChkSum 1000;
BA_REL_ "GenSigTimeoutTime" BU_SG_REL_ Radar SG_ 972 VID_Obj_05_E_MsgCnt 1000;
BA_REL_ "GenSigTimeoutTime" BU_SG_REL_ Radar SG_ 972 VID_Obj_05_E_BlockCnt 1000;
BA_REL_ "GenSigTimeoutTime" BU_SG_REL_ Radar SG_ 972 VID_Obj_05_Velocity_longitudinal 1000;
BA_REL_ "GenSigTimeoutTime" BU_SG_REL_ Radar SG_ 972 VID_Obj_05_StdD_Velocity_longitu 1000;
BA_REL_ "GenSigTimeoutTime" BU_SG_REL_ Radar SG_ 972 VID_Obj_05_StdD_Ang_Edge_R 1000;
BA_REL_ "GenSigTimeoutTime" BU_SG_REL_ Radar SG_ 972 VID_Obj_05_ScaleChange 1000;
BA_REL_ "GenSigTimeoutTime" BU_SG_REL_ Radar SG_ 980 VID_Obj_06_A_ChkSum 1000;
BA_REL_ "GenSigTimeoutTime" BU_SG_REL_ Radar SG_ 980 VID_Obj_06_A_MsgCnt 1000;
BA_REL_ "GenSigTimeoutTime" BU_SG_REL_ Radar SG_ 980 VID_Obj_06_A_BlockCnt 1000;
BA_REL_ "GenSigTimeoutTime" BU_SG_REL_ Radar SG_ 980 VID_Obj_06_Dist_longitude 1000;
BA_REL_ "GenSigTimeoutTime" BU_SG_REL_ Radar SG_ 980 VID_Obj_06_StdD_Dist_longitude 1000;
BA_REL_ "GenSigTimeoutTime" BU_SG_REL_ Radar SG_ 980 VID_Obj_06_Ang_Center 1000;
BA_REL_ "GenSigTimeoutTime" BU_SG_REL_ Radar SG_ 980 VID_Obj_06_Stat_Measure 1000;
BA_REL_ "GenSigTimeoutTime" BU_SG_REL_ Radar SG_ 980 VID_Obj_06_StdD_Ang_Center 1000;
BA_REL_ "GenSigTimeoutTime" BU_SG_REL_ Radar SG_ 980 VID_Obj_06_Class 1000;
BA_REL_ "GenSigTimeoutTime" BU_SG_REL_ Radar SG_ 980 VID_Obj_06_RefPoint 1000;
BA_REL_ "GenSigTimeoutTime" BU_SG_REL_ Radar SG_ 981 VID_Obj_06_B_ChkSum 1000;
BA_REL_ "GenSigTimeoutTime" BU_SG_REL_ Radar SG_ 981 VID_Obj_06_B_MsgCnt 1000;
BA_REL_ "GenSigTimeoutTime" BU_SG_REL_ Radar SG_ 981 VID_Obj_06_B_BlockCnt 1000;
BA_REL_ "GenSigTimeoutTime" BU_SG_REL_ Radar SG_ 981 VID_Obj_06_Ang_Width 1000;
BA_REL_ "GenSigTimeoutTime" BU_SG_REL_ Radar SG_ 981 VID_Obj_06_ProbExist 1000;
BA_REL_ "GenSigTimeoutTime" BU_SG_REL_ Radar SG_ 981 VID_Obj_06_StdD_dAng_longitude 1000;
BA_REL_ "GenSigTimeoutTime" BU_SG_REL_ Radar SG_ 981 VID_Obj_06_dAng_longitude 1000;
BA_REL_ "GenSigTimeoutTime" BU_SG_REL_ Radar SG_ 981 VID_Obj_06_StdD_Ang_Width 1000;
BA_REL_ "GenSigTimeoutTime" BU_SG_REL_ Radar SG_ 982 VID_Obj_06_C_ChkSum 1000;
BA_REL_ "GenSigTimeoutTime" BU_SG_REL_ Radar SG_ 982 VID_Obj_06_C_MsgCnt 1000;
BA_REL_ "GenSigTimeoutTime" BU_SG_REL_ Radar SG_ 982 VID_Obj_06_C_BlockCnt 1000;
BA_REL_ "GenSigTimeoutTime" BU_SG_REL_ Radar SG_ 982 VID_Obj_06_InvTTC 1000;
BA_REL_ "GenSigTimeoutTime" BU_SG_REL_ Radar SG_ 982 VID_Obj_06_StdD_InvTTC 1000;
BA_REL_ "GenSigTimeoutTime" BU_SG_REL_ Radar SG_ 982 VID_Obj_06_Ang_Overlap_EgoLane_R 1000;
BA_REL_ "GenSigTimeoutTime" BU_SG_REL_ Radar SG_ 982 VID_Obj_06_Ang_Overlap_EgoLane_L 1000;
BA_REL_ "GenSigTimeoutTime" BU_SG_REL_ Radar SG_ 982 VID_Obj_06_Obj_Age 1000;
BA_REL_ "GenSigTimeoutTime" BU_SG_REL_ Radar SG_ 982 VID_Obj_06_BrakeLight 1000;
BA_REL_ "GenSigTimeoutTime" BU_SG_REL_ Radar SG_ 983 VID_Obj_06_D_ChkSum 1000;
BA_REL_ "GenSigTimeoutTime" BU_SG_REL_ Radar SG_ 983 VID_Obj_06_D_MsgCnt 1000;
BA_REL_ "GenSigTimeoutTime" BU_SG_REL_ Radar SG_ 983 VID_Obj_06_D_BlockCnt 1000;
BA_REL_ "GenSigTimeoutTime" BU_SG_REL_ Radar SG_ 983 VID_Obj_06_Ang_Edge_L 1000;
BA_REL_ "GenSigTimeoutTime" BU_SG_REL_ Radar SG_ 983 VID_Obj_06_Ang_Edge_R 1000;
BA_REL_ "GenSigTimeoutTime" BU_SG_REL_ Radar SG_ 983 VID_Obj_06_StdD_Ang_Edge_L 1000;
BA_REL_ "GenSigTimeoutTime" BU_SG_REL_ Radar SG_ 983 VID_Obj_06_Obj_ID 1000;
BA_REL_ "GenSigTimeoutTime" BU_SG_REL_ Radar SG_ 973 VID_Obj_06_E_ChkSum 1000;
BA_REL_ "GenSigTimeoutTime" BU_SG_REL_ Radar SG_ 973 VID_Obj_06_E_MsgCnt 1000;
BA_REL_ "GenSigTimeoutTime" BU_SG_REL_ Radar SG_ 973 VID_Obj_06_E_BlockCnt 1000;
BA_REL_ "GenSigTimeoutTime" BU_SG_REL_ Radar SG_ 973 VID_Obj_06_Velocity_longitudinal 1000;
BA_REL_ "GenSigTimeoutTime" BU_SG_REL_ Radar SG_ 973 VID_Obj_06_StdD_Velocity_longitu 1000;
BA_REL_ "GenSigTimeoutTime" BU_SG_REL_ Radar SG_ 973 VID_Obj_06_StdD_Ang_Edge_R 1000;
BA_REL_ "GenSigTimeoutTime" BU_SG_REL_ Radar SG_ 973 VID_Obj_06_ScaleChange 1000;
BA_REL_ "GenSigTimeoutTime" BU_SG_REL_ Radar SG_ 984 VID_Obj_07_A_ChkSum 1000;
BA_REL_ "GenSigTimeoutTime" BU_SG_REL_ Radar SG_ 984 VID_Obj_07_A_MsgCnt 1000;
BA_REL_ "GenSigTimeoutTime" BU_SG_REL_ Radar SG_ 984 VID_Obj_07_A_BlockCnt 1000;
BA_REL_ "GenSigTimeoutTime" BU_SG_REL_ Radar SG_ 984 VID_Obj_07_Dist_longitude 1000;
BA_REL_ "GenSigTimeoutTime" BU_SG_REL_ Radar SG_ 984 VID_Obj_07_StdD_Dist_longitude 1000;
BA_REL_ "GenSigTimeoutTime" BU_SG_REL_ Radar SG_ 984 VID_Obj_07_Ang_Center 1000;
BA_REL_ "GenSigTimeoutTime" BU_SG_REL_ Radar SG_ 984 VID_Obj_07_Stat_Measure 1000;
BA_REL_ "GenSigTimeoutTime" BU_SG_REL_ Radar SG_ 984 VID_Obj_07_StdD_Ang_Center 1000;
BA_REL_ "GenSigTimeoutTime" BU_SG_REL_ Radar SG_ 984 VID_Obj_07_Class 1000;
BA_REL_ "GenSigTimeoutTime" BU_SG_REL_ Radar SG_ 984 VID_Obj_07_RefPoint 1000;
BA_REL_ "GenSigTimeoutTime" BU_SG_REL_ Radar SG_ 985 VID_Obj_07_B_ChkSum 1000;
BA_REL_ "GenSigTimeoutTime" BU_SG_REL_ Radar SG_ 985 VID_Obj_07_B_MsgCnt 1000;
BA_REL_ "GenSigTimeoutTime" BU_SG_REL_ Radar SG_ 985 VID_Obj_07_B_BlockCnt 1000;
BA_REL_ "GenSigTimeoutTime" BU_SG_REL_ Radar SG_ 985 VID_Obj_07_Ang_Width 1000;
BA_REL_ "GenSigTimeoutTime" BU_SG_REL_ Radar SG_ 985 VID_Obj_07_ProbExist 1000;
BA_REL_ "GenSigTimeoutTime" BU_SG_REL_ Radar SG_ 985 VID_Obj_07_StdD_dAng_longitude 1000;
BA_REL_ "GenSigTimeoutTime" BU_SG_REL_ Radar SG_ 985 VID_Obj_07_dAng_longitude 1000;
BA_REL_ "GenSigTimeoutTime" BU_SG_REL_ Radar SG_ 985 VID_Obj_07_StdD_Ang_Width 1000;
BA_REL_ "GenSigTimeoutTime" BU_SG_REL_ Radar SG_ 986 VID_Obj_07_C_ChkSum 1000;
BA_REL_ "GenSigTimeoutTime" BU_SG_REL_ Radar SG_ 986 VID_Obj_07_C_MsgCnt 1000;
BA_REL_ "GenSigTimeoutTime" BU_SG_REL_ Radar SG_ 986 VID_Obj_07_C_BlockCnt 1000;
BA_REL_ "GenSigTimeoutTime" BU_SG_REL_ Radar SG_ 986 VID_Obj_07_InvTTC 1000;
BA_REL_ "GenSigTimeoutTime" BU_SG_REL_ Radar SG_ 986 VID_Obj_07_StdD_InvTTC 1000;
BA_REL_ "GenSigTimeoutTime" BU_SG_REL_ Radar SG_ 986 VID_Obj_07_Ang_Overlap_EgoLane_R 1000;
BA_REL_ "GenSigTimeoutTime" BU_SG_REL_ Radar SG_ 986 VID_Obj_07_Ang_Overlap_EgoLane_L 1000;
BA_REL_ "GenSigTimeoutTime" BU_SG_REL_ Radar SG_ 986 VID_Obj_07_Obj_Age 1000;
BA_REL_ "GenSigTimeoutTime" BU_SG_REL_ Radar SG_ 986 VID_Obj_07_BrakeLight 1000;
BA_REL_ "GenSigTimeoutTime" BU_SG_REL_ Radar SG_ 987 VID_Obj_07_D_ChkSum 1000;
BA_REL_ "GenSigTimeoutTime" BU_SG_REL_ Radar SG_ 987 VID_Obj_07_D_MsgCnt 1000;
BA_REL_ "GenSigTimeoutTime" BU_SG_REL_ Radar SG_ 987 VID_Obj_07_D_BlockCnt 1000;
BA_REL_ "GenSigTimeoutTime" BU_SG_REL_ Radar SG_ 987 VID_Obj_07_Ang_Edge_L 1000;
BA_REL_ "GenSigTimeoutTime" BU_SG_REL_ Radar SG_ 987 VID_Obj_07_Ang_Edge_R 1000;
BA_REL_ "GenSigTimeoutTime" BU_SG_REL_ Radar SG_ 987 VID_Obj_07_StdD_Ang_Edge_L 1000;
BA_REL_ "GenSigTimeoutTime" BU_SG_REL_ Radar SG_ 987 VID_Obj_07_Obj_ID 1000;
BA_REL_ "GenSigTimeoutTime" BU_SG_REL_ Radar SG_ 974 VID_Obj_07_E_ChkSum 1000;
BA_REL_ "GenSigTimeoutTime" BU_SG_REL_ Radar SG_ 974 VID_Obj_07_E_MsgCnt 1000;
BA_REL_ "GenSigTimeoutTime" BU_SG_REL_ Radar SG_ 974 VID_Obj_07_E_BlockCnt 1000;
BA_REL_ "GenSigTimeoutTime" BU_SG_REL_ Radar SG_ 974 VID_Obj_07_Velocity_longitudinal 1000;
BA_REL_ "GenSigTimeoutTime" BU_SG_REL_ Radar SG_ 974 VID_Obj_07_StdD_Velocity_longitu 1000;
BA_REL_ "GenSigTimeoutTime" BU_SG_REL_ Radar SG_ 974 VID_Obj_07_StdD_Ang_Edge_R 1000;
BA_REL_ "GenSigTimeoutTime" BU_SG_REL_ Radar SG_ 974 VID_Obj_07_ScaleChange 1000;
BA_REL_ "GenSigTimeoutTime" BU_SG_REL_ Radar SG_ 988 VID_Obj_08_A_ChkSum 1000;
BA_REL_ "GenSigTimeoutTime" BU_SG_REL_ Radar SG_ 988 VID_Obj_08_A_MsgCnt 1000;
BA_REL_ "GenSigTimeoutTime" BU_SG_REL_ Radar SG_ 988 VID_Obj_08_A_BlockCnt 1000;
BA_REL_ "GenSigTimeoutTime" BU_SG_REL_ Radar SG_ 988 VID_Obj_08_Dist_longitude 1000;
BA_REL_ "GenSigTimeoutTime" BU_SG_REL_ Radar SG_ 988 VID_Obj_08_StdD_Dist_longitude 1000;
BA_REL_ "GenSigTimeoutTime" BU_SG_REL_ Radar SG_ 988 VID_Obj_08_Ang_Center 1000;
BA_REL_ "GenSigTimeoutTime" BU_SG_REL_ Radar SG_ 988 VID_Obj_08_Stat_Measure 1000;
BA_REL_ "GenSigTimeoutTime" BU_SG_REL_ Radar SG_ 988 VID_Obj_08_StdD_Ang_Center 1000;
BA_REL_ "GenSigTimeoutTime" BU_SG_REL_ Radar SG_ 988 VID_Obj_08_Class 1000;
BA_REL_ "GenSigTimeoutTime" BU_SG_REL_ Radar SG_ 988 VID_Obj_08_RefPoint 1000;
BA_REL_ "GenSigTimeoutTime" BU_SG_REL_ Radar SG_ 989 VID_Obj_08_B_ChkSum 1000;
BA_REL_ "GenSigTimeoutTime" BU_SG_REL_ Radar SG_ 989 VID_Obj_08_B_MsgCnt 1000;
BA_REL_ "GenSigTimeoutTime" BU_SG_REL_ Radar SG_ 989 VID_Obj_08_B_BlockCnt 1000;
BA_REL_ "GenSigTimeoutTime" BU_SG_REL_ Radar SG_ 989 VID_Obj_08_Ang_Width 1000;
BA_REL_ "GenSigTimeoutTime" BU_SG_REL_ Radar SG_ 989 VID_Obj_08_ProbExist 1000;
BA_REL_ "GenSigTimeoutTime" BU_SG_REL_ Radar SG_ 989 VID_Obj_08_StdD_dAng_longitude 1000;
BA_REL_ "GenSigTimeoutTime" BU_SG_REL_ Radar SG_ 989 VID_Obj_08_dAng_longitude 1000;
BA_REL_ "GenSigTimeoutTime" BU_SG_REL_ Radar SG_ 989 VID_Obj_08_StdD_Ang_Width 1000;
BA_REL_ "GenSigTimeoutTime" BU_SG_REL_ Radar SG_ 990 VID_Obj_08_C_ChkSum 1000;
BA_REL_ "GenSigTimeoutTime" BU_SG_REL_ Radar SG_ 990 VID_Obj_08_C_MsgCnt 1000;
BA_REL_ "GenSigTimeoutTime" BU_SG_REL_ Radar SG_ 990 VID_Obj_08_C_BlockCnt 1000;
BA_REL_ "GenSigTimeoutTime" BU_SG_REL_ Radar SG_ 990 VID_Obj_08_InvTTC 1000;
BA_REL_ "GenSigTimeoutTime" BU_SG_REL_ Radar SG_ 990 VID_Obj_08_StdD_InvTTC 1000;
BA_REL_ "GenSigTimeoutTime" BU_SG_REL_ Radar SG_ 990 VID_Obj_08_Ang_Overlap_EgoLane_R 1000;
BA_REL_ "GenSigTimeoutTime" BU_SG_REL_ Radar SG_ 990 VID_Obj_08_Ang_Overlap_EgoLane_L 1000;
BA_REL_ "GenSigTimeoutTime" BU_SG_REL_ Radar SG_ 990 VID_Obj_08_Obj_Age 1000;
BA_REL_ "GenSigTimeoutTime" BU_SG_REL_ Radar SG_ 990 VID_Obj_08_BrakeLight 1000;
BA_REL_ "GenSigTimeoutTime" BU_SG_REL_ Radar SG_ 991 VID_Obj_08_D_ChkSum 1000;
BA_REL_ "GenSigTimeoutTime" BU_SG_REL_ Radar SG_ 991 VID_Obj_08_D_MsgCnt 1000;
BA_REL_ "GenSigTimeoutTime" BU_SG_REL_ Radar SG_ 991 VID_Obj_08_D_BlockCnt 1000;
BA_REL_ "GenSigTimeoutTime" BU_SG_REL_ Radar SG_ 991 VID_Obj_08_Ang_Edge_L 1000;
BA_REL_ "GenSigTimeoutTime" BU_SG_REL_ Radar SG_ 991 VID_Obj_08_Ang_Edge_R 1000;
BA_REL_ "GenSigTimeoutTime" BU_SG_REL_ Radar SG_ 991 VID_Obj_08_StdD_Ang_Edge_L 1000;
BA_REL_ "GenSigTimeoutTime" BU_SG_REL_ Radar SG_ 991 VID_Obj_08_Obj_ID 1000;
BA_REL_ "GenSigTimeoutTime" BU_SG_REL_ Radar SG_ 975 VID_Obj_08_E_ChkSum 1000;
BA_REL_ "GenSigTimeoutTime" BU_SG_REL_ Radar SG_ 975 VID_Obj_08_E_MsgCnt 1000;
BA_REL_ "GenSigTimeoutTime" BU_SG_REL_ Radar SG_ 975 VID_Obj_08_E_BlockCnt 1000;
BA_REL_ "GenSigTimeoutTime" BU_SG_REL_ Radar SG_ 975 VID_Obj_08_Velocity_longitudinal 1000;
BA_REL_ "GenSigTimeoutTime" BU_SG_REL_ Radar SG_ 975 VID_Obj_08_StdD_Velocity_longitu 1000;
BA_REL_ "GenSigTimeoutTime" BU_SG_REL_ Radar SG_ 975 VID_Obj_08_StdD_Ang_Edge_R 1000;
BA_REL_ "GenSigTimeoutTime" BU_SG_REL_ Radar SG_ 975 VID_Obj_08_ScaleChange 1000;
BA_REL_ "GenSigTimeoutTime" BU_SG_REL_ Radar SG_ 992 VID_Obj_09_A_ChkSum 1000;
BA_REL_ "GenSigTimeoutTime" BU_SG_REL_ Radar SG_ 992 VID_Obj_09_A_MsgCnt 1000;
BA_REL_ "GenSigTimeoutTime" BU_SG_REL_ Radar SG_ 992 VID_Obj_09_A_BlockCnt 1000;
BA_REL_ "GenSigTimeoutTime" BU_SG_REL_ Radar SG_ 992 VID_Obj_09_Dist_longitude 1000;
BA_REL_ "GenSigTimeoutTime" BU_SG_REL_ Radar SG_ 992 VID_Obj_09_StdD_Dist_longitude 1000;
BA_REL_ "GenSigTimeoutTime" BU_SG_REL_ Radar SG_ 992 VID_Obj_09_Ang_Center 1000;
BA_REL_ "GenSigTimeoutTime" BU_SG_REL_ Radar SG_ 992 VID_Obj_09_Stat_Measure 1000;
BA_REL_ "GenSigTimeoutTime" BU_SG_REL_ Radar SG_ 992 VID_Obj_09_StdD_Ang_Center 1000;
BA_REL_ "GenSigTimeoutTime" BU_SG_REL_ Radar SG_ 992 VID_Obj_09_Class 1000;
BA_REL_ "GenSigTimeoutTime" BU_SG_REL_ Radar SG_ 992 VID_Obj_09_RefPoint 1000;
BA_REL_ "GenSigTimeoutTime" BU_SG_REL_ Radar SG_ 993 VID_Obj_09_B_ChkSum 1000;
BA_REL_ "GenSigTimeoutTime" BU_SG_REL_ Radar SG_ 993 VID_Obj_09_B_MsgCnt 1000;
BA_REL_ "GenSigTimeoutTime" BU_SG_REL_ Radar SG_ 993 VID_Obj_09_B_BlockCnt 1000;
BA_REL_ "GenSigTimeoutTime" BU_SG_REL_ Radar SG_ 993 VID_Obj_09_Ang_Width 1000;
BA_REL_ "GenSigTimeoutTime" BU_SG_REL_ Radar SG_ 993 VID_Obj_09_ProbExist 1000;
BA_REL_ "GenSigTimeoutTime" BU_SG_REL_ Radar SG_ 993 VID_Obj_09_StdD_dAng_longitude 1000;
BA_REL_ "GenSigTimeoutTime" BU_SG_REL_ Radar SG_ 993 VID_Obj_09_dAng_longitude 1000;
BA_REL_ "GenSigTimeoutTime" BU_SG_REL_ Radar SG_ 993 VID_Obj_09_StdD_Ang_Width 1000;
BA_REL_ "GenSigTimeoutTime" BU_SG_REL_ Radar SG_ 994 VID_Obj_09_C_ChkSum 1000;
BA_REL_ "GenSigTimeoutTime" BU_SG_REL_ Radar SG_ 994 VID_Obj_09_C_MsgCnt 1000;
BA_REL_ "GenSigTimeoutTime" BU_SG_REL_ Radar SG_ 994 VID_Obj_09_C_BlockCnt 1000;
BA_REL_ "GenSigTimeoutTime" BU_SG_REL_ Radar SG_ 994 VID_Obj_09_InvTTC 1000;
BA_REL_ "GenSigTimeoutTime" BU_SG_REL_ Radar SG_ 994 VID_Obj_09_StdD_InvTTC 1000;
BA_REL_ "GenSigTimeoutTime" BU_SG_REL_ Radar SG_ 994 VID_Obj_09_Ang_Overlap_EgoLane_R 1000;
BA_REL_ "GenSigTimeoutTime" BU_SG_REL_ Radar SG_ 994 VID_Obj_09_Ang_Overlap_EgoLane_L 1000;
BA_REL_ "GenSigTimeoutTime" BU_SG_REL_ Radar SG_ 994 VID_Obj_09_Obj_Age 1000;
BA_REL_ "GenSigTimeoutTime" BU_SG_REL_ Radar SG_ 994 VID_Obj_09_BrakeLight 1000;
BA_REL_ "GenSigTimeoutTime" BU_SG_REL_ Radar SG_ 995 VID_Obj_09_D_ChkSum 1000;
BA_REL_ "GenSigTimeoutTime" BU_SG_REL_ Radar SG_ 995 VID_Obj_09_D_MsgCnt 1000;
BA_REL_ "GenSigTimeoutTime" BU_SG_REL_ Radar SG_ 995 VID_Obj_09_D_BlockCnt 1000;
BA_REL_ "GenSigTimeoutTime" BU_SG_REL_ Radar SG_ 995 VID_Obj_09_Ang_Edge_L 1000;
BA_REL_ "GenSigTimeoutTime" BU_SG_REL_ Radar SG_ 995 VID_Obj_09_Ang_Edge_R 1000;
BA_REL_ "GenSigTimeoutTime" BU_SG_REL_ Radar SG_ 995 VID_Obj_09_StdD_Ang_Edge_L 1000;
BA_REL_ "GenSigTimeoutTime" BU_SG_REL_ Radar SG_ 995 VID_Obj_09_Obj_ID 1000;
BA_REL_ "GenSigTimeoutTime" BU_SG_REL_ Radar SG_ 912 VID_Obj_09_E_ChkSum 1000;
BA_REL_ "GenSigTimeoutTime" BU_SG_REL_ Radar SG_ 912 VID_Obj_09_E_MsgCnt 1000;
BA_REL_ "GenSigTimeoutTime" BU_SG_REL_ Radar SG_ 912 VID_Obj_09_E_BlockCnt 1000;
BA_REL_ "GenSigTimeoutTime" BU_SG_REL_ Radar SG_ 912 VID_Obj_09_Velocity_longitudinal 1000;
BA_REL_ "GenSigTimeoutTime" BU_SG_REL_ Radar SG_ 912 VID_Obj_09_StdD_Velocity_longitu 1000;
BA_REL_ "GenSigTimeoutTime" BU_SG_REL_ Radar SG_ 912 VID_Obj_09_StdD_Ang_Edge_R 1000;
BA_REL_ "GenSigTimeoutTime" BU_SG_REL_ Radar SG_ 912 VID_Obj_09_ScaleChange 1000;
BA_REL_ "GenSigTimeoutTime" BU_SG_REL_ Radar SG_ 996 VID_Obj_10_A_ChkSum 1000;
BA_REL_ "GenSigTimeoutTime" BU_SG_REL_ Radar SG_ 996 VID_Obj_10_A_MsgCnt 1000;
BA_REL_ "GenSigTimeoutTime" BU_SG_REL_ Radar SG_ 996 VID_Obj_10_A_BlockCnt 1000;
BA_REL_ "GenSigTimeoutTime" BU_SG_REL_ Radar SG_ 996 VID_Obj_10_Dist_longitude 1000;
BA_REL_ "GenSigTimeoutTime" BU_SG_REL_ Radar SG_ 996 VID_Obj_10_StdD_Dist_longitude 1000;
BA_REL_ "GenSigTimeoutTime" BU_SG_REL_ Radar SG_ 996 VID_Obj_10_Ang_Center 1000;
BA_REL_ "GenSigTimeoutTime" BU_SG_REL_ Radar SG_ 996 VID_Obj_10_Stat_Measure 1000;
BA_REL_ "GenSigTimeoutTime" BU_SG_REL_ Radar SG_ 996 VID_Obj_10_StdD_Ang_Center 1000;
BA_REL_ "GenSigTimeoutTime" BU_SG_REL_ Radar SG_ 996 VID_Obj_10_Class 1000;
BA_REL_ "GenSigTimeoutTime" BU_SG_REL_ Radar SG_ 996 VID_Obj_10_RefPoint 1000;
BA_REL_ "GenSigTimeoutTime" BU_SG_REL_ Radar SG_ 997 VID_Obj_10_B_ChkSum 1000;
BA_REL_ "GenSigTimeoutTime" BU_SG_REL_ Radar SG_ 997 VID_Obj_10_B_MsgCnt 1000;
BA_REL_ "GenSigTimeoutTime" BU_SG_REL_ Radar SG_ 997 VID_Obj_10_B_BlockCnt 1000;
BA_REL_ "GenSigTimeoutTime" BU_SG_REL_ Radar SG_ 997 VID_Obj_10_Ang_Width 1000;
BA_REL_ "GenSigTimeoutTime" BU_SG_REL_ Radar SG_ 997 VID_Obj_10_ProbExist 1000;
BA_REL_ "GenSigTimeoutTime" BU_SG_REL_ Radar SG_ 997 VID_Obj_10_StdD_dAng_longitude 1000;
BA_REL_ "GenSigTimeoutTime" BU_SG_REL_ Radar SG_ 997 VID_Obj_10_dAng_longitude 1000;
BA_REL_ "GenSigTimeoutTime" BU_SG_REL_ Radar SG_ 997 VID_Obj_10_StdD_Ang_Width 1000;
BA_REL_ "GenSigTimeoutTime" BU_SG_REL_ Radar SG_ 998 VID_Obj_10_C_ChkSum 1000;
BA_REL_ "GenSigTimeoutTime" BU_SG_REL_ Radar SG_ 998 VID_Obj_10_C_MsgCnt 1000;
BA_REL_ "GenSigTimeoutTime" BU_SG_REL_ Radar SG_ 998 VID_Obj_10_C_BlockCnt 1000;
BA_REL_ "GenSigTimeoutTime" BU_SG_REL_ Radar SG_ 998 VID_Obj_10_InvTTC 1000;
BA_REL_ "GenSigTimeoutTime" BU_SG_REL_ Radar SG_ 998 VID_Obj_10_StdD_InvTTC 1000;
BA_REL_ "GenSigTimeoutTime" BU_SG_REL_ Radar SG_ 998 VID_Obj_10_Ang_Overlap_EgoLane_R 1000;
BA_REL_ "GenSigTimeoutTime" BU_SG_REL_ Radar SG_ 998 VID_Obj_10_Ang_Overlap_EgoLane_L 1000;
BA_REL_ "GenSigTimeoutTime" BU_SG_REL_ Radar SG_ 998 VID_Obj_10_Obj_Age 1000;
BA_REL_ "GenSigTimeoutTime" BU_SG_REL_ Radar SG_ 998 VID_Obj_10_BrakeLight 1000;
BA_REL_ "GenSigTimeoutTime" BU_SG_REL_ Radar SG_ 999 VID_Obj_10_D_ChkSum 1000;
BA_REL_ "GenSigTimeoutTime" BU_SG_REL_ Radar SG_ 999 VID_Obj_10_D_MsgCnt 1000;
BA_REL_ "GenSigTimeoutTime" BU_SG_REL_ Radar SG_ 999 VID_Obj_10_D_BlockCnt 1000;
BA_REL_ "GenSigTimeoutTime" BU_SG_REL_ Radar SG_ 999 VID_Obj_10_Ang_Edge_L 1000;
BA_REL_ "GenSigTimeoutTime" BU_SG_REL_ Radar SG_ 999 VID_Obj_10_Ang_Edge_R 1000;
BA_REL_ "GenSigTimeoutTime" BU_SG_REL_ Radar SG_ 999 VID_Obj_10_StdD_Ang_Edge_L 1000;
BA_REL_ "GenSigTimeoutTime" BU_SG_REL_ Radar SG_ 999 VID_Obj_10_Obj_ID 1000;
BA_REL_ "GenSigTimeoutTime" BU_SG_REL_ Radar SG_ 913 VID_Obj_10_E_ChkSum 1000;
BA_REL_ "GenSigTimeoutTime" BU_SG_REL_ Radar SG_ 913 VID_Obj_10_E_MsgCnt 1000;
BA_REL_ "GenSigTimeoutTime" BU_SG_REL_ Radar SG_ 913 VID_Obj_10_E_BlockCnt 1000;
BA_REL_ "GenSigTimeoutTime" BU_SG_REL_ Radar SG_ 913 VID_Obj_10_Velocity_longitudinal 1000;
BA_REL_ "GenSigTimeoutTime" BU_SG_REL_ Radar SG_ 913 VID_Obj_10_StdD_Velocity_longitu 1000;
BA_REL_ "GenSigTimeoutTime" BU_SG_REL_ Radar SG_ 913 VID_Obj_10_StdD_Ang_Edge_R 1000;
BA_REL_ "GenSigTimeoutTime" BU_SG_REL_ Radar SG_ 913 VID_Obj_10_ScaleChange 1000;
BA_REL_ "GenSigTimeoutTime" BU_SG_REL_ Radar SG_ 1000 VID_Obj_11_A_ChkSum 1000;
BA_REL_ "GenSigTimeoutTime" BU_SG_REL_ Radar SG_ 1000 VID_Obj_11_A_MsgCnt 1000;
BA_REL_ "GenSigTimeoutTime" BU_SG_REL_ Radar SG_ 1000 VID_Obj_11_A_BlockCnt 1000;
BA_REL_ "GenSigTimeoutTime" BU_SG_REL_ Radar SG_ 1000 VID_Obj_11_Dist_longitude 1000;
BA_REL_ "GenSigTimeoutTime" BU_SG_REL_ Radar SG_ 1000 VID_Obj_11_StdD_Dist_longitude 1000;
BA_REL_ "GenSigTimeoutTime" BU_SG_REL_ Radar SG_ 1000 VID_Obj_11_Ang_Center 1000;
BA_REL_ "GenSigTimeoutTime" BU_SG_REL_ Radar SG_ 1000 VID_Obj_11_Stat_Measure 1000;
BA_REL_ "GenSigTimeoutTime" BU_SG_REL_ Radar SG_ 1000 VID_Obj_11_StdD_Ang_Center 1000;
BA_REL_ "GenSigTimeoutTime" BU_SG_REL_ Radar SG_ 1000 VID_Obj_11_Class 1000;
BA_REL_ "GenSigTimeoutTime" BU_SG_REL_ Radar SG_ 1000 VID_Obj_11_RefPoint 1000;
VAL_ 911 VID_Obj_04_Obj_ID 0 "no_valid_object" 255 "init" ;
VAL_ 971 VID_Obj_04_Velocity_longitudinal 2046 "init" ;
VAL_ 971 VID_Obj_04_StdD_Velocity_longitu 1022 "init" ;
VAL_ 971 VID_Obj_04_ScaleChange 1023 "undefined" ;
VAL_ 976 VID_Obj_05_Dist_longitude 4095 "init" ;
VAL_ 976 VID_Obj_05_StdD_Dist_longitude 127 "init" ;
VAL_ 976 VID_Obj_05_Ang_Center 2047 "init" ;
VAL_ 976 VID_Obj_05_Stat_Measure 0 "obj_predicted" 1 "obj_measured" 2 "obj_featuretracked" 3 "NR_intruder_or_overtakeing" ;
VAL_ 976 VID_Obj_05_StdD_Ang_Center 255 "init" ;
VAL_ 976 VID_Obj_05_Class 0 "unknown" 1 "overrideable" 2 "underridable" 3 "pedestrian" 4 "pedestrian_multiple" 5 "bicycle" 6 "motorcycle" 7 "passengercar" 8 "van" 9 "heavy_truck" 10 "stationary" 11 "animal" 12 "retroreflector" 15 "init" ;
VAL_ 976 VID_Obj_05_RefPoint 0 "unclassified" 1 "front_left" 2 "front_center" 3 "front_right" 4 "right_side_center" 5 "rear_right" 6 "rear_center" 7 "rear_left" 8 "left_side_center" 9 "center" 15 "init" ;
VAL_ 977 VID_Obj_05_Ang_Width 2047 "init" ;
VAL_ 977 VID_Obj_05_ProbExist 127 "init" ;
VAL_ 977 VID_Obj_05_StdD_dAng_longitude 63 "init" ;
VAL_ 977 VID_Obj_05_dAng_longitude 511 "init" ;
VAL_ 977 VID_Obj_05_StdD_Ang_Width 255 "init" ;
VAL_ 978 VID_Obj_05_InvTTC 1023 "init" ;
VAL_ 978 VID_Obj_05_StdD_InvTTC 127 "init" ;
VAL_ 978 VID_Obj_05_Ang_Overlap_EgoLane_R 511 "init" ;
VAL_ 978 VID_Obj_05_Ang_Overlap_EgoLane_L 511 "init" ;
VAL_ 978 VID_Obj_05_Obj_Age 4095 "init" ;
VAL_ 978 VID_Obj_05_BrakeLight 0 "no_brakelight_detected" 1 "brakelight_detected" ;
VAL_ 979 VID_Obj_05_Obj_ID 0 "no_valid_object" 255 "init" ;
VAL_ 972 VID_Obj_05_Velocity_longitudinal 2046 "init" ;
VAL_ 972 VID_Obj_05_StdD_Velocity_longitu 1022 "init" ;
VAL_ 972 VID_Obj_05_ScaleChange 1023 "undefined" ;
VAL_ 980 VID_Obj_06_Dist_longitude 4095 "init" ;
VAL_ 980 VID_Obj_06_StdD_Dist_longitude 127 "init" ;
VAL_ 980 VID_Obj_06_Ang_Center 2047 "init" ;
VAL_ 980 VID_Obj_06_Stat_Measure 0 "obj_predicted" 1 "obj_measured" 2 "obj_featuretracked" 3 "NR_intruder_or_overtakeing" ;
VAL_ 980 VID_Obj_06_StdD_Ang_Center 255 "init" ;
VAL_ 980 VID_Obj_06_Class 0 "unknown" 1 "overrideable" 2 "underridable" 3 "pedestrian" 4 "pedestrian_multiple" 5 "bicycle" 6 "motorcycle" 7 "passengercar" 8 "van" 9 "heavy_truck" 10 "stationary" 11 "animal" 12 "retroreflector" 15 "init" ;
VAL_ 980 VID_Obj_06_RefPoint 0 "unclassified" 1 "front_left" 2 "front_center" 3 "front_right" 4 "right_side_center" 5 "rear_right" 6 "rear_center" 7 "rear_left" 8 "left_side_center" 9 "center" 15 "init" ;
VAL_ 981 VID_Obj_06_Ang_Width 2047 "init" ;
VAL_ 981 VID_Obj_06_ProbExist 127 "init" ;
VAL_ 981 VID_Obj_06_StdD_dAng_longitude 63 "init" ;
VAL_ 981 VID_Obj_06_dAng_longitude 511 "init" ;
VAL_ 981 VID_Obj_06_StdD_Ang_Width 255 "init" ;
VAL_ 982 VID_Obj_06_InvTTC 1023 "init" ;
VAL_ 982 VID_Obj_06_StdD_InvTTC 127 "init" ;
VAL_ 982 VID_Obj_06_Ang_Overlap_EgoLane_R 511 "init" ;
VAL_ 982 VID_Obj_06_Ang_Overlap_EgoLane_L 511 "init" ;
VAL_ 982 VID_Obj_06_Obj_Age 4095 "init" ;
VAL_ 982 VID_Obj_06_BrakeLight 0 "no_brakelight_detected" 1 "brakelight_detected" ;
VAL_ 983 VID_Obj_06_Obj_ID 0 "no_valid_object" 255 "init" ;
VAL_ 973 VID_Obj_06_Velocity_longitudinal 2046 "init" ;
VAL_ 973 VID_Obj_06_StdD_Velocity_longitu 1022 "init" ;
VAL_ 973 VID_Obj_06_ScaleChange 1023 "undefined" ;
VAL_ 984 VID_Obj_07_Dist_longitude 4095 "init" ;
VAL_ 984 VID_Obj_07_StdD_Dist_longitude 127 "init" ;
VAL_ 984 VID_Obj_07_Ang_Center 2047 "init" ;
VAL_ 984 VID_Obj_07_Stat_Measure 0 "obj_predicted" 1 "obj_measured" 2 "obj_featuretracked" 3 "NR_intruder_or_overtakeing" ;
VAL_ 984 VID_Obj_07_StdD_Ang_Center 255 "init" ;
VAL_ 984 VID_Obj_07_Class 0 "unknown" 1 "overrideable" 2 "underridable" 3 "pedestrian" 4 "pedestrian_multiple" 5 "bicycle" 6 "motorcycle" 7 "passengercar" 8 "van" 9 "heavy_truck" 10 "stationary" 11 "animal" 12 "retroreflector" 15 "init" ;
VAL_ 984 VID_Obj_07_RefPoint 0 "unclassified" 1 "front_left" 2 "front_center" 3 "front_right" 4 "right_side_center" 5 "rear_right" 6 "rear_center" 7 "rear_left" 8 "left_side_center" 9 "center" 15 "init" ;
VAL_ 985 VID_Obj_07_Ang_Width 2047 "init" ;
VAL_ 985 VID_Obj_07_ProbExist 127 "init" ;
VAL_ 985 VID_Obj_07_StdD_dAng_longitude 63 "init" ;
VAL_ 985 VID_Obj_07_dAng_longitude 511 "init" ;
VAL_ 985 VID_Obj_07_StdD_Ang_Width 255 "init" ;
VAL_ 986 VID_Obj_07_InvTTC 1023 "init" ;
VAL_ 986 VID_Obj_07_StdD_InvTTC 127 "init" ;
VAL_ 986 VID_Obj_07_Ang_Overlap_EgoLane_R 511 "init" ;
VAL_ 986 VID_Obj_07_Ang_Overlap_EgoLane_L 511 "init" ;
VAL_ 986 VID_Obj_07_Obj_Age 4095 "init" ;
VAL_ 986 VID_Obj_07_BrakeLight 0 "no_brakelight_detected" 1 "brakelight_detected" ;
VAL_ 987 VID_Obj_07_Obj_ID 0 "no_valid_object" 255 "init" ;
VAL_ 974 VID_Obj_07_Velocity_longitudinal 2046 "init" ;
VAL_ 974 VID_Obj_07_StdD_Velocity_longitu 1022 "init" ;
VAL_ 974 VID_Obj_07_ScaleChange 1023 "undefined" ;
VAL_ 988 VID_Obj_08_Dist_longitude 4095 "init" ;
VAL_ 988 VID_Obj_08_StdD_Dist_longitude 127 "init" ;
VAL_ 988 VID_Obj_08_Ang_Center 2047 "init" ;
VAL_ 988 VID_Obj_08_Stat_Measure 0 "obj_predicted" 1 "obj_measured" 2 "obj_featuretracked" 3 "NR_intruder_or_overtakeing" ;
VAL_ 988 VID_Obj_08_StdD_Ang_Center 255 "init" ;
VAL_ 988 VID_Obj_08_Class 0 "unknown" 1 "overrideable" 2 "underridable" 3 "pedestrian" 4 "pedestrian_multiple" 5 "bicycle" 6 "motorcycle" 7 "passengercar" 8 "van" 9 "heavy_truck" 10 "stationary" 11 "animal" 12 "retroreflector" 15 "init" ;
VAL_ 988 VID_Obj_08_RefPoint 0 "unclassified" 1 "front_left" 2 "front_center" 3 "front_right" 4 "right_side_center" 5 "rear_right" 6 "rear_center" 7 "rear_left" 8 "left_side_center" 9 "center" 15 "init" ;
VAL_ 989 VID_Obj_08_Ang_Width 2047 "init" ;
VAL_ 989 VID_Obj_08_ProbExist 127 "init" ;
VAL_ 989 VID_Obj_08_StdD_dAng_longitude 63 "init" ;
VAL_ 989 VID_Obj_08_dAng_longitude 511 "init" ;
VAL_ 989 VID_Obj_08_StdD_Ang_Width 255 "init" ;
VAL_ 990 VID_Obj_08_InvTTC 1023 "init" ;
VAL_ 990 VID_Obj_08_StdD_InvTTC 127 "init" ;
VAL_ 990 VID_Obj_08_Ang_Overlap_EgoLane_R 511 "init" ;
VAL_ 990 VID_Obj_08_Ang_Overlap_EgoLane_L 511 "init" ;
VAL_ 990 VID_Obj_08_Obj_Age 4095 "init" ;
VAL_ 990 VID_Obj_08_BrakeLight 0 "no_brakelight_detected" 1 "brakelight_detected" ;
VAL_ 991 VID_Obj_08_Obj_ID 0 "no_valid_object" 255 "init" ;
VAL_ 975 VID_Obj_08_Velocity_longitudinal 2046 "init" ;
VAL_ 975 VID_Obj_08_StdD_Velocity_longitu 1022 "init" ;
VAL_ 975 VID_Obj_08_ScaleChange 1023 "undefined" ;
VAL_ 992 VID_Obj_09_Dist_longitude 4095 "init" ;
VAL_ 992 VID_Obj_09_StdD_Dist_longitude 127 "init" ;
VAL_ 992 VID_Obj_09_Ang_Center 2047 "init" ;
VAL_ 992 VID_Obj_09_Stat_Measure 0 "obj_predicted" 1 "obj_measured" 2 "obj_featuretracked" 3 "NR_intruder_or_overtakeing" ;
VAL_ 992 VID_Obj_09_StdD_Ang_Center 255 "init" ;
VAL_ 992 VID_Obj_09_Class 0 "unknown" 1 "overrideable" 2 "underridable" 3 "pedestrian" 4 "pedestrian_multiple" 5 "bicycle" 6 "motorcycle" 7 "passengercar" 8 "van" 9 "heavy_truck" 10 "stationary" 11 "animal" 12 "retroreflector" 15 "init" ;
VAL_ 992 VID_Obj_09_RefPoint 0 "unclassified" 1 "front_left" 2 "front_center" 3 "front_right" 4 "right_side_center" 5 "rear_right" 6 "rear_center" 7 "rear_left" 8 "left_side_center" 9 "center" 15 "init" ;
VAL_ 993 VID_Obj_09_Ang_Width 2047 "init" ;
VAL_ 993 VID_Obj_09_ProbExist 127 "init" ;
VAL_ 993 VID_Obj_09_StdD_dAng_longitude 63 "init" ;
VAL_ 993 VID_Obj_09_dAng_longitude 511 "init" ;
VAL_ 993 VID_Obj_09_StdD_Ang_Width 255 "init" ;
VAL_ 994 VID_Obj_09_InvTTC 1023 "init" ;
VAL_ 994 VID_Obj_09_StdD_InvTTC 127 "init" ;
VAL_ 994 VID_Obj_09_Ang_Overlap_EgoLane_R 511 "init" ;
VAL_ 994 VID_Obj_09_Ang_Overlap_EgoLane_L 511 "init" ;
VAL_ 994 VID_Obj_09_Obj_Age 4095 "init" ;
VAL_ 994 VID_Obj_09_BrakeLight 0 "no_brakelight_detected" 1 "brakelight_detected" ;
VAL_ 995 VID_Obj_09_Obj_ID 0 "no_valid_object" 255 "init" ;
VAL_ 912 VID_Obj_09_Velocity_longitudinal 2046 "init" ;
VAL_ 912 VID_Obj_09_StdD_Velocity_longitu 1022 "init" ;
VAL_ 912 VID_Obj_09_ScaleChange 1023 "undefined" ;
VAL_ 996 VID_Obj_10_Dist_longitude 4095 "init" ;
VAL_ 996 VID_Obj_10_StdD_Dist_longitude 127 "init" ;
VAL_ 996 VID_Obj_10_Ang_Center 2047 "init" ;
VAL_ 996 VID_Obj_10_Stat_Measure 0 "obj_predicted" 1 "obj_measured" 2 "obj_featuretracked" 3 "NR_intruder_or_overtakeing" ;
VAL_ 996 VID_Obj_10_StdD_Ang_Center 255 "init" ;
VAL_ 996 VID_Obj_10_Class 0 "unknown" 1 "overrideable" 2 "underridable" 3 "pedestrian" 4 "pedestrian_multiple" 5 "bicycle" 6 "motorcycle" 7 "passengercar" 8 "van" 9 "heavy_truck" 10 "stationary" 11 "animal" 12 "retroreflector" 15 "init" ;
VAL_ 996 VID_Obj_10_RefPoint 0 "unclassified" 1 "front_left" 2 "front_center" 3 "front_right" 4 "right_side_center" 5 "rear_right" 6 "rear_center" 7 "rear_left" 8 "left_side_center" 9 "center" 15 "init" ;
VAL_ 997 VID_Obj_10_Ang_Width 2047 "init" ;
VAL_ 997 VID_Obj_10_ProbExist 127 "init" ;
VAL_ 997 VID_Obj_10_StdD_dAng_longitude 63 "init" ;
VAL_ 997 VID_Obj_10_dAng_longitude 511 "init" ;
VAL_ 997 VID_Obj_10_StdD_Ang_Width 255 "init" ;
VAL_ 998 VID_Obj_10_InvTTC 1023 "init" ;
VAL_ 998 VID_Obj_10_StdD_InvTTC 127 "init" ;
VAL_ 998 VID_Obj_10_Ang_Overlap_EgoLane_R 511 "init" ;
VAL_ 998 VID_Obj_10_Ang_Overlap_EgoLane_L 511 "init" ;
VAL_ 998 VID_Obj_10_Obj_Age 4095 "init" ;
VAL_ 998 VID_Obj_10_BrakeLight 0 "no_brakelight_detected" 1 "brakelight_detected" ;
VAL_ 999 VID_Obj_10_Obj_ID 0 "no_valid_object" 255 "init" ;
VAL_ 913 VID_Obj_10_Velocity_longitudinal 2046 "init" ;
VAL_ 913 VID_Obj_10_StdD_Velocity_longitu 1022 "init" ;
VAL_ 913 VID_Obj_10_ScaleChange 1023 "undefined" ;
VAL_ 1000 VID_Obj_11_Dist_longitude 4095 "init" ;
VAL_ 1000 VID_Obj_11_StdD_Dist_longitude 127 "init" ;
VAL_ 1000 VID_Obj_11_Ang_Center 2047 "init" ;
VAL_ 1000 VID_Obj_11_Stat_Measure 0 "obj_predicted" 1 "obj_measured" 2 "obj_featuretracked" 3 "NR_intruder_or_overtakeing" ;
VAL_ 1000 VID_Obj_11_StdD_Ang_Center 255 "init" ;
VAL_ 1000 VID_Obj_11_Class 0 "unknown" 1 "overrideable" 2 "underridable" 3 "pedestrian" 4 "pedestrian_multiple" 5 "bicycle" 6 "motorcycle" 7 "passengercar" 8 "van" 9 "heavy_truck" 10 "stationary" 11 "animal" 12 "retroreflector" 15 "init" ;
VAL_ 1000 VID_Obj_11_RefPoint 0 "unclassified" 1 "front_left" 2 "front_center" 3 "front_right" 4 "right_side_center" 5 "rear_right" 6 "rear_center" 7 "rear_left" 8 "left_side_center" 9 "center" 15 "init" ;
